VERSION "HNPBNNNYNNNNNNNNNNNNNNNNNNNNNNNNYNYYYYYYYY>4>%%%/4>'%**4YYY///"

NS_ :

BS_:

BU_: TPM TCM SCCM RF_HUB PTS ORC IC HaLF ETM ESM ESC EPS ECM Diagnost DTCM DASM CBC AFLS ADCM

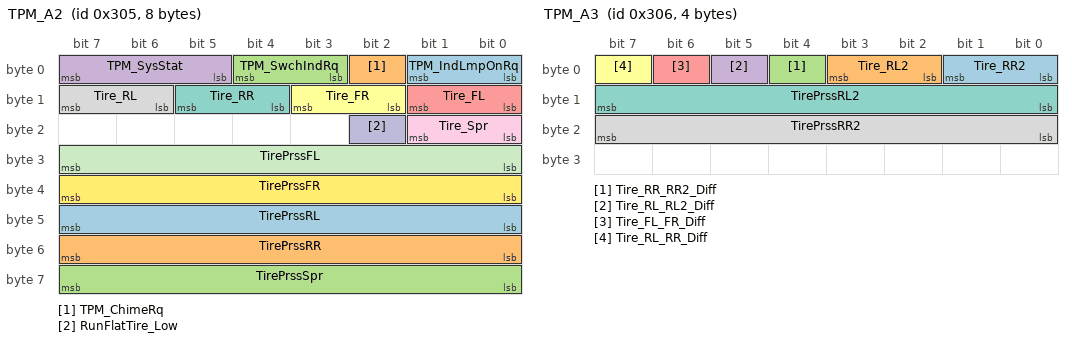
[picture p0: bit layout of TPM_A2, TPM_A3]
BO_ 773 TPM_A2: 8 RF_HUB
 SG_ TPM_IndLmpOnRq : 0|2@1+ (1,0) [0|0] ""  ORC,IC
 SG_ TPM_ChimeRq : 2|1@1+ (1,0) [0|0] ""  ORC,IC
 SG_ TPM_SwchIndRq : 3|2@1+ (1,0) [0|0] ""  ORC,IC
 SG_ TPM_SysStat : 5|3@1+ (1,0) [0|0] ""  ORC,IC
 SG_ Tire_FL : 8|2@1+ (1,0) [0|0] ""  ORC,IC
 SG_ Tire_FR : 10|2@1+ (1,0) [0|0] ""  ORC,IC
 SG_ Tire_RR : 12|2@1+ (1,0) [0|0] ""  ORC,IC
 SG_ Tire_RL : 14|2@1+ (1,0) [0|0] ""  ORC,IC
 SG_ Tire_Spr : 16|2@1+ (1,0) [0|0] ""  ORC,IC
 SG_ RunFlatTire_Low : 18|1@1+ (1,0) [0|0] ""  ORC,IC
 SG_ TirePrssFL : 24|8@1+ (1,0) [0|126] "psi"  ORC,IC
 SG_ TirePrssFR : 32|8@1+ (1,0) [0|126] "psi"  ORC,IC
 SG_ TirePrssRL : 40|8@1+ (1,0) [0|126] "psi"  ORC,IC
 SG_ TirePrssRR : 48|8@1+ (1,0) [0|126] "psi"  ORC,IC
 SG_ TirePrssSpr : 56|8@1+ (1,0) [0|126] "psi"  ORC,IC

BO_ 774 TPM_A3: 4 RF_HUB
 SG_ Tire_RR2 : 0|2@1+ (1,0) [0|0] ""  ORC,IC
 SG_ Tire_RL2 : 2|2@1+ (1,0) [0|0] ""  ORC,IC
 SG_ Tire_RR_RR2_Diff : 4|1@1+ (1,0) [0|0] ""  ORC,IC
 SG_ Tire_RL_RL2_Diff : 5|1@1+ (1,0) [0|0] ""  ORC,IC
 SG_ Tire_FL_FR_Diff : 6|1@1+ (1,0) [0|0] ""  ORC,IC
 SG_ Tire_RL_RR_Diff : 7|1@1+ (1,0) [0|0] ""  ORC,IC
 SG_ TirePrssRL2 : 8|8@1+ (1,0) [0|126] "psi"  ETM,ORC,IC
 SG_ TirePrssRR2 : 16|8@1+ (1,0) [0|126] "psi"  ETM,ORC,IC

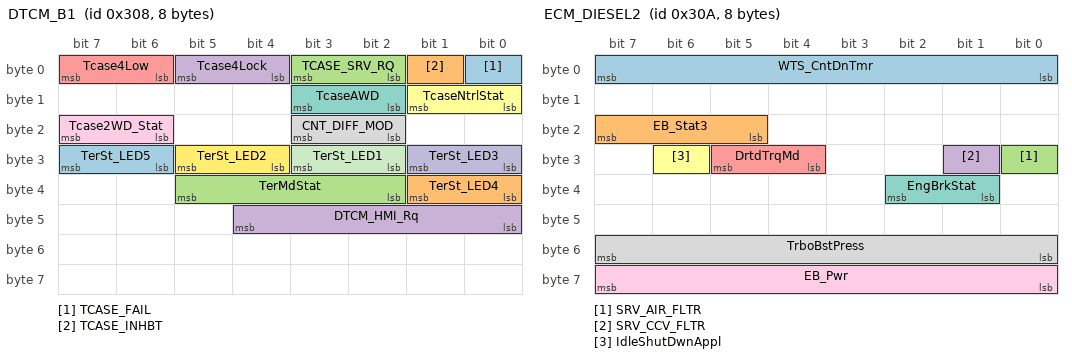
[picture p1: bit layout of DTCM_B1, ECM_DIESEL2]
BO_ 776 DTCM_B1: 8 CBC
 SG_ TCASE_FAIL : 0|1@1+ (1,0) [0|0] ""  ETM,ECM
 SG_ TCASE_INHBT : 1|1@1+ (1,0) [0|0] ""  ETM,IC
 SG_ TCASE_SRV_RQ : 2|2@1+ (1,0) [0|0] ""  ETM,IC
 SG_ Tcase4Lock : 4|2@1+ (1,0) [0|0] ""  ETM,ECM,IC,CBC
 SG_ Tcase4Low : 6|2@1+ (1,0) [0|0] ""  ETM,ECM,IC,CBC
 SG_ TcaseNtrlStat : 8|2@1+ (1,0) [0|0] ""  ETM,ECM,IC,CBC
 SG_ TcaseAWD : 10|2@1+ (1,0) [0|0] ""  ETM,ECM,IC,CBC
 SG_ CNT_DIFF_MOD : 18|2@1+ (1,0) [0|0] ""  ESC
 SG_ Tcase2WD_Stat : 22|2@1+ (1,0) [0|0] ""  ECM,IC,CBC
 SG_ TerSt_LED3 : 24|2@1+ (1,0) [0|0] ""  ETM,IC,CBC
 SG_ TerSt_LED1 : 26|2@1+ (1,0) [0|0] ""  ETM,IC,CBC
 SG_ TerSt_LED2 : 28|2@1+ (1,0) [0|0] ""  ETM,IC,CBC
 SG_ TerSt_LED5 : 30|2@1+ (1,0) [0|0] ""  ETM,IC,CBC
 SG_ TerSt_LED4 : 32|2@1+ (1,0) [0|0] ""  ETM,IC,CBC
 SG_ TerMdStat : 34|4@1+ (1,0) [0|0] ""  ETM,ADCM,TCM,ECM,DASM,ESC,IC,CBC
 SG_ DTCM_HMI_Rq : 40|5@1+ (1,0) [0|0] ""  ECM,IC

BO_ 778 ECM_DIESEL2: 8 Vector__XXX
 SG_ WTS_CntDnTmr : 0|8@1+ (1,0) [0|254] "sec"  IC
 SG_ EB_Stat3 : 21|3@1+ (1,0) [0|0] ""  IC,CBC
 SG_ SRV_AIR_FLTR : 24|1@1+ (1,0) [0|0] ""  IC
 SG_ SRV_CCV_FLTR : 25|1@1+ (1,0) [0|0] ""  IC
 SG_ DrtdTrqMd : 28|2@1+ (1,0) [0|0] ""  IC
 SG_ IdleShutDwnAppl : 30|1@1+ (1,0) [0|0] ""  IC
 SG_ EngBrkStat : 33|2@1+ (1,0) [0|0] ""  ECM
 SG_ TrboBstPress : 48|8@1+ (1,0) [0|250] "kPaG"  IC
 SG_ EB_Pwr : 56|8@1+ (1,0) [0|250] "kW"  IC

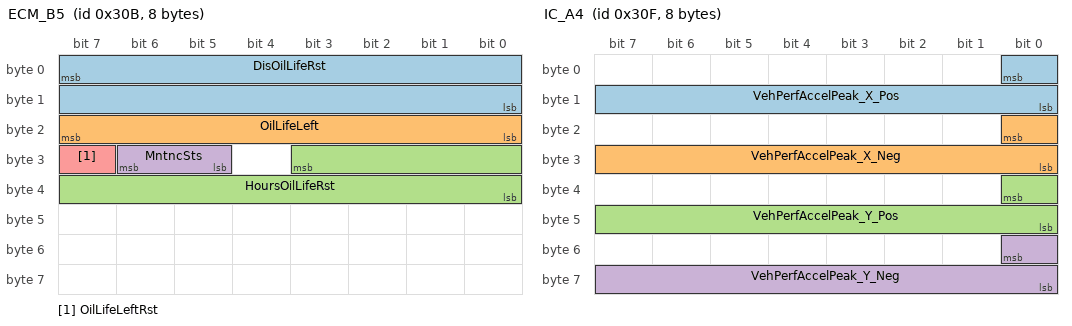
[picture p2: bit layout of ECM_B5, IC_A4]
BO_ 779 ECM_B5: 8 ECM
 SG_ DisOilLifeRst : 7|16@0+ (1,0) [0|65534] "km"  ETM,IC,CBC
 SG_ OilLifeLeft : 16|8@1+ (1,0) [0|100] "%"  ETM,IC
 SG_ HoursOilLifeRst : 27|12@0+ (1,0) [0|4000] "Hours"  ETM,IC,CBC
 SG_ MntncSts : 29|2@1+ (1,0) [0|0] ""  ETM,IC
 SG_ OilLifeLeftRst : 31|1@1+ (1,0) [0|0] ""  ETM,IC,CBC

BO_ 780 EPB_2M: 8 Vector__XXX
 SG_ ActualForce : 7|16@0+ (1,0) [0|65535] "daN"  ESC
 SG_ DiagSessActv : 16|1@1+ (1,0) [0|0] ""  ESC

BO_ 783 IC_A4: 8 IC
 SG_ VehPerfAccelPeak_X_Pos : 0|9@0+ (0.08,0) [0|40.8] "m/s²"  ETM
 SG_ VehPerfAccelPeak_X_Neg : 16|9@0+ (0.08,-40.8) [-40.8|0] "m/s²"  ETM
 SG_ VehPerfAccelPeak_Y_Pos : 32|9@0+ (0.08,0) [0|40.8] "m/s²"  ETM
 SG_ VehPerfAccelPeak_Y_Neg : 48|9@0+ (0.08,-40.8) [-40.8|0] "m/s²"  ETM

BO_ 784 IC_A1: 8 IC
 SG_ AvgFuelLvl : 0|9@0+ (0.5,0) [0|255] "liters"  ETM,ECM,CBC
 SG_ WarnPrio1_Mute_Rq : 1|1@1+ (1,0) [0|0] ""  CBC
 SG_ PCODE_CTRL : 2|2@1+ (1,0) [0|0] ""  ECM
 SG_ SRS_LMP_STAT : 4|2@1+ (1,0) [0|0] ""  ETM,ORC
 SG_ FuelLvlLow : 6|1@1+ (1,0) [0|0] ""  CBC
 SG_ WTS_LmpRqOn : 7|1@1+ (1,0) [0|0] "" Vector__XXX
 SG_ DPF_DEF_WrnStat : 16|4@1+ (1,0) [0|0] ""  ETM
 SG_ Radio_Strng_Rq : 20|1@1+ (1,0) [0|0] ""  CBC
 SG_ FuelSavDispEnbl : 21|1@1+ (1,0) [0|0] ""  CBC
 SG_ ThatchamIC : 22|1@1+ (1,0) [0|0] ""  RF_HUB
 SG_ ACC_ScrnActv : 23|1@1+ (1,0) [0|0] ""  DASM
 SG_ Trailer_Trp_Rst : 28|1@1+ (1,0) [0|0] "" Vector__XXX
 SG_ OilChgRst : 29|1@1+ (1,0) [0|0] ""  ECM
 SG_ FuelFltrRst : 30|1@1+ (1,0) [0|0] "" Vector__XXX
 SG_ ALM_Rq : 31|1@1+ (1,0) [0|0] "" Vector__XXX
 SG_ ODO : 39|24@0+ (0.1,0) [0|1677721.4] "km"  HaLF,ORC,ADCM,DTCM,ESM,TCM,ECM,DASM,ESC,SCCM,EPS,AFLS,TPM,PTS,CBC,RF_HUB
 SG_ PowerMode_RQ : 56|3@1+ (1,0) [0|0] ""  CBC
 SG_ IC_IntrnlFlt : 59|1@1+ (1,0) [0|0] ""  DASM
 SG_ PTS_MODE_SELECTION : 60|3@1+ (1,0) [0|0] ""  PTS

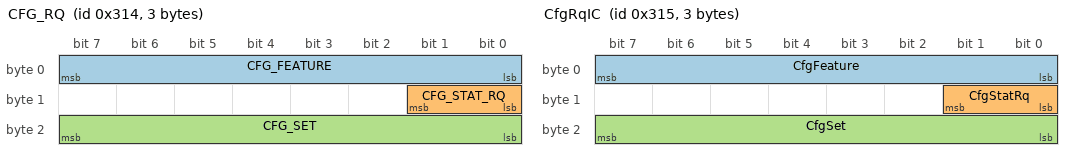
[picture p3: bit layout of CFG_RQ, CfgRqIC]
BO_ 788 CFG_RQ: 3 CBC
 SG_ CFG_FEATURE : 0|8@1+ (1,0) [0|0] ""  HaLF,ECM,DASM,ESC,EPS,AFLS,PTS,IC,RF_HUB
 SG_ CFG_STAT_RQ : 8|2@1+ (1,0) [0|0] ""  HaLF,ECM,DASM,ESC,EPS,AFLS,PTS,IC,RF_HUB
 SG_ CFG_SET : 16|8@1+ (1,0) [0|255] ""  EPS,HaLF,ECM,DASM,ESC,PTS,IC,RF_HUB

BO_ 789 CfgRqIC: 3 Vector__XXX
 SG_ CfgFeature : 0|8@1+ (1,0) [0|0] ""  ORC,AFLS,TPM,CBC
 SG_ CfgStatRq : 8|2@1+ (1,0) [0|0] ""  ORC,AFLS,TPM,CBC
 SG_ CfgSet : 16|8@1+ (1,0) [0|255] ""  AFLS,TPM

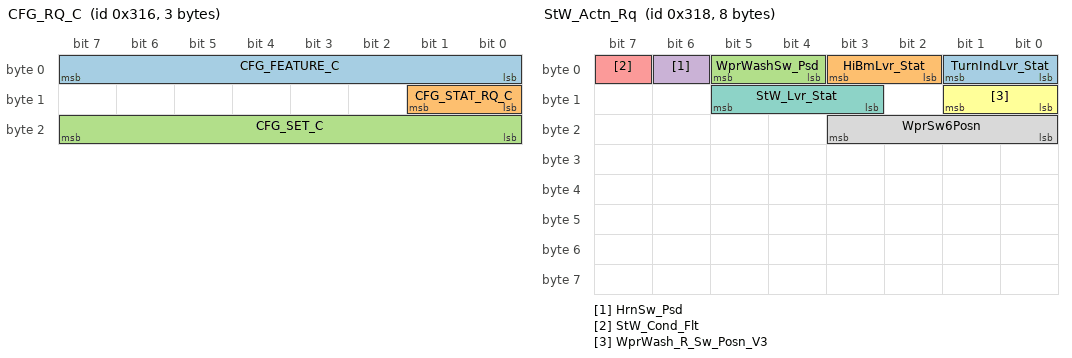
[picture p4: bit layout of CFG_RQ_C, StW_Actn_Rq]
BO_ 790 CFG_RQ_C: 3 IC
 SG_ CFG_FEATURE_C : 0|8@1+ (1,0) [0|0] ""  HaLF,ECM,DASM,ESC,EPS,AFLS,PTS,CBC,RF_HUB
 SG_ CFG_STAT_RQ_C : 8|2@1+ (1,0) [0|0] ""  HaLF,ECM,DASM,ESC,EPS,AFLS,PTS,CBC,RF_HUB
 SG_ CFG_SET_C : 16|8@1+ (1,0) [0|255] ""  EPS,HaLF,ECM,DASM,ESC,PTS,CBC,RF_HUB

BO_ 792 StW_Actn_Rq: 8 SCCM
 SG_ TurnIndLvr_Stat : 0|2@1+ (1,0) [0|0] ""  DASM,PTS,CBC
 SG_ HiBmLvr_Stat : 2|2@1+ (1,0) [0|0] ""  CBC
 SG_ WprWashSw_Psd : 4|2@1+ (1,0) [0|0] ""  AFLS,CBC
 SG_ HrnSw_Psd : 6|1@1+ (1,0) [0|0] ""  CBC
 SG_ StW_Cond_Flt : 7|1@1+ (1,0) [0|0] ""  CBC
 SG_ WprWash_R_Sw_Posn_V3 : 8|2@1+ (1,0) [0|0] ""  CBC
 SG_ StW_Lvr_Stat : 11|3@1+ (1,0) [0|0] ""  PTS,CBC
 SG_ WprSw6Posn : 16|4@1+ (1,0) [0|0] ""  DASM,CBC

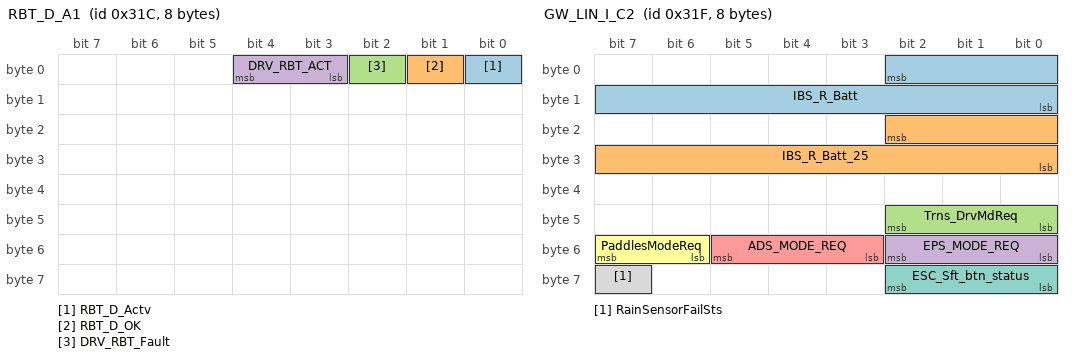
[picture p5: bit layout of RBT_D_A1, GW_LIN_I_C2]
BO_ 796 RBT_D_A1: 8 Vector__XXX
 SG_ RBT_D_Actv : 0|1@1+ (1,0) [0|0] ""  ESC
 SG_ RBT_D_OK : 1|1@1+ (1,0) [0|0] ""  DASM,ESC
 SG_ DRV_RBT_Fault : 2|1@1+ (1,0) [0|0] ""  IC
 SG_ DRV_RBT_ACT : 3|2@1+ (1,0) [0|0] ""  DASM,ESC

BO_ 799 GW_LIN_I_C2: 8 CBC
 SG_ IBS_R_Batt : 2|11@0+ (0.05,0) [0|20] "mOhm" Vector__XXX
 SG_ IBS_R_Batt_25 : 18|11@0+ (0.05,0) [0|20] "mOhm" Vector__XXX
 SG_ Trns_DrvMdReq : 40|3@1+ (1,0) [0|0] ""  TCM,IC
 SG_ EPS_MODE_REQ : 48|3@1+ (1,0) [0|0] ""  EPS,IC
 SG_ ADS_MODE_REQ : 51|3@1+ (1,0) [0|0] ""  ADCM,IC
 SG_ PaddlesModeReq : 54|2@1+ (1,0) [0|0] ""  TCM,IC
 SG_ ESC_Sft_btn_status : 56|3@1+ (1,0) [0|0] ""  ESC,IC
 SG_ RainSensorFailSts : 63|1@1+ (1,0) [0|0] ""  ETM,IC

BO_ 800 ECM_B9: 8 ECM
 SG_ PSI_Max_RPM : 3|5@1+ (250,500) [500|7500] "rpm"  ETM

BO_ 804 CBC_PT4: 8 CBC
 SG_ MOOD_LGT_INTS : 0|8@1+ (0.5,0) [0|100] "%"  IC
 SG_ WTS_Active : 8|1@1+ (1,0) [0|0] ""  RF_HUB
 SG_ CBC_WTS_AS : 9|1@1+ (1,0) [0|0] ""  IC
 SG_ HdAjar : 10|1@1+ (1,0) [0|0] "" Vector__XXX
 SG_ HdAjar_Rt : 11|1@1+ (1,0) [0|0] "" Vector__XXX
 SG_ LgtSensInt_Flt : 12|1@1+ (1,0) [0|0] ""  IC
 SG_ TurnLmp_FL_Flt : 13|1@1+ (1,0) [0|0] ""  IC
 SG_ TurnLmp_FR_Flt : 14|1@1+ (1,0) [0|0] ""  IC
 SG_ BrkPadWearStat : 15|1@1+ (1,0) [0|0] "" Vector__XXX
 SG_ AirSusp_UpSw : 16|2@1+ (1,0) [0|0] "" Vector__XXX
 SG_ AirSusp_DnSw : 18|2@1+ (1,0) [0|0] "" Vector__XXX
 SG_ DAY_LGT_Act : 20|1@1+ (1,0) [0|0] ""  HaLF,AFLS
 SG_ ExteriorRearReleaseSwitchSts : 21|1@1+ (1,0) [0|0] ""  RF_HUB
 SG_ SpStSwPsd : 22|2@1+ (1,0) [0|0] ""  ECM
 SG_ TurnLmp_RL_Flt : 24|1@1+ (1,0) [0|0] ""  IC
 SG_ TurnLmp_RR_Flt : 25|1@1+ (1,0) [0|0] ""  IC
 SG_ ACC_DLY_ACT : 26|1@1+ (1,0) [0|0] ""  SCCM,IC
 SG_ CargoLampOn : 27|1@1+ (1,0) [0|0] ""  IC
 SG_ HL_SW_Position : 28|2@1+ (1,0) [0|0] ""  HaLF
 SG_ ML_HDLP_LVL : 30|2@1+ (1,0) [0|0] "" Vector__XXX
 SG_ RemSt_Inhibit : 32|8@1+ (1,0) [0|0] ""  ETM,IC
 SG_ WPR_SYS_OFF : 40|1@1+ (1,0) [0|0] ""  HaLF,DTCM,DASM,ESC,AFLS
 SG_ WPR_SYS_LOW : 41|1@1+ (1,0) [0|0] ""  HaLF,DTCM,DASM,ESC,AFLS
 SG_ WPR_SYS_HIGH : 42|1@1+ (1,0) [0|0] ""  HaLF,DTCM,DASM,ESC,AFLS
 SG_ WPR_SYS_INT : 43|1@1+ (1,0) [0|0] ""  HaLF,DTCM,DASM,ESC,AFLS
 SG_ WPR_SYS_AUTO : 44|1@1+ (1,0) [0|0] ""  HaLF,DTCM,DASM,ESC,AFLS
 SG_ WPR_SYS_MIST : 45|1@1+ (1,0) [0|0] ""  HaLF,DTCM,DASM,ESC,AFLS
 SG_ WPR_SYS_WASH : 46|1@1+ (1,0) [0|0] ""  HaLF,DTCM,DASM,ESC,AFLS
 SG_ WPR_SYS_FLT : 47|1@1+ (1,0) [0|0] ""  HaLF,DTCM,DASM,ESC,AFLS
 SG_ Court_Lmp : 48|8@1+ (0.5,0) [0|100] "%"  RF_HUB
 SG_ DriveStyleSts : 56|3@1+ (1,0) [0|0] ""  IC
 SG_ DrvMdRq : 59|3@1+ (1,0) [0|0] ""  ORC,ADCM,DTCM,TCM
 SG_ ManMdRq : 62|2@1+ (1,0) [0|0] ""  TCM

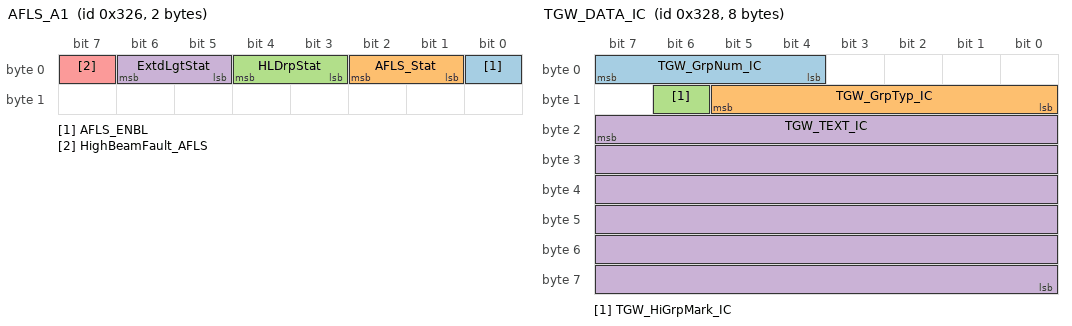
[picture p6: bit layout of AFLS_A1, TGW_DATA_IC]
BO_ 806 AFLS_A1: 2 AFLS
 SG_ AFLS_ENBL : 0|1@1+ (1,0) [0|0] ""  IC,CBC
 SG_ AFLS_Stat : 1|2@1+ (1,0) [0|0] ""  IC
 SG_ HLDrpStat : 3|2@1+ (1,0) [0|0] ""  IC,CBC
 SG_ ExtdLgtStat : 5|2@1+ (1,0) [0|0] "" Vector__XXX
 SG_ HighBeamFault_AFLS : 7|1@1+ (1,0) [0|0] ""  CBC

BO_ 808 TGW_DATA_IC: 8 CBC
 SG_ TGW_GrpNum_IC : 4|4@1+ (1,1) [1|16] "Group"  IC
 SG_ TGW_GrpTyp_IC : 8|6@1+ (1,0) [1|40] "Text"  IC
 SG_ TGW_HiGrpMark_IC : 14|1@1+ (1,0) [0|0] ""  IC
 SG_ TGW_TEXT_IC : 23|48@0+ (1,0) [0|0] ""  IC

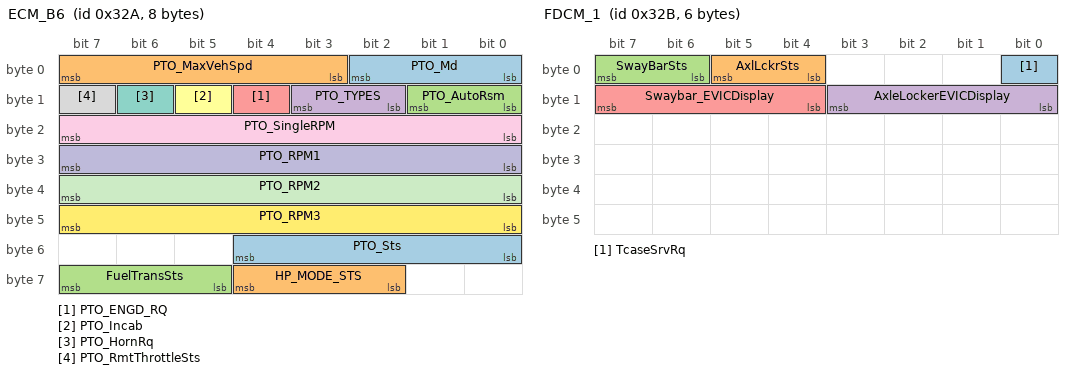
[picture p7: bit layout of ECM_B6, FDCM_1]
BO_ 810 ECM_B6: 8 ECM
 SG_ PTO_Md : 0|3@1+ (1,0) [0|0] ""  IC,CBC
 SG_ PTO_MaxVehSpd : 3|5@1+ (1,0) [0|0] ""  IC,CBC
 SG_ PTO_AutoRsm : 8|2@1+ (1,0) [0|0] ""  IC,CBC
 SG_ PTO_TYPES : 10|2@1+ (1,0) [0|0] ""  IC,CBC
 SG_ PTO_ENGD_RQ : 12|1@1+ (1,0) [0|0] ""  IC,CBC
 SG_ PTO_Incab : 13|1@1+ (1,0) [0|0] ""  IC,CBC
 SG_ PTO_HornRq : 14|1@1+ (1,0) [0|0] ""  CBC
 SG_ PTO_RmtThrottleSts : 15|1@1+ (1,0) [0|0] ""  IC,CBC
 SG_ PTO_SingleRPM : 16|8@1+ (25,600) [600|6950] "rpm"  IC,CBC
 SG_ PTO_RPM1 : 24|8@1+ (25,600) [600|6950] "rpm"  IC,CBC
 SG_ PTO_RPM2 : 32|8@1+ (25,600) [600|6950] "rpm"  IC,CBC
 SG_ PTO_RPM3 : 40|8@1+ (25,600) [600|6950] "rpm"  IC,CBC
 SG_ PTO_Sts : 48|5@1+ (1,0) [0|0] ""  IC,CBC
 SG_ HP_MODE_STS : 58|3@1+ (1,0) [0|0] ""  TCM,CBC
 SG_ FuelTransSts : 61|3@1+ (1,0) [0|0] ""  IC

BO_ 811 FDCM_1: 6 Vector__XXX
 SG_ TcaseSrvRq : 0|1@1+ (1,0) [0|0] ""  IC
 SG_ AxlLckrSts : 4|2@1+ (1,0) [0|0] ""  IC
 SG_ SwayBarSts : 6|2@1+ (1,0) [0|0] ""  IC
 SG_ AxleLockerEVICDisplay : 8|4@1+ (1,0) [0|0] ""  IC
 SG_ Swaybar_EVICDisplay : 12|4@1+ (1,0) [0|0] ""  IC

BO_ 816 GW_I_C1: 8 CBC
 SG_ PLG_Stat : 0|4@1+ (1,0) [0|0] ""  IC
 SG_ DL_Lim_Stat : 4|2@1+ (1,0) [0|0] ""  IC
 SG_ TILT_IN_REV_D : 6|1@1+ (1,0) [0|0] ""  IC
 SG_ TILT_IN_REV_P : 7|1@1+ (1,0) [0|0] ""  IC
 SG_ EModeSwPsd : 8|2@1+ (1,0) [0|0] ""  TCM,ECM
 SG_ EB_SW_PSD : 10|1@1+ (1,0) [0|0] "" Vector__XXX
 SG_ CHIME_STS_RF : 11|1@1+ (1,0) [0|0] ""  DASM,PTS
 SG_ CHIME_STS_LF : 12|1@1+ (1,0) [0|0] ""  DASM,PTS
 SG_ CHIME_STS_RR : 13|1@1+ (1,0) [0|0] ""  DASM,PTS
 SG_ CHIME_STS_LR : 14|1@1+ (1,0) [0|0] ""  DASM,PTS
 SG_ ADCM_Sw_Psd : 15|1@1+ (1,0) [0|0] ""  ADCM,PTS
 SG_ TCASE_SFT_RQ : 16|3@1+ (1,0) [0|0] ""  DTCM,PTS
 SG_ TRAC_PSD : 19|1@1+ (1,0) [0|0] ""  ESC,PTS
 SG_ HILL_DES_RQ : 20|2@1+ (1,0) [0|0] ""  ESC
 SG_ AddTurnLmp_Flt_D : 22|1@1+ (1,0) [0|0] ""  IC
 SG_ AddTurnLmp_Flt_P : 23|1@1+ (1,0) [0|0] ""  IC
 SG_ US_METRIC : 24|1@1+ (1,0) [0|0] ""  ECM,DASM,IC
 SG_ LANG : 25|4@1+ (1,0) [0|0] ""  IC
 SG_ PLG_Req_PE : 31|1@1+ (1,0) [0|0] ""  RF_HUB
 SG_ TGW_DISP_STAT : 32|4@1+ (1,0) [0|0] ""  IC
 SG_ AHB_ENBL : 36|1@1+ (1,0) [0|0] ""  IC
 SG_ PassWinLO_Enbl : 37|1@1+ (1,0) [0|0] ""  IC
 SG_ RemStEnbl_DCS : 38|1@1+ (1,0) [0|0] ""  IC
 SG_ RemStNrmlStEnbl_DCS : 39|1@1+ (1,0) [0|0] ""  IC
 SG_ HVAC_CLNT_FLW_MIN : 40|8@1+ (0.521555,0) [0|132.475] "LpM"  ECM
 SG_ ICS_btn41 : 48|2@1+ (1,0) [0|0] ""  TCM
 SG_ ICS_btn_34 : 50|1@1+ (1,0) [0|0] ""  ECM
 SG_ ICS_btn_16 : 51|1@1+ (1,0) [0|0] ""  PTS
 SG_ ICS_btn_17 : 52|1@1+ (1,0) [0|0] ""  PTS
 SG_ ICS_btn_18 : 53|1@1+ (1,0) [0|0] "" Vector__XXX
 SG_ ICS_btn_19 : 54|1@1+ (1,0) [0|0] ""  DASM
 SG_ DriveModeReq_Cluster : 56|4@1+ (1,0) [0|0] ""  IC

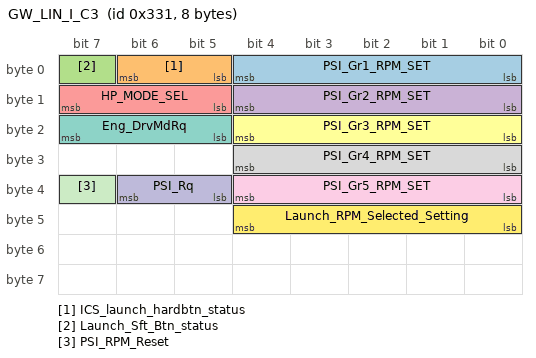
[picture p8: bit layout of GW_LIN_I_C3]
BO_ 817 GW_LIN_I_C3: 8 CBC
 SG_ PSI_Gr1_RPM_SET : 0|5@1+ (250,500) [500|7500] "rpm"  ECM
 SG_ ICS_launch_hardbtn_status : 5|2@1+ (1,0) [0|0] ""  ESC
 SG_ Launch_Sft_Btn_status : 7|1@1+ (1,0) [0|0] ""  ESC
 SG_ PSI_Gr2_RPM_SET : 8|5@1+ (250,500) [500|7500] "rpm"  ECM
 SG_ HP_MODE_SEL : 13|3@1+ (1,0) [0|0] ""  ECM,IC
 SG_ PSI_Gr3_RPM_SET : 16|5@1+ (250,500) [500|7500] "rpm"  ECM
 SG_ Eng_DrvMdRq : 21|3@1+ (1,0) [0|0] ""  ECM
 SG_ PSI_Gr4_RPM_SET : 24|5@1+ (250,500) [500|7500] "rpm"  ECM
 SG_ PSI_Gr5_RPM_SET : 32|5@1+ (250,500) [500|7500] "rpm"  ECM
 SG_ PSI_Rq : 37|2@1+ (1,0) [0|0] ""  ECM
 SG_ PSI_RPM_Reset : 39|1@1+ (1,0) [0|0] ""  ECM
 SG_ Launch_RPM_Selected_Setting : 40|5@1+ (250,1000) [1000|7000] "rpm"  ESC

CM_ SG_ 773 TPM_IndLmpOnRq "Tire pressure indication request";
CM_ SG_ 773 TPM_ChimeRq "TPM chime request";
CM_ SG_ 773 TPM_SwchIndRq "TPM load switch indicator request";
CM_ SG_ 773 TPM_SysStat "TPM system localization status";
CM_ SG_ 773 Tire_FL "Tire front left";
CM_ SG_ 773 Tire_FR "Tire front right";
CM_ SG_ 773 Tire_RR "Tire rear right";
CM_ SG_ 773 Tire_RL "Tire rear left";
CM_ SG_ 773 Tire_Spr "Spare tire";
CM_ SG_ 773 RunFlatTire_Low "Run flat tire low pressure; true = [1]";
CM_ SG_ 773 TirePrssFL "Tire pressure front left";
CM_ SG_ 773 TirePrssFR "Tire pressure front right";
CM_ SG_ 773 TirePrssRL "Tire pressure rear left";
CM_ SG_ 773 TirePrssRR "Tire pressure rear right";
CM_ SG_ 773 TirePrssSpr "Tire pressure spare tire";
CM_ SG_ 774 Tire_RR2 "Tire rear right inside on dually";
CM_ SG_ 774 Tire_RL2 "Tire rear left inside on dually";
CM_ SG_ 774 Tire_RR_RR2_Diff "Tire pressure differential rear right inner to outer";
CM_ SG_ 774 Tire_RL_RL2_Diff "Tire pressure differential rear left inner to outer";
CM_ SG_ 774 Tire_FL_FR_Diff "Tire pressure differential front left to front right";
CM_ SG_ 774 Tire_RL_RR_Diff "Tire pressure differential rear left to rear right";
CM_ SG_ 774 TirePrssRL2 "Tire pressure rear left inside on dually";
CM_ SG_ 774 TirePrssRR2 "Tire pressure rear right inside on dually";
CM_ SG_ 776 TCASE_FAIL "T Case System Fault (Limp in)";
CM_ SG_ 776 TCASE_INHBT "All wheel drive mode inhibited";
CM_ SG_ 776 TCASE_SRV_RQ "Transfer case service indicator request";
CM_ SG_ 776 Tcase4Lock "Transfer case 4WD locked status";
CM_ SG_ 776 Tcase4Low "Transfer case low range LED status";
CM_ SG_ 776 TcaseNtrlStat "Transfer case neutral LED status";
CM_ SG_ 776 TcaseAWD "Transfer case High range / AWD LED status";
CM_ SG_ 776 CNT_DIFF_MOD "Actual mode of center differential";
CM_ SG_ 776 Tcase2WD_Stat "Transfer case 2 wheel drive status";
CM_ SG_ 776 TerSt_LED3 "Terrain Switch LED 3 Status";
CM_ SG_ 776 TerSt_LED1 "Terrain Switch LED 1 (left / counterclockwise most) Status";
CM_ SG_ 776 TerSt_LED2 "Terrain Switch LED 2 Status";
CM_ SG_ 776 TerSt_LED5 "Terrain Switch LED 5 (right / clockwise most) Status";
CM_ SG_ 776 TerSt_LED4 "Terrain Switch LED 4 Status";
CM_ SG_ 776 TerMdStat "Terrain mode status";
CM_ SG_ 776 DTCM_HMI_Rq "DTCM AWD / 4WD HMI display request";
CM_ SG_ 778 WTS_CntDnTmr "Wait to start count down timer (sec)";
CM_ SG_ 778 EB_Stat3 "Exhaust brake status - 3 bit";
CM_ SG_ 778 SRV_AIR_FLTR "Service air Filter";
CM_ SG_ 778 SRV_CCV_FLTR "Service CCV Filter";
CM_ SG_ 778 DrtdTrqMd "Derated torque mode";
CM_ SG_ 778 IdleShutDwnAppl "Idle Shut down applied";
CM_ SG_ 778 EngBrkStat "Engine braking status";
CM_ SG_ 778 TrboBstPress "Turbo boost pressure";
CM_ SG_ 778 EB_Pwr "Exhaust brake Power";
CM_ SG_ 779 DisOilLifeRst "Distance since last oil life reset";
CM_ SG_ 779 OilLifeLeft "Oil life left";
CM_ SG_ 779 HoursOilLifeRst "Hours since last oil life reset";
CM_ SG_ 779 MntncSts "Maintenance reminder status";
CM_ SG_ 779 OilLifeLeftRst "Oil life remaining has been reset";
CM_ SG_ 780 ActualForce "Actual force";
CM_ SG_ 780 DiagSessActv "Diagnostic session active; Active = [1]";
CM_ SG_ 783 VehPerfAccelPeak_X_Pos "Vehicle longitudinal acceleration peak (forward)";
CM_ SG_ 783 VehPerfAccelPeak_X_Neg "Vehicle longitudinal acceleration peak (rearward)";
CM_ SG_ 783 VehPerfAccelPeak_Y_Pos "Vehicle longitudinal acceleration peak (left)";
CM_ SG_ 783 VehPerfAccelPeak_Y_Neg "Vehicle longitudinal acceleration peak (right)";
CM_ SG_ 784 AvgFuelLvl "Average filtered fuel level in liters";
CM_ SG_ 784 WarnPrio1_Mute_Rq "Priority 1 mute request for soundamplifier";
CM_ SG_ 784 PCODE_CTRL "P-Code control signal from CCN";
CM_ SG_ 784 SRS_LMP_STAT "Airbag indicator lamp status";
CM_ SG_ 784 FuelLvlLow "Fuel level low";
CM_ SG_ 784 WTS_LmpRqOn "Wait to start lamp requested on; true = [1]";
CM_ SG_ 784 DPF_DEF_WrnStat "DPF DEF warning status";
CM_ SG_ 784 Radio_Strng_Rq "IC request for Audio to resend radio string information";
CM_ SG_ 784 FuelSavDispEnbl "Fuel saver display indicator status (1=enabled)";
CM_ SG_ 784 ThatchamIC "IC has learned the presence of Thatcham; true = [1]";
CM_ SG_ 784 ACC_ScrnActv "IC adaptive cruise in active display; True = [1]";
CM_ SG_ 784 Trailer_Trp_Rst "Trailer Trip Reset Request";
CM_ SG_ 784 OilChgRst "Oil change reminder reset request";
CM_ SG_ 784 FuelFltrRst "Fuel filter maintenance reminder reset";
CM_ SG_ 784 ALM_Rq "Auto load measurement request; On = [1]";
CM_ SG_ 784 ODO "Odometer";
CM_ SG_ 784 PowerMode_RQ "Power Mode request";
CM_ SG_ 784 IC_IntrnlFlt "Cluster internal fault active";
CM_ SG_ 784 PTS_MODE_SELECTION "Park assist maneuver selection for PTS";
CM_ SG_ 788 CFG_FEATURE "Configurable feature";
CM_ SG_ 788 CFG_STAT_RQ "Configurable feature status request";
CM_ SG_ 788 CFG_SET "Specific setting or value (see reference)";
CM_ SG_ 789 CfgFeature "Configurable feature";
CM_ SG_ 789 CfgStatRq "Configurable feature status request";
CM_ SG_ 789 CfgSet "Specific setting or value (see reference)";
CM_ SG_ 790 CFG_FEATURE_C "Configurable feature";
CM_ SG_ 790 CFG_STAT_RQ_C "Configurable feature status request";
CM_ SG_ 790 CFG_SET_C "Specific setting or value (see reference)";
CM_ SG_ 792 TurnIndLvr_Stat "Turn indicator lever state";
CM_ SG_ 792 HiBmLvr_Stat "High beam lever state";
CM_ SG_ 792 WprWashSw_Psd "Front wiper switch pressed";
CM_ SG_ 792 HrnSw_Psd "Horn switch pressed (1=pressed)";
CM_ SG_ 792 StW_Cond_Flt "Steering wheel conditioning fault";
CM_ SG_ 792 WprWash_R_Sw_Posn_V3 "Backlite wiper/washer switch position";
CM_ SG_ 792 StW_Lvr_Stat "Steering wheel lever state";
CM_ SG_ 792 WprSw6Posn "Wiper switch (6 stages) position";
CM_ SG_ 796 RBT_D_Actv "Reversible belt tensioner driver active; True = [1]";
CM_ SG_ 796 RBT_D_OK "Reversible belt tensioner driver is OK; True = [1]";
CM_ SG_ 796 DRV_RBT_Fault "Driver's RBT has a fault or failure; True = [1]";
CM_ SG_ 796 DRV_RBT_ACT "Indicates the pre-pretensioner is activated either by the DASM or ESC";
CM_ SG_ 799 IBS_R_Batt "Calculated battery resistance";
CM_ SG_ 799 IBS_R_Batt_25 "Batt resistance at 100% SOC and 25 degC";
CM_ SG_ 799 Trns_DrvMdReq "The requested state of the drive mode feature";
CM_ SG_ 799 EPS_MODE_REQ "EPS mode personalization request";
CM_ SG_ 799 ADS_MODE_REQ "Active damping system mode personalization request";
CM_ SG_ 799 PaddlesModeReq "Requested state of paddle lock-out function";
CM_ SG_ 799 ESC_Sft_btn_status "ESC mode personalization request";
CM_ SG_ 799 RainSensorFailSts "Fail present = 1";
CM_ SG_ 800 PSI_Max_RPM "Maximum selectable RPM for PSI feature";
CM_ SG_ 804 MOOD_LGT_INTS "Mood lighting intensity (ambient & glow rings)";
CM_ SG_ 804 WTS_Active "Indicates WTS feature is active";
CM_ SG_ 804 CBC_WTS_AS "WTS automatic start is active";
CM_ SG_ 804 HdAjar "Hood latch ajar, left or single (1=ajar)";
CM_ SG_ 804 HdAjar_Rt "Hood latch ajar, right (1=ajar)";
CM_ SG_ 804 LgtSensInt_Flt "Light sensor internal fault";
CM_ SG_ 804 TurnLmp_FL_Flt "Turn indication lamp front left fault";
CM_ SG_ 804 TurnLmp_FR_Flt "Turn indication lamp front right fault";
CM_ SG_ 804 BrkPadWearStat "Disable fuel shutoff";
CM_ SG_ 804 AirSusp_UpSw "Air suspension up switch status";
CM_ SG_ 804 AirSusp_DnSw "Air suspension down (Trailer) switch status";
CM_ SG_ 804 DAY_LGT_Act "Day light actual (based on light sensor input)";
CM_ SG_ 804 ExteriorRearReleaseSwitchSts "Exterior rear release switch status";
CM_ SG_ 804 SpStSwPsd "Stop start switch pressed";
CM_ SG_ 804 TurnLmp_RL_Flt "Turn indication lamp rear left fault";
CM_ SG_ 804 TurnLmp_RR_Flt "Turn indication lamp rear right fault";
CM_ SG_ 804 ACC_DLY_ACT "Accessory Delay Active";
CM_ SG_ 804 CargoLampOn "Cargo lamp is on";
CM_ SG_ 804 HL_SW_Position "Actual headlamp switch position";
CM_ SG_ 804 ML_HDLP_LVL "Manual headlamp leveling";
CM_ SG_ 804 RemSt_Inhibit "Remote start inhibit";
CM_ SG_ 804 WPR_SYS_OFF "Wiper system off; [1] = switch is OFF";
CM_ SG_ 804 WPR_SYS_LOW "Wiper system low; [1] = switch is LOW";
CM_ SG_ 804 WPR_SYS_HIGH "Wiper system high; [1] = switch is HIGH";
CM_ SG_ 804 WPR_SYS_INT "Wiper system intermittent; [1] = switch is INT";
CM_ SG_ 804 WPR_SYS_AUTO "Wiper system auto; [1] = Auto wipers equipped";
CM_ SG_ 804 WPR_SYS_MIST "Wiper system mist; [1] = mist request";
CM_ SG_ 804 WPR_SYS_WASH "Wiper system wash; [1] = wash request";
CM_ SG_ 804 WPR_SYS_FLT "Wiper system fault present; [1] = fault present";
CM_ SG_ 804 Court_Lmp "Courtesy lamp percentage";
CM_ SG_ 804 DriveStyleSts "Drive style status";
CM_ SG_ 804 DrvMdRq "Drive mode request";
CM_ SG_ 804 ManMdRq "Manual shift mode request switch status";
CM_ SG_ 806 AFLS_ENBL "Advanced lighting enabled; [0] = no, [1] = yes";
CM_ SG_ 806 AFLS_Stat "AFLS fault status";
CM_ SG_ 806 HLDrpStat "Headlamp drop status";
CM_ SG_ 806 ExtdLgtStat "Extended lighting status";
CM_ SG_ 806 HighBeamFault_AFLS "High Beam or Shutter Fault; 1 = High beam fault present";
CM_ SG_ 808 TGW_GrpNum_IC "TGW group number to IC";
CM_ SG_ 808 TGW_GrpTyp_IC "Group type to send text data from TGW to IC";
CM_ SG_ 808 TGW_HiGrpMark_IC "TGW high group mark to IC; [0] = Not True, [1] = True";
CM_ SG_ 808 TGW_TEXT_IC "TGW text string information to IC";
CM_ SG_ 810 PTO_Md "PTO mode selected";
CM_ SG_ 810 PTO_MaxVehSpd "PTO maximum vehicle speed";
CM_ SG_ 810 PTO_AutoRsm "PTO - resume on ignition on";
CM_ SG_ 810 PTO_TYPES "PTO type selected";
CM_ SG_ 810 PTO_ENGD_RQ "Power takeoff engage request";
CM_ SG_ 810 PTO_Incab "Power takeoff - in cab switch status; On = [1]";
CM_ SG_ 810 PTO_HornRq "Power ake Off HORN ON Request; On = 1";
CM_ SG_ 810 PTO_RmtThrottleSts "PTO remote throttle status: enabled=[1]";
CM_ SG_ 810 PTO_SingleRPM "PTO single set RPM";
CM_ SG_ 810 PTO_RPM1 "PTO preset 1 RPM setting";
CM_ SG_ 810 PTO_RPM2 "PTO preset 2 RPM setting";
CM_ SG_ 810 PTO_RPM3 "PTO preset 3 RPM setting";
CM_ SG_ 810 PTO_Sts "PTO warning status";
CM_ SG_ 810 HP_MODE_STS "Engine power mode personalization status";
CM_ SG_ 810 FuelTransSts "Fuel transfer status";
CM_ SG_ 811 TcaseSrvRq "Final drive service request";
CM_ SG_ 811 AxlLckrSts "Axle locker status";
CM_ SG_ 811 SwayBarSts "Swaybar status";
CM_ SG_ 811 AxleLockerEVICDisplay "Axle locker HMI display request";
CM_ SG_ 811 Swaybar_EVICDisplay "Swaybar HMI display request";
CM_ SG_ 816 PLG_Stat "Power liftgate status";
CM_ SG_ 816 DL_Lim_Stat "Deck lid limit state";
CM_ SG_ 816 TILT_IN_REV_D "Tilt in reverese feature enabled; [0] = no, [1] = yes";
CM_ SG_ 816 TILT_IN_REV_P "Tilt in reverese feature enabled; [0] = no, [1] = yes";
CM_ SG_ 816 EModeSwPsd "E-Mode switch pressed";
CM_ SG_ 816 EB_SW_PSD "Exhaust brake switch pressed (1=pressed)";
CM_ SG_ 816 CHIME_STS_RF "Chime status - right front; speaker not functional = [1]";
CM_ SG_ 816 CHIME_STS_LF "Chime status - left front; speaker not functional = [1]";
CM_ SG_ 816 CHIME_STS_RR "Chime status - right rear; speaker not functional = [1]";
CM_ SG_ 816 CHIME_STS_LR "Chime status - left rear; speaker not functional = [1]";
CM_ SG_ 816 ADCM_Sw_Psd "Active damping control module switch pressed";
CM_ SG_ 816 TCASE_SFT_RQ "Transfer case shift request";
CM_ SG_ 816 TRAC_PSD "Traction on/off button pressed; [0] = Not Pressed, [1] = Pressed";
CM_ SG_ 816 HILL_DES_RQ "Hill descent or select speed status";
CM_ SG_ 816 AddTurnLmp_Flt_D "Additional turn indication lamp fault - driver side";
CM_ SG_ 816 AddTurnLmp_Flt_P "Additional turn indication lamp fault - passenger side";
CM_ SG_ 816 US_METRIC "US = [0], metric = [1]";
CM_ SG_ 816 LANG "Language preference";
CM_ SG_ 816 PLG_Req_PE "Power Liftgate Requesting PE unlatch";
CM_ SG_ 816 TGW_DISP_STAT "TGW Display status";
CM_ SG_ 816 AHB_ENBL "Auto highbeam enable";
CM_ SG_ 816 PassWinLO_Enbl "Passenger window locked out enabled";
CM_ SG_ 816 RemStEnbl_DCS "Driver comfort system remote start status; [0] = Off, [1] = On";
CM_ SG_ 816 RemStNrmlStEnbl_DCS "Driver comfort system remote & normal start status; [0] = Off, [1] = On";
CM_ SG_ 816 HVAC_CLNT_FLW_MIN "HVAC coolant flow minimum request";
CM_ SG_ 816 ICS_btn41 "Emode button status";
CM_ SG_ 816 ICS_btn_34 "Stop/Start pressed";
CM_ SG_ 816 ICS_btn_16 "PPA pressed";
CM_ SG_ 816 ICS_btn_17 "PTS Off pressed";
CM_ SG_ 816 ICS_btn_18 "LDW Off pressed";
CM_ SG_ 816 ICS_btn_19 "FCW Off pressed; True = [1]";
CM_ SG_ 816 DriveModeReq_Cluster "Drive mode request to cluster";
CM_ SG_ 817 PSI_Gr1_RPM_SET "Requested rpm set point for Performance Shift Indication; 500 indicates not set";
CM_ SG_ 817 ICS_launch_hardbtn_status "Launch hard button status";
CM_ SG_ 817 Launch_Sft_Btn_status "Launch - soft button status; Launch on = [1]";
CM_ SG_ 817 PSI_Gr2_RPM_SET "Requested rpm set point for Performance Shift Indication; 500 indicates not set";
CM_ SG_ 817 HP_MODE_SEL "Engine power mode personalization request";
CM_ SG_ 817 PSI_Gr3_RPM_SET "Requested rpm set point for Performance Shift Indication; 500 indicates not set";
CM_ SG_ 817 Eng_DrvMdRq "Engine drive mode personalization request";
CM_ SG_ 817 PSI_Gr4_RPM_SET "Requested rpm set point for Performance Shift Indication; 500 indicates not set";
CM_ SG_ 817 PSI_Gr5_RPM_SET "Requested rpm set point for Performance Shift Indication; 500 indicates not set";
CM_ SG_ 817 PSI_Rq "Performance shift indication request";
CM_ SG_ 817 PSI_RPM_Reset "Reset performance shift indication RPM set points to default;  Reset = [1]";
CM_ SG_ 817 Launch_RPM_Selected_Setting "Soft button driver selected RPM setting";
BA_DEF_ SG_  "GenSigTimeout_ADCM" INT 0 65535;
BA_DEF_ SG_  "GenSigTimeout_AFLS" INT 0 65535;
BA_DEF_ SG_  "GenSigTimeout_CBC" INT 0 65535;
BA_DEF_ SG_  "GenSigTimeout_DTCM" INT 0 65535;
BA_DEF_ SG_  "GenSigTimeout_ECM" INT 0 65535;
BA_DEF_ SG_  "GenSigTimeout_EPS" INT 0 65535;
BA_DEF_ SG_  "GenSigTimeout_ESC" INT 0 65535;
BA_DEF_ SG_  "GenSigTimeout_ESM" INT 0 65535;
BA_DEF_ SG_  "GenSigTimeout_ETM" INT 0 65535;
BA_DEF_ SG_  "GenSigTimeout_HaLF" INT 0 65535;
BA_DEF_ SG_  "GenSigTimeout_IC" INT 0 65535;
BA_DEF_ SG_  "GenSigTimeout_ORC" INT 0 65535;
BA_DEF_ SG_  "GenSigTimeout_PTS" INT 0 65535;
BA_DEF_ SG_  "GenSigTimeout_RF_HUB" INT 0 65535;
BA_DEF_ SG_  "GenSigTimeout_SCCM" INT 0 65535;
BA_DEF_ SG_  "GenSigTimeout_TPM" INT 0 65535;
BA_DEF_ BO_  "GenMsgStartValue" STRING ;
BA_DEF_ SG_  "GenSigSNA" STRING ;
BA_DEF_ SG_  "FlexKomIsMotorola" ENUM  "nein","ja";
BA_DEF_ SG_  "FlexKomSigLaenge" INT 0 64;
BA_DEF_ SG_  "FlexKomSigStartPos" INT 0 63;
BA_DEF_ SG_  "FlexKomComment" STRING ;
BA_DEF_ SG_  "FlexKomSigName" STRING ;
BA_DEF_ SG_  "FlexKomSID" INT 0 2147483647;
BA_DEF_ SG_  "GenSigStartValue" HEX 0 4294967295;
BA_DEF_ SG_  "FlexKomSigStartValue" STRING ;
BA_DEF_ SG_  "GenSigCycleTimeActive" INT 0 65535;
BA_DEF_ SG_  "GenSigCycleTime" INT 0 65535;
BA_DEF_ SG_  "GenSigSendType" ENUM  "cyclicX","spontanX","cyclicIfActiveX","spontanWithDelay","cyclicAndSpontanX","cyclicAndSpontanWithDelay","spontanWithRepitition","cyclicIfActiveAndSpontanWD","cyclicIfActiveFast","cyclicWithRepeatOnDemand","none";
BA_DEF_ BO_  "GenMsgNrOfRepetitions" INT 0 65535;
BA_DEF_ BO_  "GenMsgDelayTime" INT 0 65535;
BA_DEF_ BO_  "GenMsgStartDelayTime" INT 0 65535;
BA_DEF_ BO_  "GenMsgCycleTimeActive" INT 0 65535;
BA_DEF_ BO_  "GenMsgCycleTime" INT 0 65535;
BA_DEF_ BO_  "GenMsgSendType" ENUM  "cyclicX","spontanX","cyclicIfActiveX","spontanWithDelay","cyclicAndSpontanX","cyclicAndSpontanWithDelay","spontanWithRepitition","cyclicIfActiveAndSpontanWD","cyclicIfActiveFast","cyclicWithRepeatOnDemand","none";
BA_DEF_ BO_  "DiagResponse" ENUM  "nein","ja";
BA_DEF_ BO_  "DiagRequest" ENUM  "nein","ja";
BA_DEF_ BO_  "DiagState" ENUM  "nein","ja";
BA_DEF_ BO_  "App-Botschaft" ENUM  "nein","ja";
BA_DEF_ BO_  "NWM-Botschaft" ENUM  "nein","ja";
BA_DEF_DEF_  "GenSigTimeout_ADCM" 0;
BA_DEF_DEF_  "GenSigTimeout_AFLS" 0;
BA_DEF_DEF_  "GenSigTimeout_CBC" 0;
BA_DEF_DEF_  "GenSigTimeout_DTCM" 0;
BA_DEF_DEF_  "GenSigTimeout_ECM" 0;
BA_DEF_DEF_  "GenSigTimeout_EPS" 0;
BA_DEF_DEF_  "GenSigTimeout_ESC" 0;
BA_DEF_DEF_  "GenSigTimeout_ESM" 0;
BA_DEF_DEF_  "GenSigTimeout_ETM" 0;
BA_DEF_DEF_  "GenSigTimeout_HaLF" 0;
BA_DEF_DEF_  "GenSigTimeout_IC" 0;
BA_DEF_DEF_  "GenSigTimeout_ORC" 0;
BA_DEF_DEF_  "GenSigTimeout_PTS" 0;
BA_DEF_DEF_  "GenSigTimeout_RF_HUB" 0;
BA_DEF_DEF_  "GenSigTimeout_SCCM" 0;
BA_DEF_DEF_  "GenSigTimeout_TPM" 0;
BA_DEF_DEF_  "GenMsgStartValue" "";
BA_DEF_DEF_  "GenSigSNA" "";
BA_DEF_DEF_  "FlexKomIsMotorola" "nein";
BA_DEF_DEF_  "FlexKomSigLaenge" 0;
BA_DEF_DEF_  "FlexKomSigStartPos" 0;
BA_DEF_DEF_  "FlexKomComment" "";
BA_DEF_DEF_  "FlexKomSigName" "";
BA_DEF_DEF_  "FlexKomSID" 0;
BA_DEF_DEF_  "GenSigStartValue" 0;
BA_DEF_DEF_  "FlexKomSigStartValue" "";
BA_DEF_DEF_  "GenSigCycleTimeActive" 0;
BA_DEF_DEF_  "GenSigCycleTime" 0;
BA_DEF_DEF_  "GenSigSendType" "cyclicX";
BA_DEF_DEF_  "GenMsgNrOfRepetitions" 0;
BA_DEF_DEF_  "GenMsgDelayTime" 0;
BA_DEF_DEF_  "GenMsgStartDelayTime" 0;
BA_DEF_DEF_  "GenMsgCycleTimeActive" 0;
BA_DEF_DEF_  "GenMsgCycleTime" 0;
BA_DEF_DEF_  "GenMsgSendType" "cyclicX";
BA_DEF_DEF_  "DiagResponse" "nein";
BA_DEF_DEF_  "DiagRequest" "nein";
BA_DEF_DEF_  "DiagState" "nein";
BA_DEF_DEF_  "App-Botschaft" "nein";
BA_DEF_DEF_  "NWM-Botschaft" "nein";
BA_ "GenMsgCycleTime" BO_ 773 1000;
BA_ "GenMsgDelayTime" BO_ 773 20;
BA_ "GenMsgNrOfRepetitions" BO_ 773 2;
BA_ "GenMsgStartValue" BO_ 773 "000000FFFFFFFFFFh";
BA_ "GenMsgCycleTime" BO_ 774 1000;
BA_ "GenMsgDelayTime" BO_ 774 20;
BA_ "GenMsgNrOfRepetitions" BO_ 774 2;
BA_ "GenMsgStartValue" BO_ 774 "00FFFF00h";
BA_ "GenMsgSendType" BO_ 776 5;
BA_ "GenMsgCycleTime" BO_ 776 1000;
BA_ "GenMsgDelayTime" BO_ 776 20;
BA_ "GenMsgNrOfRepetitions" BO_ 776 2;
BA_ "GenMsgStartValue" BO_ 776 "0000000000000000h";
BA_ "GenMsgCycleTime" BO_ 778 100;
BA_ "GenMsgDelayTime" BO_ 778 20;
BA_ "GenMsgNrOfRepetitions" BO_ 778 2;
BA_ "GenMsgStartValue" BO_ 778 "FF00000000000000h";
BA_ "GenMsgCycleTime" BO_ 779 1000;
BA_ "GenMsgDelayTime" BO_ 779 20;
BA_ "GenMsgNrOfRepetitions" BO_ 779 2;
BA_ "GenMsgStartValue" BO_ 779 "FFFFFF0FFF00FF00h";
BA_ "GenMsgCycleTime" BO_ 780 100;
BA_ "GenMsgDelayTime" BO_ 780 20;
BA_ "GenMsgNrOfRepetitions" BO_ 780 2;
BA_ "GenMsgStartValue" BO_ 780 "0000000000000000h";
BA_ "GenMsgCycleTime" BO_ 783 1000;
BA_ "GenMsgDelayTime" BO_ 783 20;
BA_ "GenMsgNrOfRepetitions" BO_ 783 2;
BA_ "GenMsgStartValue" BO_ 783 "000001FE000001FEh";
BA_ "GenMsgSendType" BO_ 784 5;
BA_ "GenMsgCycleTime" BO_ 784 1000;
BA_ "GenMsgDelayTime" BO_ 784 20;
BA_ "GenMsgNrOfRepetitions" BO_ 784 2;
BA_ "GenMsgStartValue" BO_ 784 "01FF0000FFFFFF07h";
BA_ "GenMsgSendType" BO_ 788 2;
BA_ "GenMsgCycleTimeActive" BO_ 788 50;
BA_ "GenMsgDelayTime" BO_ 788 20;
BA_ "GenMsgNrOfRepetitions" BO_ 788 2;
BA_ "GenMsgStartValue" BO_ 788 "000000h";
BA_ "GenMsgSendType" BO_ 789 2;
BA_ "GenMsgCycleTimeActive" BO_ 789 50;
BA_ "GenMsgDelayTime" BO_ 789 20;
BA_ "GenMsgNrOfRepetitions" BO_ 789 2;
BA_ "GenMsgStartValue" BO_ 789 "000000h";
BA_ "GenMsgSendType" BO_ 790 2;
BA_ "GenMsgCycleTimeActive" BO_ 790 50;
BA_ "GenMsgDelayTime" BO_ 790 20;
BA_ "GenMsgNrOfRepetitions" BO_ 790 2;
BA_ "GenMsgStartValue" BO_ 790 "000000h";
BA_ "GenMsgSendType" BO_ 792 5;
BA_ "GenMsgCycleTime" BO_ 792 100;
BA_ "GenMsgDelayTime" BO_ 792 20;
BA_ "GenMsgNrOfRepetitions" BO_ 792 2;
BA_ "GenMsgStartValue" BO_ 792 "000000000000FF00h";
BA_ "GenMsgSendType" BO_ 796 5;
BA_ "GenMsgCycleTime" BO_ 796 1000;
BA_ "GenMsgDelayTime" BO_ 796 20;
BA_ "GenMsgNrOfRepetitions" BO_ 796 2;
BA_ "GenMsgStartValue" BO_ 796 "0000000000000000h";
BA_ "GenMsgCycleTime" BO_ 799 1000;
BA_ "GenMsgDelayTime" BO_ 799 20;
BA_ "GenMsgNrOfRepetitions" BO_ 799 2;
BA_ "GenMsgStartValue" BO_ 799 "07FF07FF00000004h";
BA_ "GenMsgStartDelayTime" BO_ 799 130;
BA_ "GenMsgCycleTime" BO_ 800 100;
BA_ "GenMsgDelayTime" BO_ 800 20;
BA_ "GenMsgNrOfRepetitions" BO_ 800 2;
BA_ "GenMsgStartValue" BO_ 800 "0000000000000000h";
BA_ "GenMsgSendType" BO_ 804 5;
BA_ "GenMsgCycleTime" BO_ 804 1000;
BA_ "GenMsgDelayTime" BO_ 804 20;
BA_ "GenMsgNrOfRepetitions" BO_ 804 2;
BA_ "GenMsgStartValue" BO_ 804 "000C000000010000h";
BA_ "GenMsgStartDelayTime" BO_ 804 30;
BA_ "GenMsgSendType" BO_ 806 5;
BA_ "GenMsgCycleTime" BO_ 806 1000;
BA_ "GenMsgDelayTime" BO_ 806 20;
BA_ "GenMsgNrOfRepetitions" BO_ 806 2;
BA_ "GenMsgStartValue" BO_ 806 "0000h";
BA_ "GenMsgSendType" BO_ 808 5;
BA_ "GenMsgCycleTime" BO_ 808 1000;
BA_ "GenMsgDelayTime" BO_ 808 20;
BA_ "GenMsgNrOfRepetitions" BO_ 808 2;
BA_ "GenMsgStartValue" BO_ 808 "0000000000000000h";
BA_ "GenMsgCycleTime" BO_ 810 100;
BA_ "GenMsgDelayTime" BO_ 810 20;
BA_ "GenMsgNrOfRepetitions" BO_ 810 2;
BA_ "GenMsgStartValue" BO_ 810 "0000000000000000h";
BA_ "GenMsgCycleTime" BO_ 811 500;
BA_ "GenMsgDelayTime" BO_ 811 20;
BA_ "GenMsgNrOfRepetitions" BO_ 811 2;
BA_ "GenMsgStartValue" BO_ 811 "000000000000h";
BA_ "GenMsgSendType" BO_ 816 5;
BA_ "GenMsgCycleTime" BO_ 816 1000;
BA_ "GenMsgDelayTime" BO_ 816 20;
BA_ "GenMsgNrOfRepetitions" BO_ 816 2;
BA_ "GenMsgStartValue" BO_ 816 "3000071EC0FF0000h";
BA_ "GenMsgStartDelayTime" BO_ 816 80;
BA_ "GenMsgSendType" BO_ 817 5;
BA_ "GenMsgCycleTime" BO_ 817 1000;
BA_ "GenMsgDelayTime" BO_ 817 20;
BA_ "GenMsgNrOfRepetitions" BO_ 817 2;
BA_ "GenMsgStartValue" BO_ 817 "00000000001E0000h";
BA_ "GenSigCycleTime" SG_ 773 TPM_IndLmpOnRq 1000;
BA_ "FlexKomSigStartValue" SG_ 773 TPM_IndLmpOnRq "000000FFFFFFFFFFh";
BA_ "GenSigTimeout_IC" SG_ 773 TPM_IndLmpOnRq 10500;
BA_ "GenSigTimeout_ORC" SG_ 773 TPM_IndLmpOnRq 3500;
BA_ "FlexKomSID" SG_ 773 TPM_IndLmpOnRq 1611;
BA_ "FlexKomSigStartPos" SG_ 773 TPM_IndLmpOnRq 7;
BA_ "FlexKomSigLaenge" SG_ 773 TPM_IndLmpOnRq 64;
BA_ "FlexKomSigName" SG_ 773 TPM_IndLmpOnRq "TPM_A2_PKT";
BA_ "FlexKomComment" SG_ 773 TPM_IndLmpOnRq "Tire Pressure Packet";
BA_ "FlexKomIsMotorola" SG_ 773 TPM_IndLmpOnRq 1;
BA_ "GenSigSNA" SG_ 773 TPM_IndLmpOnRq "3h";
BA_ "GenSigCycleTime" SG_ 773 TPM_ChimeRq 1000;
BA_ "FlexKomSigStartValue" SG_ 773 TPM_ChimeRq "000000FFFFFFFFFFh";
BA_ "GenSigTimeout_IC" SG_ 773 TPM_ChimeRq 10500;
BA_ "GenSigTimeout_ORC" SG_ 773 TPM_ChimeRq 3500;
BA_ "FlexKomSID" SG_ 773 TPM_ChimeRq 1611;
BA_ "FlexKomSigStartPos" SG_ 773 TPM_ChimeRq 7;
BA_ "FlexKomSigLaenge" SG_ 773 TPM_ChimeRq 64;
BA_ "FlexKomSigName" SG_ 773 TPM_ChimeRq "TPM_A2_PKT";
BA_ "FlexKomComment" SG_ 773 TPM_ChimeRq "Tire Pressure Packet";
BA_ "FlexKomIsMotorola" SG_ 773 TPM_ChimeRq 1;
BA_ "GenSigSNA" SG_ 773 TPM_ChimeRq "0h";
BA_ "GenSigCycleTime" SG_ 773 TPM_SwchIndRq 1000;
BA_ "FlexKomSigStartValue" SG_ 773 TPM_SwchIndRq "000000FFFFFFFFFFh";
BA_ "GenSigTimeout_IC" SG_ 773 TPM_SwchIndRq 10500;
BA_ "GenSigTimeout_ORC" SG_ 773 TPM_SwchIndRq 3500;
BA_ "FlexKomSID" SG_ 773 TPM_SwchIndRq 1611;
BA_ "FlexKomSigStartPos" SG_ 773 TPM_SwchIndRq 7;
BA_ "FlexKomSigLaenge" SG_ 773 TPM_SwchIndRq 64;
BA_ "FlexKomSigName" SG_ 773 TPM_SwchIndRq "TPM_A2_PKT";
BA_ "FlexKomComment" SG_ 773 TPM_SwchIndRq "Tire Pressure Packet";
BA_ "FlexKomIsMotorola" SG_ 773 TPM_SwchIndRq 1;
BA_ "GenSigSNA" SG_ 773 TPM_SwchIndRq "3h";
BA_ "GenSigCycleTime" SG_ 773 TPM_SysStat 1000;
BA_ "FlexKomSigStartValue" SG_ 773 TPM_SysStat "000000FFFFFFFFFFh";
BA_ "GenSigTimeout_IC" SG_ 773 TPM_SysStat 10500;
BA_ "GenSigTimeout_ORC" SG_ 773 TPM_SysStat 3500;
BA_ "FlexKomSID" SG_ 773 TPM_SysStat 1611;
BA_ "FlexKomSigStartPos" SG_ 773 TPM_SysStat 7;
BA_ "FlexKomSigLaenge" SG_ 773 TPM_SysStat 64;
BA_ "FlexKomSigName" SG_ 773 TPM_SysStat "TPM_A2_PKT";
BA_ "FlexKomComment" SG_ 773 TPM_SysStat "Tire Pressure Packet";
BA_ "FlexKomIsMotorola" SG_ 773 TPM_SysStat 1;
BA_ "GenSigSNA" SG_ 773 TPM_SysStat "7h";
BA_ "GenSigCycleTime" SG_ 773 Tire_FL 1000;
BA_ "FlexKomSigStartValue" SG_ 773 Tire_FL "000000FFFFFFFFFFh";
BA_ "GenSigTimeout_IC" SG_ 773 Tire_FL 10500;
BA_ "GenSigTimeout_ORC" SG_ 773 Tire_FL 3500;
BA_ "FlexKomSID" SG_ 773 Tire_FL 1611;
BA_ "FlexKomSigStartPos" SG_ 773 Tire_FL 7;
BA_ "FlexKomSigLaenge" SG_ 773 Tire_FL 64;
BA_ "FlexKomSigName" SG_ 773 Tire_FL "TPM_A2_PKT";
BA_ "FlexKomComment" SG_ 773 Tire_FL "Tire Pressure Packet";
BA_ "FlexKomIsMotorola" SG_ 773 Tire_FL 1;
BA_ "GenSigSNA" SG_ 773 Tire_FL "3h";
BA_ "GenSigCycleTime" SG_ 773 Tire_FR 1000;
BA_ "FlexKomSigStartValue" SG_ 773 Tire_FR "000000FFFFFFFFFFh";
BA_ "GenSigTimeout_IC" SG_ 773 Tire_FR 10500;
BA_ "GenSigTimeout_ORC" SG_ 773 Tire_FR 3500;
BA_ "FlexKomSID" SG_ 773 Tire_FR 1611;
BA_ "FlexKomSigStartPos" SG_ 773 Tire_FR 7;
BA_ "FlexKomSigLaenge" SG_ 773 Tire_FR 64;
BA_ "FlexKomSigName" SG_ 773 Tire_FR "TPM_A2_PKT";
BA_ "FlexKomComment" SG_ 773 Tire_FR "Tire Pressure Packet";
BA_ "FlexKomIsMotorola" SG_ 773 Tire_FR 1;
BA_ "GenSigSNA" SG_ 773 Tire_FR "3h";
BA_ "GenSigCycleTime" SG_ 773 Tire_RR 1000;
BA_ "FlexKomSigStartValue" SG_ 773 Tire_RR "000000FFFFFFFFFFh";
BA_ "GenSigTimeout_IC" SG_ 773 Tire_RR 10500;
BA_ "GenSigTimeout_ORC" SG_ 773 Tire_RR 3500;
BA_ "FlexKomSID" SG_ 773 Tire_RR 1611;
BA_ "FlexKomSigStartPos" SG_ 773 Tire_RR 7;
BA_ "FlexKomSigLaenge" SG_ 773 Tire_RR 64;
BA_ "FlexKomSigName" SG_ 773 Tire_RR "TPM_A2_PKT";
BA_ "FlexKomComment" SG_ 773 Tire_RR "Tire Pressure Packet";
BA_ "FlexKomIsMotorola" SG_ 773 Tire_RR 1;
BA_ "GenSigSNA" SG_ 773 Tire_RR "3h";
BA_ "GenSigCycleTime" SG_ 773 Tire_RL 1000;
BA_ "FlexKomSigStartValue" SG_ 773 Tire_RL "000000FFFFFFFFFFh";
BA_ "GenSigTimeout_IC" SG_ 773 Tire_RL 10500;
BA_ "GenSigTimeout_ORC" SG_ 773 Tire_RL 3500;
BA_ "FlexKomSID" SG_ 773 Tire_RL 1611;
BA_ "FlexKomSigStartPos" SG_ 773 Tire_RL 7;
BA_ "FlexKomSigLaenge" SG_ 773 Tire_RL 64;
BA_ "FlexKomSigName" SG_ 773 Tire_RL "TPM_A2_PKT";
BA_ "FlexKomComment" SG_ 773 Tire_RL "Tire Pressure Packet";
BA_ "FlexKomIsMotorola" SG_ 773 Tire_RL 1;
BA_ "GenSigSNA" SG_ 773 Tire_RL "3h";
BA_ "GenSigCycleTime" SG_ 773 Tire_Spr 1000;
BA_ "FlexKomSigStartValue" SG_ 773 Tire_Spr "000000FFFFFFFFFFh";
BA_ "GenSigTimeout_IC" SG_ 773 Tire_Spr 10500;
BA_ "GenSigTimeout_ORC" SG_ 773 Tire_Spr 3500;
BA_ "FlexKomSID" SG_ 773 Tire_Spr 1611;
BA_ "FlexKomSigStartPos" SG_ 773 Tire_Spr 7;
BA_ "FlexKomSigLaenge" SG_ 773 Tire_Spr 64;
BA_ "FlexKomSigName" SG_ 773 Tire_Spr "TPM_A2_PKT";
BA_ "FlexKomComment" SG_ 773 Tire_Spr "Tire Pressure Packet";
BA_ "FlexKomIsMotorola" SG_ 773 Tire_Spr 1;
BA_ "GenSigSNA" SG_ 773 Tire_Spr "3h";
BA_ "GenSigCycleTime" SG_ 773 RunFlatTire_Low 1000;
BA_ "FlexKomSigStartValue" SG_ 773 RunFlatTire_Low "000000FFFFFFFFFFh";
BA_ "GenSigTimeout_IC" SG_ 773 RunFlatTire_Low 10500;
BA_ "GenSigTimeout_ORC" SG_ 773 RunFlatTire_Low 3500;
BA_ "FlexKomSID" SG_ 773 RunFlatTire_Low 1611;
BA_ "FlexKomSigStartPos" SG_ 773 RunFlatTire_Low 7;
BA_ "FlexKomSigLaenge" SG_ 773 RunFlatTire_Low 64;
BA_ "FlexKomSigName" SG_ 773 RunFlatTire_Low "TPM_A2_PKT";
BA_ "FlexKomComment" SG_ 773 RunFlatTire_Low "Tire Pressure Packet";
BA_ "FlexKomIsMotorola" SG_ 773 RunFlatTire_Low 1;
BA_ "GenSigSNA" SG_ 773 RunFlatTire_Low "0h";
BA_ "GenSigCycleTime" SG_ 773 TirePrssFL 1000;
BA_ "FlexKomSigStartValue" SG_ 773 TirePrssFL "000000FFFFFFFFFFh";
BA_ "GenSigStartValue" SG_ 773 TirePrssFL 255;
BA_ "GenSigTimeout_IC" SG_ 773 TirePrssFL 10500;
BA_ "GenSigTimeout_ORC" SG_ 773 TirePrssFL 3500;
BA_ "FlexKomSID" SG_ 773 TirePrssFL 1611;
BA_ "FlexKomSigStartPos" SG_ 773 TirePrssFL 7;
BA_ "FlexKomSigLaenge" SG_ 773 TirePrssFL 64;
BA_ "FlexKomSigName" SG_ 773 TirePrssFL "TPM_A2_PKT";
BA_ "FlexKomComment" SG_ 773 TirePrssFL "Tire Pressure Packet";
BA_ "FlexKomIsMotorola" SG_ 773 TirePrssFL 1;
BA_ "GenSigSNA" SG_ 773 TirePrssFL "FFh";
BA_ "GenSigCycleTime" SG_ 773 TirePrssFR 1000;
BA_ "FlexKomSigStartValue" SG_ 773 TirePrssFR "000000FFFFFFFFFFh";
BA_ "GenSigStartValue" SG_ 773 TirePrssFR 255;
BA_ "GenSigTimeout_IC" SG_ 773 TirePrssFR 10500;
BA_ "GenSigTimeout_ORC" SG_ 773 TirePrssFR 3500;
BA_ "FlexKomSID" SG_ 773 TirePrssFR 1611;
BA_ "FlexKomSigStartPos" SG_ 773 TirePrssFR 7;
BA_ "FlexKomSigLaenge" SG_ 773 TirePrssFR 64;
BA_ "FlexKomSigName" SG_ 773 TirePrssFR "TPM_A2_PKT";
BA_ "FlexKomComment" SG_ 773 TirePrssFR "Tire Pressure Packet";
BA_ "FlexKomIsMotorola" SG_ 773 TirePrssFR 1;
BA_ "GenSigSNA" SG_ 773 TirePrssFR "FFh";
BA_ "GenSigCycleTime" SG_ 773 TirePrssRL 1000;
BA_ "FlexKomSigStartValue" SG_ 773 TirePrssRL "000000FFFFFFFFFFh";
BA_ "GenSigStartValue" SG_ 773 TirePrssRL 255;
BA_ "GenSigTimeout_IC" SG_ 773 TirePrssRL 10500;
BA_ "GenSigTimeout_ORC" SG_ 773 TirePrssRL 3500;
BA_ "FlexKomSID" SG_ 773 TirePrssRL 1611;
BA_ "FlexKomSigStartPos" SG_ 773 TirePrssRL 7;
BA_ "FlexKomSigLaenge" SG_ 773 TirePrssRL 64;
BA_ "FlexKomSigName" SG_ 773 TirePrssRL "TPM_A2_PKT";
BA_ "FlexKomComment" SG_ 773 TirePrssRL "Tire Pressure Packet";
BA_ "FlexKomIsMotorola" SG_ 773 TirePrssRL 1;
BA_ "GenSigSNA" SG_ 773 TirePrssRL "FFh";
BA_ "GenSigCycleTime" SG_ 773 TirePrssRR 1000;
BA_ "FlexKomSigStartValue" SG_ 773 TirePrssRR "000000FFFFFFFFFFh";
BA_ "GenSigStartValue" SG_ 773 TirePrssRR 255;
BA_ "GenSigTimeout_IC" SG_ 773 TirePrssRR 10500;
BA_ "GenSigTimeout_ORC" SG_ 773 TirePrssRR 3500;
BA_ "FlexKomSID" SG_ 773 TirePrssRR 1611;
BA_ "FlexKomSigStartPos" SG_ 773 TirePrssRR 7;
BA_ "FlexKomSigLaenge" SG_ 773 TirePrssRR 64;
BA_ "FlexKomSigName" SG_ 773 TirePrssRR "TPM_A2_PKT";
BA_ "FlexKomComment" SG_ 773 TirePrssRR "Tire Pressure Packet";
BA_ "FlexKomIsMotorola" SG_ 773 TirePrssRR 1;
BA_ "GenSigSNA" SG_ 773 TirePrssRR "FFh";
BA_ "GenSigCycleTime" SG_ 773 TirePrssSpr 1000;
BA_ "FlexKomSigStartValue" SG_ 773 TirePrssSpr "000000FFFFFFFFFFh";
BA_ "GenSigStartValue" SG_ 773 TirePrssSpr 255;
BA_ "GenSigTimeout_IC" SG_ 773 TirePrssSpr 10500;
BA_ "GenSigTimeout_ORC" SG_ 773 TirePrssSpr 3500;
BA_ "FlexKomSID" SG_ 773 TirePrssSpr 1611;
BA_ "FlexKomSigStartPos" SG_ 773 TirePrssSpr 7;
BA_ "FlexKomSigLaenge" SG_ 773 TirePrssSpr 64;
BA_ "FlexKomSigName" SG_ 773 TirePrssSpr "TPM_A2_PKT";
BA_ "FlexKomComment" SG_ 773 TirePrssSpr "Tire Pressure Packet";
BA_ "FlexKomIsMotorola" SG_ 773 TirePrssSpr 1;
BA_ "GenSigSNA" SG_ 773 TirePrssSpr "FFh";
BA_ "GenSigCycleTime" SG_ 774 Tire_RR2 1000;
BA_ "FlexKomSigStartValue" SG_ 774 Tire_RR2 "00FFFF00h";
BA_ "GenSigTimeout_IC" SG_ 774 Tire_RR2 10500;
BA_ "GenSigTimeout_ORC" SG_ 774 Tire_RR2 3500;
BA_ "FlexKomSID" SG_ 774 Tire_RR2 1612;
BA_ "FlexKomSigStartPos" SG_ 774 Tire_RR2 7;
BA_ "FlexKomSigLaenge" SG_ 774 Tire_RR2 32;
BA_ "FlexKomSigName" SG_ 774 Tire_RR2 "TPM_A3_PKT";
BA_ "FlexKomComment" SG_ 774 Tire_RR2 "Tire Pressure Packet";
BA_ "FlexKomIsMotorola" SG_ 774 Tire_RR2 1;
BA_ "GenSigSNA" SG_ 774 Tire_RR2 "3h";
BA_ "GenSigCycleTime" SG_ 774 Tire_RL2 1000;
BA_ "FlexKomSigStartValue" SG_ 774 Tire_RL2 "00FFFF00h";
BA_ "GenSigTimeout_IC" SG_ 774 Tire_RL2 10500;
BA_ "GenSigTimeout_ORC" SG_ 774 Tire_RL2 3500;
BA_ "FlexKomSID" SG_ 774 Tire_RL2 1612;
BA_ "FlexKomSigStartPos" SG_ 774 Tire_RL2 7;
BA_ "FlexKomSigLaenge" SG_ 774 Tire_RL2 32;
BA_ "FlexKomSigName" SG_ 774 Tire_RL2 "TPM_A3_PKT";
BA_ "FlexKomComment" SG_ 774 Tire_RL2 "Tire Pressure Packet";
BA_ "FlexKomIsMotorola" SG_ 774 Tire_RL2 1;
BA_ "GenSigSNA" SG_ 774 Tire_RL2 "3h";
BA_ "GenSigCycleTime" SG_ 774 Tire_RR_RR2_Diff 1000;
BA_ "FlexKomSigStartValue" SG_ 774 Tire_RR_RR2_Diff "00FFFF00h";
BA_ "GenSigTimeout_IC" SG_ 774 Tire_RR_RR2_Diff 10500;
BA_ "GenSigTimeout_ORC" SG_ 774 Tire_RR_RR2_Diff 3500;
BA_ "FlexKomSID" SG_ 774 Tire_RR_RR2_Diff 1612;
BA_ "FlexKomSigStartPos" SG_ 774 Tire_RR_RR2_Diff 7;
BA_ "FlexKomSigLaenge" SG_ 774 Tire_RR_RR2_Diff 32;
BA_ "FlexKomSigName" SG_ 774 Tire_RR_RR2_Diff "TPM_A3_PKT";
BA_ "FlexKomComment" SG_ 774 Tire_RR_RR2_Diff "Tire Pressure Packet";
BA_ "FlexKomIsMotorola" SG_ 774 Tire_RR_RR2_Diff 1;
BA_ "GenSigSNA" SG_ 774 Tire_RR_RR2_Diff "0h";
BA_ "GenSigCycleTime" SG_ 774 Tire_RL_RL2_Diff 1000;
BA_ "FlexKomSigStartValue" SG_ 774 Tire_RL_RL2_Diff "00FFFF00h";
BA_ "GenSigTimeout_IC" SG_ 774 Tire_RL_RL2_Diff 10500;
BA_ "GenSigTimeout_ORC" SG_ 774 Tire_RL_RL2_Diff 3500;
BA_ "FlexKomSID" SG_ 774 Tire_RL_RL2_Diff 1612;
BA_ "FlexKomSigStartPos" SG_ 774 Tire_RL_RL2_Diff 7;
BA_ "FlexKomSigLaenge" SG_ 774 Tire_RL_RL2_Diff 32;
BA_ "FlexKomSigName" SG_ 774 Tire_RL_RL2_Diff "TPM_A3_PKT";
BA_ "FlexKomComment" SG_ 774 Tire_RL_RL2_Diff "Tire Pressure Packet";
BA_ "FlexKomIsMotorola" SG_ 774 Tire_RL_RL2_Diff 1;
BA_ "GenSigSNA" SG_ 774 Tire_RL_RL2_Diff "0h";
BA_ "GenSigCycleTime" SG_ 774 Tire_FL_FR_Diff 1000;
BA_ "FlexKomSigStartValue" SG_ 774 Tire_FL_FR_Diff "00FFFF00h";
BA_ "GenSigTimeout_IC" SG_ 774 Tire_FL_FR_Diff 10500;
BA_ "GenSigTimeout_ORC" SG_ 774 Tire_FL_FR_Diff 3500;
BA_ "FlexKomSID" SG_ 774 Tire_FL_FR_Diff 1612;
BA_ "FlexKomSigStartPos" SG_ 774 Tire_FL_FR_Diff 7;
BA_ "FlexKomSigLaenge" SG_ 774 Tire_FL_FR_Diff 32;
BA_ "FlexKomSigName" SG_ 774 Tire_FL_FR_Diff "TPM_A3_PKT";
BA_ "FlexKomComment" SG_ 774 Tire_FL_FR_Diff "Tire Pressure Packet";
BA_ "FlexKomIsMotorola" SG_ 774 Tire_FL_FR_Diff 1;
BA_ "GenSigSNA" SG_ 774 Tire_FL_FR_Diff "0h";
BA_ "GenSigCycleTime" SG_ 774 Tire_RL_RR_Diff 1000;
BA_ "FlexKomSigStartValue" SG_ 774 Tire_RL_RR_Diff "00FFFF00h";
BA_ "GenSigTimeout_IC" SG_ 774 Tire_RL_RR_Diff 10500;
BA_ "GenSigTimeout_ORC" SG_ 774 Tire_RL_RR_Diff 3500;
BA_ "FlexKomSID" SG_ 774 Tire_RL_RR_Diff 1612;
BA_ "FlexKomSigStartPos" SG_ 774 Tire_RL_RR_Diff 7;
BA_ "FlexKomSigLaenge" SG_ 774 Tire_RL_RR_Diff 32;
BA_ "FlexKomSigName" SG_ 774 Tire_RL_RR_Diff "TPM_A3_PKT";
BA_ "FlexKomComment" SG_ 774 Tire_RL_RR_Diff "Tire Pressure Packet";
BA_ "FlexKomIsMotorola" SG_ 774 Tire_RL_RR_Diff 1;
BA_ "GenSigSNA" SG_ 774 Tire_RL_RR_Diff "0h";
BA_ "GenSigCycleTime" SG_ 774 TirePrssRL2 1000;
BA_ "FlexKomSigStartValue" SG_ 774 TirePrssRL2 "00FFFF00h";
BA_ "GenSigStartValue" SG_ 774 TirePrssRL2 255;
BA_ "GenSigTimeout_IC" SG_ 774 TirePrssRL2 10500;
BA_ "GenSigTimeout_ORC" SG_ 774 TirePrssRL2 3500;
BA_ "GenSigTimeout_ETM" SG_ 774 TirePrssRL2 10500;
BA_ "FlexKomSID" SG_ 774 TirePrssRL2 1612;
BA_ "FlexKomSigStartPos" SG_ 774 TirePrssRL2 7;
BA_ "FlexKomSigLaenge" SG_ 774 TirePrssRL2 32;
BA_ "FlexKomSigName" SG_ 774 TirePrssRL2 "TPM_A3_PKT";
BA_ "FlexKomComment" SG_ 774 TirePrssRL2 "Tire Pressure Packet";
BA_ "FlexKomIsMotorola" SG_ 774 TirePrssRL2 1;
BA_ "GenSigSNA" SG_ 774 TirePrssRL2 "FFh";
BA_ "GenSigCycleTime" SG_ 774 TirePrssRR2 1000;
BA_ "FlexKomSigStartValue" SG_ 774 TirePrssRR2 "00FFFF00h";
BA_ "GenSigStartValue" SG_ 774 TirePrssRR2 255;
BA_ "GenSigTimeout_IC" SG_ 774 TirePrssRR2 10500;
BA_ "GenSigTimeout_ORC" SG_ 774 TirePrssRR2 3500;
BA_ "GenSigTimeout_ETM" SG_ 774 TirePrssRR2 10500;
BA_ "FlexKomSID" SG_ 774 TirePrssRR2 1612;
BA_ "FlexKomSigStartPos" SG_ 774 TirePrssRR2 7;
BA_ "FlexKomSigLaenge" SG_ 774 TirePrssRR2 32;
BA_ "FlexKomSigName" SG_ 774 TirePrssRR2 "TPM_A3_PKT";
BA_ "FlexKomComment" SG_ 774 TirePrssRR2 "Tire Pressure Packet";
BA_ "FlexKomIsMotorola" SG_ 774 TirePrssRR2 1;
BA_ "GenSigSNA" SG_ 774 TirePrssRR2 "FFh";
BA_ "GenSigSendType" SG_ 776 TCASE_FAIL 5;
BA_ "GenSigCycleTime" SG_ 776 TCASE_FAIL 1000;
BA_ "FlexKomSigStartValue" SG_ 776 TCASE_FAIL "0000000000000000h";
BA_ "GenSigTimeout_ETM" SG_ 776 TCASE_FAIL 10500;
BA_ "FlexKomSID" SG_ 776 TCASE_FAIL 808;
BA_ "FlexKomSigStartPos" SG_ 776 TCASE_FAIL 7;
BA_ "FlexKomSigLaenge" SG_ 776 TCASE_FAIL 64;
BA_ "FlexKomSigName" SG_ 776 TCASE_FAIL "DTCM_B1_PKT";
BA_ "FlexKomComment" SG_ 776 TCASE_FAIL "DTCM_B1_PKT";
BA_ "FlexKomIsMotorola" SG_ 776 TCASE_FAIL 1;
BA_ "GenSigSNA" SG_ 776 TCASE_FAIL "0h";
BA_ "GenSigSendType" SG_ 776 TCASE_INHBT 5;
BA_ "GenSigCycleTime" SG_ 776 TCASE_INHBT 1000;
BA_ "FlexKomSigStartValue" SG_ 776 TCASE_INHBT "0000000000000000h";
BA_ "GenSigTimeout_IC" SG_ 776 TCASE_INHBT 10500;
BA_ "GenSigTimeout_ETM" SG_ 776 TCASE_INHBT 10500;
BA_ "FlexKomSID" SG_ 776 TCASE_INHBT 808;
BA_ "FlexKomSigStartPos" SG_ 776 TCASE_INHBT 7;
BA_ "FlexKomSigLaenge" SG_ 776 TCASE_INHBT 64;
BA_ "FlexKomSigName" SG_ 776 TCASE_INHBT "DTCM_B1_PKT";
BA_ "FlexKomComment" SG_ 776 TCASE_INHBT "DTCM_B1_PKT";
BA_ "FlexKomIsMotorola" SG_ 776 TCASE_INHBT 1;
BA_ "GenSigSNA" SG_ 776 TCASE_INHBT "0h";
BA_ "GenSigSendType" SG_ 776 TCASE_SRV_RQ 5;
BA_ "GenSigCycleTime" SG_ 776 TCASE_SRV_RQ 1000;
BA_ "FlexKomSigStartValue" SG_ 776 TCASE_SRV_RQ "0000000000000000h";
BA_ "GenSigTimeout_IC" SG_ 776 TCASE_SRV_RQ 10500;
BA_ "GenSigTimeout_ETM" SG_ 776 TCASE_SRV_RQ 10500;
BA_ "FlexKomSID" SG_ 776 TCASE_SRV_RQ 808;
BA_ "FlexKomSigStartPos" SG_ 776 TCASE_SRV_RQ 7;
BA_ "FlexKomSigLaenge" SG_ 776 TCASE_SRV_RQ 64;
BA_ "FlexKomSigName" SG_ 776 TCASE_SRV_RQ "DTCM_B1_PKT";
BA_ "FlexKomComment" SG_ 776 TCASE_SRV_RQ "DTCM_B1_PKT";
BA_ "FlexKomIsMotorola" SG_ 776 TCASE_SRV_RQ 1;
BA_ "GenSigSNA" SG_ 776 TCASE_SRV_RQ "3h";
BA_ "GenSigSendType" SG_ 776 Tcase4Lock 5;
BA_ "GenSigCycleTime" SG_ 776 Tcase4Lock 1000;
BA_ "FlexKomSigStartValue" SG_ 776 Tcase4Lock "0000000000000000h";
BA_ "GenSigTimeout_CBC" SG_ 776 Tcase4Lock 10500;
BA_ "GenSigTimeout_IC" SG_ 776 Tcase4Lock 10500;
BA_ "GenSigTimeout_ETM" SG_ 776 Tcase4Lock 10500;
BA_ "FlexKomSID" SG_ 776 Tcase4Lock 808;
BA_ "FlexKomSigStartPos" SG_ 776 Tcase4Lock 7;
BA_ "FlexKomSigLaenge" SG_ 776 Tcase4Lock 64;
BA_ "FlexKomSigName" SG_ 776 Tcase4Lock "DTCM_B1_PKT";
BA_ "FlexKomComment" SG_ 776 Tcase4Lock "DTCM_B1_PKT";
BA_ "FlexKomIsMotorola" SG_ 776 Tcase4Lock 1;
BA_ "GenSigSNA" SG_ 776 Tcase4Lock "3h";
BA_ "GenSigSendType" SG_ 776 Tcase4Low 5;
BA_ "GenSigCycleTime" SG_ 776 Tcase4Low 1000;
BA_ "FlexKomSigStartValue" SG_ 776 Tcase4Low "0000000000000000h";
BA_ "GenSigTimeout_CBC" SG_ 776 Tcase4Low 10500;
BA_ "GenSigTimeout_IC" SG_ 776 Tcase4Low 10500;
BA_ "GenSigTimeout_ETM" SG_ 776 Tcase4Low 10500;
BA_ "FlexKomSID" SG_ 776 Tcase4Low 808;
BA_ "FlexKomSigStartPos" SG_ 776 Tcase4Low 7;
BA_ "FlexKomSigLaenge" SG_ 776 Tcase4Low 64;
BA_ "FlexKomSigName" SG_ 776 Tcase4Low "DTCM_B1_PKT";
BA_ "FlexKomComment" SG_ 776 Tcase4Low "DTCM_B1_PKT";
BA_ "FlexKomIsMotorola" SG_ 776 Tcase4Low 1;
BA_ "GenSigSNA" SG_ 776 Tcase4Low "3h";
BA_ "GenSigSendType" SG_ 776 TcaseNtrlStat 5;
BA_ "GenSigCycleTime" SG_ 776 TcaseNtrlStat 1000;
BA_ "FlexKomSigStartValue" SG_ 776 TcaseNtrlStat "0000000000000000h";
BA_ "GenSigTimeout_CBC" SG_ 776 TcaseNtrlStat 10500;
BA_ "GenSigTimeout_IC" SG_ 776 TcaseNtrlStat 10500;
BA_ "GenSigTimeout_ETM" SG_ 776 TcaseNtrlStat 10500;
BA_ "FlexKomSID" SG_ 776 TcaseNtrlStat 808;
BA_ "FlexKomSigStartPos" SG_ 776 TcaseNtrlStat 7;
BA_ "FlexKomSigLaenge" SG_ 776 TcaseNtrlStat 64;
BA_ "FlexKomSigName" SG_ 776 TcaseNtrlStat "DTCM_B1_PKT";
BA_ "FlexKomComment" SG_ 776 TcaseNtrlStat "DTCM_B1_PKT";
BA_ "FlexKomIsMotorola" SG_ 776 TcaseNtrlStat 1;
BA_ "GenSigSNA" SG_ 776 TcaseNtrlStat "3h";
BA_ "GenSigSendType" SG_ 776 TcaseAWD 5;
BA_ "GenSigCycleTime" SG_ 776 TcaseAWD 1000;
BA_ "FlexKomSigStartValue" SG_ 776 TcaseAWD "0000000000000000h";
BA_ "GenSigTimeout_CBC" SG_ 776 TcaseAWD 10500;
BA_ "GenSigTimeout_IC" SG_ 776 TcaseAWD 10500;
BA_ "GenSigTimeout_ETM" SG_ 776 TcaseAWD 10500;
BA_ "FlexKomSID" SG_ 776 TcaseAWD 808;
BA_ "FlexKomSigStartPos" SG_ 776 TcaseAWD 7;
BA_ "FlexKomSigLaenge" SG_ 776 TcaseAWD 64;
BA_ "FlexKomSigName" SG_ 776 TcaseAWD "DTCM_B1_PKT";
BA_ "FlexKomComment" SG_ 776 TcaseAWD "DTCM_B1_PKT";
BA_ "FlexKomIsMotorola" SG_ 776 TcaseAWD 1;
BA_ "GenSigSNA" SG_ 776 TcaseAWD "3h";
BA_ "GenSigSendType" SG_ 776 CNT_DIFF_MOD 5;
BA_ "GenSigCycleTime" SG_ 776 CNT_DIFF_MOD 1000;
BA_ "FlexKomSigStartValue" SG_ 776 CNT_DIFF_MOD "0000000000000000h";
BA_ "FlexKomSID" SG_ 776 CNT_DIFF_MOD 808;
BA_ "FlexKomSigStartPos" SG_ 776 CNT_DIFF_MOD 7;
BA_ "FlexKomSigLaenge" SG_ 776 CNT_DIFF_MOD 64;
BA_ "FlexKomSigName" SG_ 776 CNT_DIFF_MOD "DTCM_B1_PKT";
BA_ "FlexKomComment" SG_ 776 CNT_DIFF_MOD "DTCM_B1_PKT";
BA_ "FlexKomIsMotorola" SG_ 776 CNT_DIFF_MOD 1;
BA_ "GenSigSNA" SG_ 776 CNT_DIFF_MOD "3h";
BA_ "GenSigSendType" SG_ 776 Tcase2WD_Stat 5;
BA_ "GenSigCycleTime" SG_ 776 Tcase2WD_Stat 1000;
BA_ "FlexKomSigStartValue" SG_ 776 Tcase2WD_Stat "0000000000000000h";
BA_ "GenSigTimeout_CBC" SG_ 776 Tcase2WD_Stat 10500;
BA_ "GenSigTimeout_IC" SG_ 776 Tcase2WD_Stat 10500;
BA_ "FlexKomSID" SG_ 776 Tcase2WD_Stat 808;
BA_ "FlexKomSigStartPos" SG_ 776 Tcase2WD_Stat 7;
BA_ "FlexKomSigLaenge" SG_ 776 Tcase2WD_Stat 64;
BA_ "FlexKomSigName" SG_ 776 Tcase2WD_Stat "DTCM_B1_PKT";
BA_ "FlexKomComment" SG_ 776 Tcase2WD_Stat "DTCM_B1_PKT";
BA_ "FlexKomIsMotorola" SG_ 776 Tcase2WD_Stat 1;
BA_ "GenSigSNA" SG_ 776 Tcase2WD_Stat "3h";
BA_ "GenSigSendType" SG_ 776 TerSt_LED3 5;
BA_ "GenSigCycleTime" SG_ 776 TerSt_LED3 1000;
BA_ "FlexKomSigStartValue" SG_ 776 TerSt_LED3 "0000000000000000h";
BA_ "GenSigTimeout_CBC" SG_ 776 TerSt_LED3 10500;
BA_ "GenSigTimeout_IC" SG_ 776 TerSt_LED3 10500;
BA_ "GenSigTimeout_ETM" SG_ 776 TerSt_LED3 10500;
BA_ "FlexKomSID" SG_ 776 TerSt_LED3 808;
BA_ "FlexKomSigStartPos" SG_ 776 TerSt_LED3 7;
BA_ "FlexKomSigLaenge" SG_ 776 TerSt_LED3 64;
BA_ "FlexKomSigName" SG_ 776 TerSt_LED3 "DTCM_B1_PKT";
BA_ "FlexKomComment" SG_ 776 TerSt_LED3 "DTCM_B1_PKT";
BA_ "FlexKomIsMotorola" SG_ 776 TerSt_LED3 1;
BA_ "GenSigSNA" SG_ 776 TerSt_LED3 "3h";
BA_ "GenSigSendType" SG_ 776 TerSt_LED1 5;
BA_ "GenSigCycleTime" SG_ 776 TerSt_LED1 1000;
BA_ "FlexKomSigStartValue" SG_ 776 TerSt_LED1 "0000000000000000h";
BA_ "GenSigTimeout_CBC" SG_ 776 TerSt_LED1 10500;
BA_ "GenSigTimeout_IC" SG_ 776 TerSt_LED1 10500;
BA_ "GenSigTimeout_ETM" SG_ 776 TerSt_LED1 10500;
BA_ "FlexKomSID" SG_ 776 TerSt_LED1 808;
BA_ "FlexKomSigStartPos" SG_ 776 TerSt_LED1 7;
BA_ "FlexKomSigLaenge" SG_ 776 TerSt_LED1 64;
BA_ "FlexKomSigName" SG_ 776 TerSt_LED1 "DTCM_B1_PKT";
BA_ "FlexKomComment" SG_ 776 TerSt_LED1 "DTCM_B1_PKT";
BA_ "FlexKomIsMotorola" SG_ 776 TerSt_LED1 1;
BA_ "GenSigSNA" SG_ 776 TerSt_LED1 "3h";
BA_ "GenSigSendType" SG_ 776 TerSt_LED2 5;
BA_ "GenSigCycleTime" SG_ 776 TerSt_LED2 1000;
BA_ "FlexKomSigStartValue" SG_ 776 TerSt_LED2 "0000000000000000h";
BA_ "GenSigTimeout_CBC" SG_ 776 TerSt_LED2 10500;
BA_ "GenSigTimeout_IC" SG_ 776 TerSt_LED2 10500;
BA_ "GenSigTimeout_ETM" SG_ 776 TerSt_LED2 10500;
BA_ "FlexKomSID" SG_ 776 TerSt_LED2 808;
BA_ "FlexKomSigStartPos" SG_ 776 TerSt_LED2 7;
BA_ "FlexKomSigLaenge" SG_ 776 TerSt_LED2 64;
BA_ "FlexKomSigName" SG_ 776 TerSt_LED2 "DTCM_B1_PKT";
BA_ "FlexKomComment" SG_ 776 TerSt_LED2 "DTCM_B1_PKT";
BA_ "FlexKomIsMotorola" SG_ 776 TerSt_LED2 1;
BA_ "GenSigSNA" SG_ 776 TerSt_LED2 "3h";
BA_ "GenSigSendType" SG_ 776 TerSt_LED5 5;
BA_ "GenSigCycleTime" SG_ 776 TerSt_LED5 1000;
BA_ "FlexKomSigStartValue" SG_ 776 TerSt_LED5 "0000000000000000h";
BA_ "GenSigTimeout_CBC" SG_ 776 TerSt_LED5 10500;
BA_ "GenSigTimeout_IC" SG_ 776 TerSt_LED5 10500;
BA_ "GenSigTimeout_ETM" SG_ 776 TerSt_LED5 10500;
BA_ "FlexKomSID" SG_ 776 TerSt_LED5 808;
BA_ "FlexKomSigStartPos" SG_ 776 TerSt_LED5 7;
BA_ "FlexKomSigLaenge" SG_ 776 TerSt_LED5 64;
BA_ "FlexKomSigName" SG_ 776 TerSt_LED5 "DTCM_B1_PKT";
BA_ "FlexKomComment" SG_ 776 TerSt_LED5 "DTCM_B1_PKT";
BA_ "FlexKomIsMotorola" SG_ 776 TerSt_LED5 1;
BA_ "GenSigSNA" SG_ 776 TerSt_LED5 "3h";
BA_ "GenSigSendType" SG_ 776 TerSt_LED4 5;
BA_ "GenSigCycleTime" SG_ 776 TerSt_LED4 1000;
BA_ "FlexKomSigStartValue" SG_ 776 TerSt_LED4 "0000000000000000h";
BA_ "GenSigTimeout_CBC" SG_ 776 TerSt_LED4 10500;
BA_ "GenSigTimeout_IC" SG_ 776 TerSt_LED4 10500;
BA_ "GenSigTimeout_ETM" SG_ 776 TerSt_LED4 10500;
BA_ "FlexKomSID" SG_ 776 TerSt_LED4 808;
BA_ "FlexKomSigStartPos" SG_ 776 TerSt_LED4 7;
BA_ "FlexKomSigLaenge" SG_ 776 TerSt_LED4 64;
BA_ "FlexKomSigName" SG_ 776 TerSt_LED4 "DTCM_B1_PKT";
BA_ "FlexKomComment" SG_ 776 TerSt_LED4 "DTCM_B1_PKT";
BA_ "FlexKomIsMotorola" SG_ 776 TerSt_LED4 1;
BA_ "GenSigSNA" SG_ 776 TerSt_LED4 "3h";
BA_ "GenSigSendType" SG_ 776 TerMdStat 5;
BA_ "GenSigCycleTime" SG_ 776 TerMdStat 1000;
BA_ "FlexKomSigStartValue" SG_ 776 TerMdStat "0000000000000000h";
BA_ "GenSigTimeout_CBC" SG_ 776 TerMdStat 10500;
BA_ "GenSigTimeout_IC" SG_ 776 TerMdStat 10500;
BA_ "GenSigTimeout_ADCM" SG_ 776 TerMdStat 25500;
BA_ "GenSigTimeout_ETM" SG_ 776 TerMdStat 10500;
BA_ "FlexKomSID" SG_ 776 TerMdStat 808;
BA_ "FlexKomSigStartPos" SG_ 776 TerMdStat 7;
BA_ "FlexKomSigLaenge" SG_ 776 TerMdStat 64;
BA_ "FlexKomSigName" SG_ 776 TerMdStat "DTCM_B1_PKT";
BA_ "FlexKomComment" SG_ 776 TerMdStat "DTCM_B1_PKT";
BA_ "FlexKomIsMotorola" SG_ 776 TerMdStat 1;
BA_ "GenSigSNA" SG_ 776 TerMdStat "Fh";
BA_ "GenSigSendType" SG_ 776 DTCM_HMI_Rq 5;
BA_ "GenSigCycleTime" SG_ 776 DTCM_HMI_Rq 1000;
BA_ "FlexKomSigStartValue" SG_ 776 DTCM_HMI_Rq "0000000000000000h";
BA_ "GenSigTimeout_IC" SG_ 776 DTCM_HMI_Rq 10500;
BA_ "FlexKomSID" SG_ 776 DTCM_HMI_Rq 808;
BA_ "FlexKomSigStartPos" SG_ 776 DTCM_HMI_Rq 7;
BA_ "FlexKomSigLaenge" SG_ 776 DTCM_HMI_Rq 64;
BA_ "FlexKomSigName" SG_ 776 DTCM_HMI_Rq "DTCM_B1_PKT";
BA_ "FlexKomComment" SG_ 776 DTCM_HMI_Rq "DTCM_B1_PKT";
BA_ "FlexKomIsMotorola" SG_ 776 DTCM_HMI_Rq 1;
BA_ "GenSigSNA" SG_ 776 DTCM_HMI_Rq "1Fh";
BA_ "GenSigCycleTime" SG_ 778 WTS_CntDnTmr 100;
BA_ "FlexKomSigStartValue" SG_ 778 WTS_CntDnTmr "FFh";
BA_ "GenSigStartValue" SG_ 778 WTS_CntDnTmr 255;
BA_ "GenSigTimeout_IC" SG_ 778 WTS_CntDnTmr 1050;
BA_ "FlexKomSID" SG_ 778 WTS_CntDnTmr 1734;
BA_ "FlexKomSigStartPos" SG_ 778 WTS_CntDnTmr 7;
BA_ "FlexKomSigLaenge" SG_ 778 WTS_CntDnTmr 8;
BA_ "FlexKomSigName" SG_ 778 WTS_CntDnTmr "WTS_CntDnTmr";
BA_ "FlexKomComment" SG_ 778 WTS_CntDnTmr "Wait to start count down timer (sec)";
BA_ "FlexKomIsMotorola" SG_ 778 WTS_CntDnTmr 1;
BA_ "GenSigSNA" SG_ 778 WTS_CntDnTmr "FFh";
BA_ "GenSigCycleTime" SG_ 778 EB_Stat3 100;
BA_ "FlexKomSigStartValue" SG_ 778 EB_Stat3 "00h";
BA_ "GenSigTimeout_CBC" SG_ 778 EB_Stat3 1050;
BA_ "GenSigTimeout_IC" SG_ 778 EB_Stat3 1050;
BA_ "FlexKomSID" SG_ 778 EB_Stat3 1825;
BA_ "FlexKomSigStartPos" SG_ 778 EB_Stat3 23;
BA_ "FlexKomSigLaenge" SG_ 778 EB_Stat3 3;
BA_ "FlexKomSigName" SG_ 778 EB_Stat3 "EB_Stat3";
BA_ "FlexKomComment" SG_ 778 EB_Stat3 "Exhaust brake status - 3 bit";
BA_ "FlexKomIsMotorola" SG_ 778 EB_Stat3 1;
BA_ "GenSigSNA" SG_ 778 EB_Stat3 "7h";
BA_ "GenSigCycleTime" SG_ 778 SRV_AIR_FLTR 100;
BA_ "FlexKomSigStartValue" SG_ 778 SRV_AIR_FLTR "00h";
BA_ "GenSigTimeout_IC" SG_ 778 SRV_AIR_FLTR 1050;
BA_ "FlexKomSID" SG_ 778 SRV_AIR_FLTR 1435;
BA_ "FlexKomSigStartPos" SG_ 778 SRV_AIR_FLTR 31;
BA_ "FlexKomSigLaenge" SG_ 778 SRV_AIR_FLTR 8;
BA_ "FlexKomSigName" SG_ 778 SRV_AIR_FLTR "DslInfoPkt";
BA_ "FlexKomComment" SG_ 778 SRV_AIR_FLTR "Diesel information packet";
BA_ "FlexKomIsMotorola" SG_ 778 SRV_AIR_FLTR 1;
BA_ "GenSigSNA" SG_ 778 SRV_AIR_FLTR "0h";
BA_ "GenSigCycleTime" SG_ 778 SRV_CCV_FLTR 100;
BA_ "FlexKomSigStartValue" SG_ 778 SRV_CCV_FLTR "00h";
BA_ "GenSigTimeout_IC" SG_ 778 SRV_CCV_FLTR 1050;
BA_ "FlexKomSID" SG_ 778 SRV_CCV_FLTR 1435;
BA_ "FlexKomSigStartPos" SG_ 778 SRV_CCV_FLTR 31;
BA_ "FlexKomSigLaenge" SG_ 778 SRV_CCV_FLTR 8;
BA_ "FlexKomSigName" SG_ 778 SRV_CCV_FLTR "DslInfoPkt";
BA_ "FlexKomComment" SG_ 778 SRV_CCV_FLTR "Diesel information packet";
BA_ "FlexKomIsMotorola" SG_ 778 SRV_CCV_FLTR 1;
BA_ "GenSigSNA" SG_ 778 SRV_CCV_FLTR "0h";
BA_ "GenSigCycleTime" SG_ 778 DrtdTrqMd 100;
BA_ "FlexKomSigStartValue" SG_ 778 DrtdTrqMd "00h";
BA_ "GenSigTimeout_IC" SG_ 778 DrtdTrqMd 1050;
BA_ "FlexKomSID" SG_ 778 DrtdTrqMd 1435;
BA_ "FlexKomSigStartPos" SG_ 778 DrtdTrqMd 31;
BA_ "FlexKomSigLaenge" SG_ 778 DrtdTrqMd 8;
BA_ "FlexKomSigName" SG_ 778 DrtdTrqMd "DslInfoPkt";
BA_ "FlexKomComment" SG_ 778 DrtdTrqMd "Diesel information packet";
BA_ "FlexKomIsMotorola" SG_ 778 DrtdTrqMd 1;
BA_ "GenSigSNA" SG_ 778 DrtdTrqMd "0h";
BA_ "GenSigCycleTime" SG_ 778 IdleShutDwnAppl 100;
BA_ "FlexKomSigStartValue" SG_ 778 IdleShutDwnAppl "00h";
BA_ "GenSigTimeout_IC" SG_ 778 IdleShutDwnAppl 1050;
BA_ "FlexKomSID" SG_ 778 IdleShutDwnAppl 1435;
BA_ "FlexKomSigStartPos" SG_ 778 IdleShutDwnAppl 31;
BA_ "FlexKomSigLaenge" SG_ 778 IdleShutDwnAppl 8;
BA_ "FlexKomSigName" SG_ 778 IdleShutDwnAppl "DslInfoPkt";
BA_ "FlexKomComment" SG_ 778 IdleShutDwnAppl "Diesel information packet";
BA_ "FlexKomIsMotorola" SG_ 778 IdleShutDwnAppl 1;
BA_ "GenSigSNA" SG_ 778 IdleShutDwnAppl "0h";
BA_ "GenSigCycleTime" SG_ 778 EngBrkStat 100;
BA_ "FlexKomSigStartValue" SG_ 778 EngBrkStat "00h";
BA_ "FlexKomSID" SG_ 778 EngBrkStat 1434;
BA_ "FlexKomSigStartPos" SG_ 778 EngBrkStat 34;
BA_ "FlexKomSigLaenge" SG_ 778 EngBrkStat 2;
BA_ "FlexKomSigName" SG_ 778 EngBrkStat "EngBrkStat";
BA_ "FlexKomComment" SG_ 778 EngBrkStat "Engine braking status";
BA_ "FlexKomIsMotorola" SG_ 778 EngBrkStat 1;
BA_ "GenSigSNA" SG_ 778 EngBrkStat "3h";
BA_ "GenSigCycleTime" SG_ 778 TrboBstPress 100;
BA_ "FlexKomSigStartValue" SG_ 778 TrboBstPress "00h";
BA_ "GenSigTimeout_IC" SG_ 778 TrboBstPress 1050;
BA_ "FlexKomSID" SG_ 778 TrboBstPress 1666;
BA_ "FlexKomSigStartPos" SG_ 778 TrboBstPress 55;
BA_ "FlexKomSigLaenge" SG_ 778 TrboBstPress 8;
BA_ "FlexKomSigName" SG_ 778 TrboBstPress "TrboBstPress";
BA_ "FlexKomComment" SG_ 778 TrboBstPress "Turbo boost pressure";
BA_ "FlexKomIsMotorola" SG_ 778 TrboBstPress 1;
BA_ "GenSigSNA" SG_ 778 TrboBstPress "FFh";
BA_ "GenSigCycleTime" SG_ 778 EB_Pwr 100;
BA_ "FlexKomSigStartValue" SG_ 778 EB_Pwr "00h";
BA_ "GenSigTimeout_IC" SG_ 778 EB_Pwr 1050;
BA_ "FlexKomSID" SG_ 778 EB_Pwr 1667;
BA_ "FlexKomSigStartPos" SG_ 778 EB_Pwr 63;
BA_ "FlexKomSigLaenge" SG_ 778 EB_Pwr 8;
BA_ "FlexKomSigName" SG_ 778 EB_Pwr "EB_Pwr";
BA_ "FlexKomComment" SG_ 778 EB_Pwr "Exhaust brake Power";
BA_ "FlexKomIsMotorola" SG_ 778 EB_Pwr 1;
BA_ "GenSigSNA" SG_ 778 EB_Pwr "FFh";
BA_ "GenSigCycleTime" SG_ 779 DisOilLifeRst 1000;
BA_ "FlexKomSigStartValue" SG_ 779 DisOilLifeRst "FFFFFF0FFFh";
BA_ "GenSigStartValue" SG_ 779 DisOilLifeRst 65535;
BA_ "GenSigTimeout_CBC" SG_ 779 DisOilLifeRst 10500;
BA_ "GenSigTimeout_IC" SG_ 779 DisOilLifeRst 10500;
BA_ "GenSigTimeout_ETM" SG_ 779 DisOilLifeRst 10500;
BA_ "FlexKomSID" SG_ 779 DisOilLifeRst 1668;
BA_ "FlexKomSigStartPos" SG_ 779 DisOilLifeRst 7;
BA_ "FlexKomSigLaenge" SG_ 779 DisOilLifeRst 40;
BA_ "FlexKomSigName" SG_ 779 DisOilLifeRst "OilLifePkt";
BA_ "FlexKomComment" SG_ 779 DisOilLifeRst "Oil life packet";
BA_ "FlexKomIsMotorola" SG_ 779 DisOilLifeRst 1;
BA_ "GenSigSNA" SG_ 779 DisOilLifeRst "FFFFh";
BA_ "GenSigCycleTime" SG_ 779 OilLifeLeft 1000;
BA_ "FlexKomSigStartValue" SG_ 779 OilLifeLeft "FFFFFF0FFFh";
BA_ "GenSigStartValue" SG_ 779 OilLifeLeft 255;
BA_ "GenSigTimeout_IC" SG_ 779 OilLifeLeft 10500;
BA_ "GenSigTimeout_ETM" SG_ 779 OilLifeLeft 10500;
BA_ "FlexKomSID" SG_ 779 OilLifeLeft 1668;
BA_ "FlexKomSigStartPos" SG_ 779 OilLifeLeft 7;
BA_ "FlexKomSigLaenge" SG_ 779 OilLifeLeft 40;
BA_ "FlexKomSigName" SG_ 779 OilLifeLeft "OilLifePkt";
BA_ "FlexKomComment" SG_ 779 OilLifeLeft "Oil life packet";
BA_ "FlexKomIsMotorola" SG_ 779 OilLifeLeft 1;
BA_ "GenSigSNA" SG_ 779 OilLifeLeft "FFh";
BA_ "GenSigCycleTime" SG_ 779 HoursOilLifeRst 1000;
BA_ "FlexKomSigStartValue" SG_ 779 HoursOilLifeRst "FFFFFF0FFFh";
BA_ "GenSigStartValue" SG_ 779 HoursOilLifeRst 4095;
BA_ "GenSigTimeout_CBC" SG_ 779 HoursOilLifeRst 10500;
BA_ "GenSigTimeout_IC" SG_ 779 HoursOilLifeRst 10500;
BA_ "GenSigTimeout_ETM" SG_ 779 HoursOilLifeRst 10500;
BA_ "FlexKomSID" SG_ 779 HoursOilLifeRst 1668;
BA_ "FlexKomSigStartPos" SG_ 779 HoursOilLifeRst 7;
BA_ "FlexKomSigLaenge" SG_ 779 HoursOilLifeRst 40;
BA_ "FlexKomSigName" SG_ 779 HoursOilLifeRst "OilLifePkt";
BA_ "FlexKomComment" SG_ 779 HoursOilLifeRst "Oil life packet";
BA_ "FlexKomIsMotorola" SG_ 779 HoursOilLifeRst 1;
BA_ "GenSigSNA" SG_ 779 HoursOilLifeRst "FFFh";
BA_ "GenSigCycleTime" SG_ 779 MntncSts 1000;
BA_ "FlexKomSigStartValue" SG_ 779 MntncSts "FFFFFF0FFFh";
BA_ "GenSigTimeout_IC" SG_ 779 MntncSts 10500;
BA_ "GenSigTimeout_ETM" SG_ 779 MntncSts 10500;
BA_ "FlexKomSID" SG_ 779 MntncSts 1668;
BA_ "FlexKomSigStartPos" SG_ 779 MntncSts 7;
BA_ "FlexKomSigLaenge" SG_ 779 MntncSts 40;
BA_ "FlexKomSigName" SG_ 779 MntncSts "OilLifePkt";
BA_ "FlexKomComment" SG_ 779 MntncSts "Oil life packet";
BA_ "FlexKomIsMotorola" SG_ 779 MntncSts 1;
BA_ "GenSigSNA" SG_ 779 MntncSts "3h";
BA_ "GenSigCycleTime" SG_ 779 OilLifeLeftRst 1000;
BA_ "FlexKomSigStartValue" SG_ 779 OilLifeLeftRst "FFFFFF0FFFh";
BA_ "GenSigTimeout_ETM" SG_ 779 OilLifeLeftRst 10500;
BA_ "FlexKomSID" SG_ 779 OilLifeLeftRst 1668;
BA_ "FlexKomSigStartPos" SG_ 779 OilLifeLeftRst 7;
BA_ "FlexKomSigLaenge" SG_ 779 OilLifeLeftRst 40;
BA_ "FlexKomSigName" SG_ 779 OilLifeLeftRst "OilLifePkt";
BA_ "FlexKomComment" SG_ 779 OilLifeLeftRst "Oil life packet";
BA_ "FlexKomIsMotorola" SG_ 779 OilLifeLeftRst 1;
BA_ "GenSigSNA" SG_ 779 OilLifeLeftRst "0h";
BA_ "GenSigCycleTime" SG_ 780 ActualForce 100;
BA_ "FlexKomSigStartValue" SG_ 780 ActualForce "0000000000000000h";
BA_ "FlexKomSID" SG_ 780 ActualForce 1651;
BA_ "FlexKomSigStartPos" SG_ 780 ActualForce 7;
BA_ "FlexKomSigLaenge" SG_ 780 ActualForce 64;
BA_ "FlexKomSigName" SG_ 780 ActualForce "EPB2_Pkt";
BA_ "FlexKomComment" SG_ 780 ActualForce "Electric parking brake 2 packet";
BA_ "FlexKomIsMotorola" SG_ 780 ActualForce 1;
BA_ "GenSigSNA" SG_ 780 ActualForce "0h";
BA_ "GenSigCycleTime" SG_ 780 DiagSessActv 100;
BA_ "FlexKomSigStartValue" SG_ 780 DiagSessActv "0000000000000000h";
BA_ "FlexKomSID" SG_ 780 DiagSessActv 1651;
BA_ "FlexKomSigStartPos" SG_ 780 DiagSessActv 7;
BA_ "FlexKomSigLaenge" SG_ 780 DiagSessActv 64;
BA_ "FlexKomSigName" SG_ 780 DiagSessActv "EPB2_Pkt";
BA_ "FlexKomComment" SG_ 780 DiagSessActv "Electric parking brake 2 packet";
BA_ "FlexKomIsMotorola" SG_ 780 DiagSessActv 1;
BA_ "GenSigSNA" SG_ 780 DiagSessActv "0h";
BA_ "GenSigCycleTime" SG_ 783 VehPerfAccelPeak_X_Pos 1000;
BA_ "FlexKomSigStartValue" SG_ 783 VehPerfAccelPeak_X_Pos "0000h";
BA_ "GenSigTimeout_ETM" SG_ 783 VehPerfAccelPeak_X_Pos 10500;
BA_ "FlexKomSID" SG_ 783 VehPerfAccelPeak_X_Pos 2107;
BA_ "FlexKomSigStartPos" SG_ 783 VehPerfAccelPeak_X_Pos 7;
BA_ "FlexKomSigLaenge" SG_ 783 VehPerfAccelPeak_X_Pos 16;
BA_ "FlexKomSigName" SG_ 783 VehPerfAccelPeak_X_Pos "VehPerfAccelPeak_X_Pos";
BA_ "FlexKomComment" SG_ 783 VehPerfAccelPeak_X_Pos "Vehicle longitudinal acceleration peak (forward)";
BA_ "FlexKomIsMotorola" SG_ 783 VehPerfAccelPeak_X_Pos 1;
BA_ "GenSigSNA" SG_ 783 VehPerfAccelPeak_X_Pos "1FFh";
BA_ "GenSigCycleTime" SG_ 783 VehPerfAccelPeak_X_Neg 1000;
BA_ "FlexKomSigStartValue" SG_ 783 VehPerfAccelPeak_X_Neg "01FEh";
BA_ "GenSigStartValue" SG_ 783 VehPerfAccelPeak_X_Neg 510;
BA_ "GenSigTimeout_ETM" SG_ 783 VehPerfAccelPeak_X_Neg 10500;
BA_ "FlexKomSID" SG_ 783 VehPerfAccelPeak_X_Neg 2105;
BA_ "FlexKomSigStartPos" SG_ 783 VehPerfAccelPeak_X_Neg 23;
BA_ "FlexKomSigLaenge" SG_ 783 VehPerfAccelPeak_X_Neg 16;
BA_ "FlexKomSigName" SG_ 783 VehPerfAccelPeak_X_Neg "VehPerfAccelPeak_X_Neg";
BA_ "FlexKomComment" SG_ 783 VehPerfAccelPeak_X_Neg "Vehicle longitudinal acceleration peak (rearward)";
BA_ "FlexKomIsMotorola" SG_ 783 VehPerfAccelPeak_X_Neg 1;
BA_ "GenSigSNA" SG_ 783 VehPerfAccelPeak_X_Neg "1FFh";
BA_ "GenSigCycleTime" SG_ 783 VehPerfAccelPeak_Y_Pos 1000;
BA_ "FlexKomSigStartValue" SG_ 783 VehPerfAccelPeak_Y_Pos "0000h";
BA_ "GenSigTimeout_ETM" SG_ 783 VehPerfAccelPeak_Y_Pos 10500;
BA_ "FlexKomSID" SG_ 783 VehPerfAccelPeak_Y_Pos 2106;
BA_ "FlexKomSigStartPos" SG_ 783 VehPerfAccelPeak_Y_Pos 39;
BA_ "FlexKomSigLaenge" SG_ 783 VehPerfAccelPeak_Y_Pos 16;
BA_ "FlexKomSigName" SG_ 783 VehPerfAccelPeak_Y_Pos "VehPerfAccelPeak_Y_Pos";
BA_ "FlexKomComment" SG_ 783 VehPerfAccelPeak_Y_Pos "Vehicle longitudinal acceleration peak (left)";
BA_ "FlexKomIsMotorola" SG_ 783 VehPerfAccelPeak_Y_Pos 1;
BA_ "GenSigSNA" SG_ 783 VehPerfAccelPeak_Y_Pos "1FFh";
BA_ "GenSigCycleTime" SG_ 783 VehPerfAccelPeak_Y_Neg 1000;
BA_ "FlexKomSigStartValue" SG_ 783 VehPerfAccelPeak_Y_Neg "01FEh";
BA_ "GenSigStartValue" SG_ 783 VehPerfAccelPeak_Y_Neg 510;
BA_ "GenSigTimeout_ETM" SG_ 783 VehPerfAccelPeak_Y_Neg 10500;
BA_ "FlexKomSID" SG_ 783 VehPerfAccelPeak_Y_Neg 2104;
BA_ "FlexKomSigStartPos" SG_ 783 VehPerfAccelPeak_Y_Neg 55;
BA_ "FlexKomSigLaenge" SG_ 783 VehPerfAccelPeak_Y_Neg 16;
BA_ "FlexKomSigName" SG_ 783 VehPerfAccelPeak_Y_Neg "VehPerfAccelPeak_Y_Neg";
BA_ "FlexKomComment" SG_ 783 VehPerfAccelPeak_Y_Neg "Vehicle longitudinal acceleration peak (right)";
BA_ "FlexKomIsMotorola" SG_ 783 VehPerfAccelPeak_Y_Neg 1;
BA_ "GenSigSNA" SG_ 783 VehPerfAccelPeak_Y_Neg "1FFh";
BA_ "GenSigSendType" SG_ 784 AvgFuelLvl 5;
BA_ "GenSigCycleTime" SG_ 784 AvgFuelLvl 1000;
BA_ "FlexKomSigStartValue" SG_ 784 AvgFuelLvl "01FFh";
BA_ "GenSigStartValue" SG_ 784 AvgFuelLvl 511;
BA_ "GenSigTimeout_CBC" SG_ 784 AvgFuelLvl 10500;
BA_ "GenSigTimeout_ETM" SG_ 784 AvgFuelLvl 10500;
BA_ "FlexKomSID" SG_ 784 AvgFuelLvl 848;
BA_ "FlexKomSigStartPos" SG_ 784 AvgFuelLvl 7;
BA_ "FlexKomSigLaenge" SG_ 784 AvgFuelLvl 16;
BA_ "FlexKomSigName" SG_ 784 AvgFuelLvl "AvgFuelLvl";
BA_ "FlexKomComment" SG_ 784 AvgFuelLvl "Average filtered fuel level in liters";
BA_ "FlexKomIsMotorola" SG_ 784 AvgFuelLvl 1;
BA_ "GenSigSNA" SG_ 784 AvgFuelLvl "1FFh";
BA_ "GenSigSendType" SG_ 784 WarnPrio1_Mute_Rq 5;
BA_ "GenSigCycleTime" SG_ 784 WarnPrio1_Mute_Rq 1000;
BA_ "FlexKomSigStartValue" SG_ 784 WarnPrio1_Mute_Rq "00h";
BA_ "FlexKomSID" SG_ 784 WarnPrio1_Mute_Rq 821;
BA_ "FlexKomSigStartPos" SG_ 784 WarnPrio1_Mute_Rq 1;
BA_ "FlexKomSigLaenge" SG_ 784 WarnPrio1_Mute_Rq 1;
BA_ "FlexKomSigName" SG_ 784 WarnPrio1_Mute_Rq "WarnPrio1_Mute_Rq";
BA_ "FlexKomComment" SG_ 784 WarnPrio1_Mute_Rq "Priority 1 mute request for soundamplifier";
BA_ "FlexKomIsMotorola" SG_ 784 WarnPrio1_Mute_Rq 1;
BA_ "GenSigSNA" SG_ 784 WarnPrio1_Mute_Rq "0h";
BA_ "GenSigSendType" SG_ 784 PCODE_CTRL 5;
BA_ "GenSigCycleTime" SG_ 784 PCODE_CTRL 1000;
BA_ "FlexKomSigStartValue" SG_ 784 PCODE_CTRL "00h";
BA_ "FlexKomSID" SG_ 784 PCODE_CTRL 850;
BA_ "FlexKomSigStartPos" SG_ 784 PCODE_CTRL 3;
BA_ "FlexKomSigLaenge" SG_ 784 PCODE_CTRL 2;
BA_ "FlexKomSigName" SG_ 784 PCODE_CTRL "PCODE_CTRL";
BA_ "FlexKomComment" SG_ 784 PCODE_CTRL "P-Code control signal from CCN";
BA_ "FlexKomIsMotorola" SG_ 784 PCODE_CTRL 1;
BA_ "GenSigSNA" SG_ 784 PCODE_CTRL "3h";
BA_ "GenSigSendType" SG_ 784 SRS_LMP_STAT 5;
BA_ "GenSigCycleTime" SG_ 784 SRS_LMP_STAT 1000;
BA_ "FlexKomSigStartValue" SG_ 784 SRS_LMP_STAT "00h";
BA_ "GenSigTimeout_ORC" SG_ 784 SRS_LMP_STAT 3500;
BA_ "GenSigTimeout_ETM" SG_ 784 SRS_LMP_STAT 10500;
BA_ "FlexKomSID" SG_ 784 SRS_LMP_STAT 851;
BA_ "FlexKomSigStartPos" SG_ 784 SRS_LMP_STAT 5;
BA_ "FlexKomSigLaenge" SG_ 784 SRS_LMP_STAT 2;
BA_ "FlexKomSigName" SG_ 784 SRS_LMP_STAT "SRS_LMP_STAT";
BA_ "FlexKomComment" SG_ 784 SRS_LMP_STAT "Airbag indicator lamp status";
BA_ "FlexKomIsMotorola" SG_ 784 SRS_LMP_STAT 1;
BA_ "GenSigSNA" SG_ 784 SRS_LMP_STAT "3h";
BA_ "GenSigSendType" SG_ 784 FuelLvlLow 5;
BA_ "GenSigCycleTime" SG_ 784 FuelLvlLow 1000;
BA_ "FlexKomSigStartValue" SG_ 784 FuelLvlLow "00h";
BA_ "GenSigTimeout_CBC" SG_ 784 FuelLvlLow 10500;
BA_ "FlexKomSID" SG_ 784 FuelLvlLow 1049;
BA_ "FlexKomSigStartPos" SG_ 784 FuelLvlLow 6;
BA_ "FlexKomSigLaenge" SG_ 784 FuelLvlLow 1;
BA_ "FlexKomSigName" SG_ 784 FuelLvlLow "FuelLvlLow";
BA_ "FlexKomComment" SG_ 784 FuelLvlLow "Fuel level low";
BA_ "FlexKomIsMotorola" SG_ 784 FuelLvlLow 1;
BA_ "GenSigSNA" SG_ 784 FuelLvlLow "0h";
BA_ "GenSigSendType" SG_ 784 WTS_LmpRqOn 5;
BA_ "GenSigCycleTime" SG_ 784 WTS_LmpRqOn 1000;
BA_ "FlexKomSigStartValue" SG_ 784 WTS_LmpRqOn "00h";
BA_ "FlexKomSID" SG_ 784 WTS_LmpRqOn 1559;
BA_ "FlexKomSigStartPos" SG_ 784 WTS_LmpRqOn 7;
BA_ "FlexKomSigLaenge" SG_ 784 WTS_LmpRqOn 1;
BA_ "FlexKomSigName" SG_ 784 WTS_LmpRqOn "WTS_LmpRqOn";
BA_ "FlexKomComment" SG_ 784 WTS_LmpRqOn "Wait to start lamp requested on; true = [1]";
BA_ "FlexKomIsMotorola" SG_ 784 WTS_LmpRqOn 1;
BA_ "GenSigSNA" SG_ 784 WTS_LmpRqOn "0h";
BA_ "GenSigSendType" SG_ 784 DPF_DEF_WrnStat 5;
BA_ "GenSigCycleTime" SG_ 784 DPF_DEF_WrnStat 1000;
BA_ "FlexKomSigStartValue" SG_ 784 DPF_DEF_WrnStat "00h";
BA_ "GenSigTimeout_ETM" SG_ 784 DPF_DEF_WrnStat 10500;
BA_ "FlexKomSID" SG_ 784 DPF_DEF_WrnStat 1444;
BA_ "FlexKomSigStartPos" SG_ 784 DPF_DEF_WrnStat 19;
BA_ "FlexKomSigLaenge" SG_ 784 DPF_DEF_WrnStat 4;
BA_ "FlexKomSigName" SG_ 784 DPF_DEF_WrnStat "DPF_DEF_WrnStat";
BA_ "FlexKomComment" SG_ 784 DPF_DEF_WrnStat "DPF DEF warning status";
BA_ "FlexKomIsMotorola" SG_ 784 DPF_DEF_WrnStat 1;
BA_ "GenSigSNA" SG_ 784 DPF_DEF_WrnStat "Fh";
BA_ "GenSigSendType" SG_ 784 Radio_Strng_Rq 5;
BA_ "GenSigCycleTime" SG_ 784 Radio_Strng_Rq 1000;
BA_ "FlexKomSigStartValue" SG_ 784 Radio_Strng_Rq "00h";
BA_ "FlexKomSID" SG_ 784 Radio_Strng_Rq 1351;
BA_ "FlexKomSigStartPos" SG_ 784 Radio_Strng_Rq 20;
BA_ "FlexKomSigLaenge" SG_ 784 Radio_Strng_Rq 1;
BA_ "FlexKomSigName" SG_ 784 Radio_Strng_Rq "Radio_Strng_Rq";
BA_ "FlexKomComment" SG_ 784 Radio_Strng_Rq "IC request for Audio to resend radio string inform";
BA_ "FlexKomIsMotorola" SG_ 784 Radio_Strng_Rq 1;
BA_ "GenSigSNA" SG_ 784 Radio_Strng_Rq "0h";
BA_ "GenSigSendType" SG_ 784 FuelSavDispEnbl 5;
BA_ "GenSigCycleTime" SG_ 784 FuelSavDispEnbl 1000;
BA_ "FlexKomSigStartValue" SG_ 784 FuelSavDispEnbl "00h";
BA_ "FlexKomSID" SG_ 784 FuelSavDispEnbl 1330;
BA_ "FlexKomSigStartPos" SG_ 784 FuelSavDispEnbl 21;
BA_ "FlexKomSigLaenge" SG_ 784 FuelSavDispEnbl 1;
BA_ "FlexKomSigName" SG_ 784 FuelSavDispEnbl "FuelSavDispEnbl";
BA_ "FlexKomComment" SG_ 784 FuelSavDispEnbl "Fuel saver display indicator status (1=enabled)";
BA_ "FlexKomIsMotorola" SG_ 784 FuelSavDispEnbl 1;
BA_ "GenSigSNA" SG_ 784 FuelSavDispEnbl "0h";
BA_ "GenSigSendType" SG_ 784 ThatchamIC 5;
BA_ "GenSigCycleTime" SG_ 784 ThatchamIC 1000;
BA_ "FlexKomSigStartValue" SG_ 784 ThatchamIC "00h";
BA_ "FlexKomSID" SG_ 784 ThatchamIC 1572;
BA_ "FlexKomSigStartPos" SG_ 784 ThatchamIC 22;
BA_ "FlexKomSigLaenge" SG_ 784 ThatchamIC 1;
BA_ "FlexKomSigName" SG_ 784 ThatchamIC "ThatchamIC";
BA_ "FlexKomComment" SG_ 784 ThatchamIC "IC has learned the presence of Thatcham; true = [1";
BA_ "FlexKomIsMotorola" SG_ 784 ThatchamIC 1;
BA_ "GenSigSNA" SG_ 784 ThatchamIC "0h";
BA_ "GenSigSendType" SG_ 784 ACC_ScrnActv 5;
BA_ "GenSigCycleTime" SG_ 784 ACC_ScrnActv 1000;
BA_ "FlexKomSigStartValue" SG_ 784 ACC_ScrnActv "00h";
BA_ "FlexKomSID" SG_ 784 ACC_ScrnActv 1574;
BA_ "FlexKomSigStartPos" SG_ 784 ACC_ScrnActv 23;
BA_ "FlexKomSigLaenge" SG_ 784 ACC_ScrnActv 1;
BA_ "FlexKomSigName" SG_ 784 ACC_ScrnActv "ACC_ScrnActv";
BA_ "FlexKomComment" SG_ 784 ACC_ScrnActv "IC adaptive cruise in active display; True = [1]";
BA_ "FlexKomIsMotorola" SG_ 784 ACC_ScrnActv 1;
BA_ "GenSigSNA" SG_ 784 ACC_ScrnActv "0h";
BA_ "GenSigSendType" SG_ 784 Trailer_Trp_Rst 5;
BA_ "GenSigCycleTime" SG_ 784 Trailer_Trp_Rst 1000;
BA_ "FlexKomSigStartValue" SG_ 784 Trailer_Trp_Rst "00h";
BA_ "FlexKomSID" SG_ 784 Trailer_Trp_Rst 1829;
BA_ "FlexKomSigStartPos" SG_ 784 Trailer_Trp_Rst 28;
BA_ "FlexKomSigLaenge" SG_ 784 Trailer_Trp_Rst 1;
BA_ "FlexKomSigName" SG_ 784 Trailer_Trp_Rst "Trailer_Trp_Rst";
BA_ "FlexKomComment" SG_ 784 Trailer_Trp_Rst "Trailer Trip Reset Request";
BA_ "FlexKomIsMotorola" SG_ 784 Trailer_Trp_Rst 1;
BA_ "GenSigSNA" SG_ 784 Trailer_Trp_Rst "0h";
BA_ "GenSigSendType" SG_ 784 OilChgRst 5;
BA_ "GenSigCycleTime" SG_ 784 OilChgRst 1000;
BA_ "FlexKomSigStartValue" SG_ 784 OilChgRst "00h";
BA_ "FlexKomSID" SG_ 784 OilChgRst 1819;
BA_ "FlexKomSigStartPos" SG_ 784 OilChgRst 29;
BA_ "FlexKomSigLaenge" SG_ 784 OilChgRst 1;
BA_ "FlexKomSigName" SG_ 784 OilChgRst "OilChgRst";
BA_ "FlexKomComment" SG_ 784 OilChgRst "Oil change reminder reset request";
BA_ "FlexKomIsMotorola" SG_ 784 OilChgRst 1;
BA_ "GenSigSNA" SG_ 784 OilChgRst "0h";
BA_ "GenSigSendType" SG_ 784 FuelFltrRst 5;
BA_ "GenSigCycleTime" SG_ 784 FuelFltrRst 1000;
BA_ "FlexKomSigStartValue" SG_ 784 FuelFltrRst "00h";
BA_ "FlexKomSID" SG_ 784 FuelFltrRst 1810;
BA_ "FlexKomSigStartPos" SG_ 784 FuelFltrRst 30;
BA_ "FlexKomSigLaenge" SG_ 784 FuelFltrRst 1;
BA_ "FlexKomSigName" SG_ 784 FuelFltrRst "FuelFltrRst";
BA_ "FlexKomComment" SG_ 784 FuelFltrRst "Fuel filter maintenance reminder reset";
BA_ "FlexKomIsMotorola" SG_ 784 FuelFltrRst 1;
BA_ "GenSigSNA" SG_ 784 FuelFltrRst "0h";
BA_ "GenSigSendType" SG_ 784 ALM_Rq 5;
BA_ "GenSigCycleTime" SG_ 784 ALM_Rq 1000;
BA_ "FlexKomSigStartValue" SG_ 784 ALM_Rq "00h";
BA_ "FlexKomSID" SG_ 784 ALM_Rq 1791;
BA_ "FlexKomSigStartPos" SG_ 784 ALM_Rq 31;
BA_ "FlexKomSigLaenge" SG_ 784 ALM_Rq 1;
BA_ "FlexKomSigName" SG_ 784 ALM_Rq "ALM_Rq";
BA_ "FlexKomComment" SG_ 784 ALM_Rq "Auto load measurement request; On = [1]";
BA_ "FlexKomIsMotorola" SG_ 784 ALM_Rq 1;
BA_ "GenSigSNA" SG_ 784 ALM_Rq "0h";
BA_ "GenSigSendType" SG_ 784 ODO 5;
BA_ "GenSigCycleTime" SG_ 784 ODO 1000;
BA_ "FlexKomSigStartValue" SG_ 784 ODO "FFFFFFh";
BA_ "GenSigStartValue" SG_ 784 ODO 16777215;
BA_ "GenSigTimeout_RF_HUB" SG_ 784 ODO 10500;
BA_ "GenSigTimeout_CBC" SG_ 784 ODO 10500;
BA_ "GenSigTimeout_TPM" SG_ 784 ODO 10500;
BA_ "GenSigTimeout_AFLS" SG_ 784 ODO 10500;
BA_ "GenSigTimeout_EPS" SG_ 784 ODO 10500;
BA_ "GenSigTimeout_SCCM" SG_ 784 ODO 10500;
BA_ "GenSigTimeout_ESM" SG_ 784 ODO 10500;
BA_ "GenSigTimeout_DTCM" SG_ 784 ODO 10500;
BA_ "GenSigTimeout_ADCM" SG_ 784 ODO 25500;
BA_ "GenSigTimeout_ORC" SG_ 784 ODO 3500;
BA_ "FlexKomSID" SG_ 784 ODO 804;
BA_ "FlexKomSigStartPos" SG_ 784 ODO 39;
BA_ "FlexKomSigLaenge" SG_ 784 ODO 24;
BA_ "FlexKomSigName" SG_ 784 ODO "ODO";
BA_ "FlexKomComment" SG_ 784 ODO "Odometer";
BA_ "FlexKomIsMotorola" SG_ 784 ODO 1;
BA_ "GenSigSNA" SG_ 784 ODO "FFFFFFh";
BA_ "GenSigSendType" SG_ 784 PowerMode_RQ 5;
BA_ "GenSigCycleTime" SG_ 784 PowerMode_RQ 1000;
BA_ "FlexKomSigStartValue" SG_ 784 PowerMode_RQ "07h";
BA_ "GenSigStartValue" SG_ 784 PowerMode_RQ 7;
BA_ "GenSigTimeout_CBC" SG_ 784 PowerMode_RQ 10500;
BA_ "FlexKomSID" SG_ 784 PowerMode_RQ 1806;
BA_ "FlexKomSigStartPos" SG_ 784 PowerMode_RQ 58;
BA_ "FlexKomSigLaenge" SG_ 784 PowerMode_RQ 3;
BA_ "FlexKomSigName" SG_ 784 PowerMode_RQ "PowerMode_RQ";
BA_ "FlexKomComment" SG_ 784 PowerMode_RQ "Power Mode request";
BA_ "FlexKomIsMotorola" SG_ 784 PowerMode_RQ 1;
BA_ "GenSigSNA" SG_ 784 PowerMode_RQ "7h";
BA_ "GenSigSendType" SG_ 784 IC_IntrnlFlt 5;
BA_ "GenSigCycleTime" SG_ 784 IC_IntrnlFlt 1000;
BA_ "FlexKomSigStartValue" SG_ 784 IC_IntrnlFlt "00h";
BA_ "FlexKomSID" SG_ 784 IC_IntrnlFlt 1833;
BA_ "FlexKomSigStartPos" SG_ 784 IC_IntrnlFlt 59;
BA_ "FlexKomSigLaenge" SG_ 784 IC_IntrnlFlt 1;
BA_ "FlexKomSigName" SG_ 784 IC_IntrnlFlt "IC_IntrnlFlt";
BA_ "FlexKomComment" SG_ 784 IC_IntrnlFlt "Cluster internal fault active";
BA_ "FlexKomIsMotorola" SG_ 784 IC_IntrnlFlt 1;
BA_ "GenSigSNA" SG_ 784 IC_IntrnlFlt "0h";
BA_ "GenSigSendType" SG_ 784 PTS_MODE_SELECTION 5;
BA_ "GenSigCycleTime" SG_ 784 PTS_MODE_SELECTION 1000;
BA_ "FlexKomSigStartValue" SG_ 784 PTS_MODE_SELECTION "00h";
BA_ "GenSigTimeout_PTS" SG_ 784 PTS_MODE_SELECTION 10500;
BA_ "FlexKomSID" SG_ 784 PTS_MODE_SELECTION 1910;
BA_ "FlexKomSigStartPos" SG_ 784 PTS_MODE_SELECTION 62;
BA_ "FlexKomSigLaenge" SG_ 784 PTS_MODE_SELECTION 3;
BA_ "FlexKomSigName" SG_ 784 PTS_MODE_SELECTION "PTS_MODE_SELECTION";
BA_ "FlexKomComment" SG_ 784 PTS_MODE_SELECTION "Park assist maneuver selection for PTS";
BA_ "FlexKomIsMotorola" SG_ 784 PTS_MODE_SELECTION 1;
BA_ "GenSigSNA" SG_ 784 PTS_MODE_SELECTION "7h";
BA_ "GenSigSendType" SG_ 788 CFG_FEATURE 2;
BA_ "GenSigCycleTimeActive" SG_ 788 CFG_FEATURE 50;
BA_ "FlexKomSigStartValue" SG_ 788 CFG_FEATURE "000000h";
BA_ "FlexKomSID" SG_ 788 CFG_FEATURE 442;
BA_ "FlexKomSigStartPos" SG_ 788 CFG_FEATURE 7;
BA_ "FlexKomSigLaenge" SG_ 788 CFG_FEATURE 24;
BA_ "FlexKomSigName" SG_ 788 CFG_FEATURE "CFG_RQ";
BA_ "FlexKomComment" SG_ 788 CFG_FEATURE "Configurable display request";
BA_ "FlexKomIsMotorola" SG_ 788 CFG_FEATURE 1;
BA_ "GenSigSNA" SG_ 788 CFG_FEATURE "0h";
BA_ "GenSigSendType" SG_ 788 CFG_STAT_RQ 2;
BA_ "GenSigCycleTimeActive" SG_ 788 CFG_STAT_RQ 50;
BA_ "FlexKomSigStartValue" SG_ 788 CFG_STAT_RQ "000000h";
BA_ "FlexKomSID" SG_ 788 CFG_STAT_RQ 442;
BA_ "FlexKomSigStartPos" SG_ 788 CFG_STAT_RQ 7;
BA_ "FlexKomSigLaenge" SG_ 788 CFG_STAT_RQ 24;
BA_ "FlexKomSigName" SG_ 788 CFG_STAT_RQ "CFG_RQ";
BA_ "FlexKomComment" SG_ 788 CFG_STAT_RQ "Configurable display request";
BA_ "FlexKomIsMotorola" SG_ 788 CFG_STAT_RQ 1;
BA_ "GenSigSNA" SG_ 788 CFG_STAT_RQ "0h";
BA_ "GenSigSendType" SG_ 788 CFG_SET 2;
BA_ "GenSigCycleTimeActive" SG_ 788 CFG_SET 50;
BA_ "FlexKomSigStartValue" SG_ 788 CFG_SET "000000h";
BA_ "FlexKomSID" SG_ 788 CFG_SET 442;
BA_ "FlexKomSigStartPos" SG_ 788 CFG_SET 7;
BA_ "FlexKomSigLaenge" SG_ 788 CFG_SET 24;
BA_ "FlexKomSigName" SG_ 788 CFG_SET "CFG_RQ";
BA_ "FlexKomComment" SG_ 788 CFG_SET "Configurable display request";
BA_ "FlexKomIsMotorola" SG_ 788 CFG_SET 1;
BA_ "GenSigSNA" SG_ 788 CFG_SET "0h";
BA_ "GenSigSendType" SG_ 789 CfgFeature 2;
BA_ "GenSigCycleTimeActive" SG_ 789 CfgFeature 50;
BA_ "FlexKomSigStartValue" SG_ 789 CfgFeature "000000h";
BA_ "FlexKomSID" SG_ 789 CfgFeature 1563;
BA_ "FlexKomSigStartPos" SG_ 789 CfgFeature 7;
BA_ "FlexKomSigLaenge" SG_ 789 CfgFeature 24;
BA_ "FlexKomSigName" SG_ 789 CfgFeature "CfgRqIC";
BA_ "FlexKomComment" SG_ 789 CfgFeature "Configurable display request from IC";
BA_ "FlexKomIsMotorola" SG_ 789 CfgFeature 1;
BA_ "GenSigSNA" SG_ 789 CfgFeature "0h";
BA_ "GenSigSendType" SG_ 789 CfgStatRq 2;
BA_ "GenSigCycleTimeActive" SG_ 789 CfgStatRq 50;
BA_ "FlexKomSigStartValue" SG_ 789 CfgStatRq "000000h";
BA_ "FlexKomSID" SG_ 789 CfgStatRq 1563;
BA_ "FlexKomSigStartPos" SG_ 789 CfgStatRq 7;
BA_ "FlexKomSigLaenge" SG_ 789 CfgStatRq 24;
BA_ "FlexKomSigName" SG_ 789 CfgStatRq "CfgRqIC";
BA_ "FlexKomComment" SG_ 789 CfgStatRq "Configurable display request from IC";
BA_ "FlexKomIsMotorola" SG_ 789 CfgStatRq 1;
BA_ "GenSigSNA" SG_ 789 CfgStatRq "0h";
BA_ "GenSigSendType" SG_ 789 CfgSet 2;
BA_ "GenSigCycleTimeActive" SG_ 789 CfgSet 50;
BA_ "FlexKomSigStartValue" SG_ 789 CfgSet "000000h";
BA_ "FlexKomSID" SG_ 789 CfgSet 1563;
BA_ "FlexKomSigStartPos" SG_ 789 CfgSet 7;
BA_ "FlexKomSigLaenge" SG_ 789 CfgSet 24;
BA_ "FlexKomSigName" SG_ 789 CfgSet "CfgRqIC";
BA_ "FlexKomComment" SG_ 789 CfgSet "Configurable display request from IC";
BA_ "FlexKomIsMotorola" SG_ 789 CfgSet 1;
BA_ "GenSigSNA" SG_ 789 CfgSet "0h";
BA_ "GenSigSendType" SG_ 790 CFG_FEATURE_C 2;
BA_ "GenSigCycleTimeActive" SG_ 790 CFG_FEATURE_C 50;
BA_ "FlexKomSigStartValue" SG_ 790 CFG_FEATURE_C "000000h";
BA_ "FlexKomSID" SG_ 790 CFG_FEATURE_C 1679;
BA_ "FlexKomSigStartPos" SG_ 790 CFG_FEATURE_C 7;
BA_ "FlexKomSigLaenge" SG_ 790 CFG_FEATURE_C 24;
BA_ "FlexKomSigName" SG_ 790 CFG_FEATURE_C "CFG_RQ_C";
BA_ "FlexKomComment" SG_ 790 CFG_FEATURE_C "Configurable display request - from CAN C";
BA_ "FlexKomIsMotorola" SG_ 790 CFG_FEATURE_C 1;
BA_ "GenSigSNA" SG_ 790 CFG_FEATURE_C "0h";
BA_ "GenSigSendType" SG_ 790 CFG_STAT_RQ_C 2;
BA_ "GenSigCycleTimeActive" SG_ 790 CFG_STAT_RQ_C 50;
BA_ "FlexKomSigStartValue" SG_ 790 CFG_STAT_RQ_C "000000h";
BA_ "FlexKomSID" SG_ 790 CFG_STAT_RQ_C 1679;
BA_ "FlexKomSigStartPos" SG_ 790 CFG_STAT_RQ_C 7;
BA_ "FlexKomSigLaenge" SG_ 790 CFG_STAT_RQ_C 24;
BA_ "FlexKomSigName" SG_ 790 CFG_STAT_RQ_C "CFG_RQ_C";
BA_ "FlexKomComment" SG_ 790 CFG_STAT_RQ_C "Configurable display request - from CAN C";
BA_ "FlexKomIsMotorola" SG_ 790 CFG_STAT_RQ_C 1;
BA_ "GenSigSNA" SG_ 790 CFG_STAT_RQ_C "0h";
BA_ "GenSigSendType" SG_ 790 CFG_SET_C 2;
BA_ "GenSigCycleTimeActive" SG_ 790 CFG_SET_C 50;
BA_ "FlexKomSigStartValue" SG_ 790 CFG_SET_C "000000h";
BA_ "FlexKomSID" SG_ 790 CFG_SET_C 1679;
BA_ "FlexKomSigStartPos" SG_ 790 CFG_SET_C 7;
BA_ "FlexKomSigLaenge" SG_ 790 CFG_SET_C 24;
BA_ "FlexKomSigName" SG_ 790 CFG_SET_C "CFG_RQ_C";
BA_ "FlexKomComment" SG_ 790 CFG_SET_C "Configurable display request - from CAN C";
BA_ "FlexKomIsMotorola" SG_ 790 CFG_SET_C 1;
BA_ "GenSigSNA" SG_ 790 CFG_SET_C "0h";
BA_ "GenSigSendType" SG_ 792 TurnIndLvr_Stat 5;
BA_ "GenSigCycleTime" SG_ 792 TurnIndLvr_Stat 100;
BA_ "FlexKomSigStartValue" SG_ 792 TurnIndLvr_Stat "000000000000FF00h";
BA_ "GenSigTimeout_PTS" SG_ 792 TurnIndLvr_Stat 1050;
BA_ "FlexKomSID" SG_ 792 TurnIndLvr_Stat 420;
BA_ "FlexKomSigStartPos" SG_ 792 TurnIndLvr_Stat 7;
BA_ "FlexKomSigLaenge" SG_ 792 TurnIndLvr_Stat 64;
BA_ "FlexKomSigName" SG_ 792 TurnIndLvr_Stat "StW_Actn_Rq";
BA_ "FlexKomComment" SG_ 792 TurnIndLvr_Stat "Steering wheel actuation request";
BA_ "FlexKomIsMotorola" SG_ 792 TurnIndLvr_Stat 1;
BA_ "GenSigSNA" SG_ 792 TurnIndLvr_Stat "0h";
BA_ "GenSigSendType" SG_ 792 HiBmLvr_Stat 5;
BA_ "GenSigCycleTime" SG_ 792 HiBmLvr_Stat 100;
BA_ "FlexKomSigStartValue" SG_ 792 HiBmLvr_Stat "000000000000FF00h";
BA_ "FlexKomSID" SG_ 792 HiBmLvr_Stat 420;
BA_ "FlexKomSigStartPos" SG_ 792 HiBmLvr_Stat 7;
BA_ "FlexKomSigLaenge" SG_ 792 HiBmLvr_Stat 64;
BA_ "FlexKomSigName" SG_ 792 HiBmLvr_Stat "StW_Actn_Rq";
BA_ "FlexKomComment" SG_ 792 HiBmLvr_Stat "Steering wheel actuation request";
BA_ "FlexKomIsMotorola" SG_ 792 HiBmLvr_Stat 1;
BA_ "GenSigSNA" SG_ 792 HiBmLvr_Stat "0h";
BA_ "GenSigSendType" SG_ 792 WprWashSw_Psd 5;
BA_ "GenSigCycleTime" SG_ 792 WprWashSw_Psd 100;
BA_ "FlexKomSigStartValue" SG_ 792 WprWashSw_Psd "000000000000FF00h";
BA_ "FlexKomSID" SG_ 792 WprWashSw_Psd 420;
BA_ "FlexKomSigStartPos" SG_ 792 WprWashSw_Psd 7;
BA_ "FlexKomSigLaenge" SG_ 792 WprWashSw_Psd 64;
BA_ "FlexKomSigName" SG_ 792 WprWashSw_Psd "StW_Actn_Rq";
BA_ "FlexKomComment" SG_ 792 WprWashSw_Psd "Steering wheel actuation request";
BA_ "FlexKomIsMotorola" SG_ 792 WprWashSw_Psd 1;
BA_ "GenSigSNA" SG_ 792 WprWashSw_Psd "0h";
BA_ "GenSigSendType" SG_ 792 HrnSw_Psd 5;
BA_ "GenSigCycleTime" SG_ 792 HrnSw_Psd 100;
BA_ "FlexKomSigStartValue" SG_ 792 HrnSw_Psd "000000000000FF00h";
BA_ "FlexKomSID" SG_ 792 HrnSw_Psd 420;
BA_ "FlexKomSigStartPos" SG_ 792 HrnSw_Psd 7;
BA_ "FlexKomSigLaenge" SG_ 792 HrnSw_Psd 64;
BA_ "FlexKomSigName" SG_ 792 HrnSw_Psd "StW_Actn_Rq";
BA_ "FlexKomComment" SG_ 792 HrnSw_Psd "Steering wheel actuation request";
BA_ "FlexKomIsMotorola" SG_ 792 HrnSw_Psd 1;
BA_ "GenSigSNA" SG_ 792 HrnSw_Psd "0h";
BA_ "GenSigSendType" SG_ 792 StW_Cond_Flt 5;
BA_ "GenSigCycleTime" SG_ 792 StW_Cond_Flt 100;
BA_ "FlexKomSigStartValue" SG_ 792 StW_Cond_Flt "000000000000FF00h";
BA_ "FlexKomSID" SG_ 792 StW_Cond_Flt 420;
BA_ "FlexKomSigStartPos" SG_ 792 StW_Cond_Flt 7;
BA_ "FlexKomSigLaenge" SG_ 792 StW_Cond_Flt 64;
BA_ "FlexKomSigName" SG_ 792 StW_Cond_Flt "StW_Actn_Rq";
BA_ "FlexKomComment" SG_ 792 StW_Cond_Flt "Steering wheel actuation request";
BA_ "FlexKomIsMotorola" SG_ 792 StW_Cond_Flt 1;
BA_ "GenSigSNA" SG_ 792 StW_Cond_Flt "0h";
BA_ "GenSigSendType" SG_ 792 WprWash_R_Sw_Posn_V3 5;
BA_ "GenSigCycleTime" SG_ 792 WprWash_R_Sw_Posn_V3 100;
BA_ "FlexKomSigStartValue" SG_ 792 WprWash_R_Sw_Posn_V3 "000000000000FF00h";
BA_ "FlexKomSID" SG_ 792 WprWash_R_Sw_Posn_V3 420;
BA_ "FlexKomSigStartPos" SG_ 792 WprWash_R_Sw_Posn_V3 7;
BA_ "FlexKomSigLaenge" SG_ 792 WprWash_R_Sw_Posn_V3 64;
BA_ "FlexKomSigName" SG_ 792 WprWash_R_Sw_Posn_V3 "StW_Actn_Rq";
BA_ "FlexKomComment" SG_ 792 WprWash_R_Sw_Posn_V3 "Steering wheel actuation request";
BA_ "FlexKomIsMotorola" SG_ 792 WprWash_R_Sw_Posn_V3 1;
BA_ "GenSigSNA" SG_ 792 WprWash_R_Sw_Posn_V3 "0h";
BA_ "GenSigSendType" SG_ 792 StW_Lvr_Stat 5;
BA_ "GenSigCycleTime" SG_ 792 StW_Lvr_Stat 100;
BA_ "FlexKomSigStartValue" SG_ 792 StW_Lvr_Stat "000000000000FF00h";
BA_ "FlexKomSID" SG_ 792 StW_Lvr_Stat 420;
BA_ "FlexKomSigStartPos" SG_ 792 StW_Lvr_Stat 7;
BA_ "FlexKomSigLaenge" SG_ 792 StW_Lvr_Stat 64;
BA_ "FlexKomSigName" SG_ 792 StW_Lvr_Stat "StW_Actn_Rq";
BA_ "FlexKomComment" SG_ 792 StW_Lvr_Stat "Steering wheel actuation request";
BA_ "FlexKomIsMotorola" SG_ 792 StW_Lvr_Stat 1;
BA_ "GenSigSNA" SG_ 792 StW_Lvr_Stat "0h";
BA_ "GenSigSendType" SG_ 792 WprSw6Posn 5;
BA_ "GenSigCycleTime" SG_ 792 WprSw6Posn 100;
BA_ "FlexKomSigStartValue" SG_ 792 WprSw6Posn "000000000000FF00h";
BA_ "GenSigTimeout_CBC" SG_ 792 WprSw6Posn 1050;
BA_ "FlexKomSID" SG_ 792 WprSw6Posn 420;
BA_ "FlexKomSigStartPos" SG_ 792 WprSw6Posn 7;
BA_ "FlexKomSigLaenge" SG_ 792 WprSw6Posn 64;
BA_ "FlexKomSigName" SG_ 792 WprSw6Posn "StW_Actn_Rq";
BA_ "FlexKomComment" SG_ 792 WprSw6Posn "Steering wheel actuation request";
BA_ "FlexKomIsMotorola" SG_ 792 WprSw6Posn 1;
BA_ "GenSigSNA" SG_ 792 WprSw6Posn "Fh";
BA_ "GenSigSendType" SG_ 796 RBT_D_Actv 5;
BA_ "GenSigCycleTime" SG_ 796 RBT_D_Actv 1000;
BA_ "FlexKomSigStartValue" SG_ 796 RBT_D_Actv "0000000000000000h";
BA_ "FlexKomSID" SG_ 796 RBT_D_Actv 845;
BA_ "FlexKomSigStartPos" SG_ 796 RBT_D_Actv 7;
BA_ "FlexKomSigLaenge" SG_ 796 RBT_D_Actv 64;
BA_ "FlexKomSigName" SG_ 796 RBT_D_Actv "RBT_D_PKT";
BA_ "FlexKomComment" SG_ 796 RBT_D_Actv "RBT_D_PKT";
BA_ "FlexKomIsMotorola" SG_ 796 RBT_D_Actv 1;
BA_ "GenSigSNA" SG_ 796 RBT_D_Actv "0h";
BA_ "GenSigSendType" SG_ 796 RBT_D_OK 5;
BA_ "GenSigCycleTime" SG_ 796 RBT_D_OK 1000;
BA_ "FlexKomSigStartValue" SG_ 796 RBT_D_OK "0000000000000000h";
BA_ "FlexKomSID" SG_ 796 RBT_D_OK 845;
BA_ "FlexKomSigStartPos" SG_ 796 RBT_D_OK 7;
BA_ "FlexKomSigLaenge" SG_ 796 RBT_D_OK 64;
BA_ "FlexKomSigName" SG_ 796 RBT_D_OK "RBT_D_PKT";
BA_ "FlexKomComment" SG_ 796 RBT_D_OK "RBT_D_PKT";
BA_ "FlexKomIsMotorola" SG_ 796 RBT_D_OK 1;
BA_ "GenSigSNA" SG_ 796 RBT_D_OK "0h";
BA_ "GenSigSendType" SG_ 796 DRV_RBT_Fault 5;
BA_ "GenSigCycleTime" SG_ 796 DRV_RBT_Fault 1000;
BA_ "FlexKomSigStartValue" SG_ 796 DRV_RBT_Fault "0000000000000000h";
BA_ "GenSigTimeout_IC" SG_ 796 DRV_RBT_Fault 10500;
BA_ "FlexKomSID" SG_ 796 DRV_RBT_Fault 845;
BA_ "FlexKomSigStartPos" SG_ 796 DRV_RBT_Fault 7;
BA_ "FlexKomSigLaenge" SG_ 796 DRV_RBT_Fault 64;
BA_ "FlexKomSigName" SG_ 796 DRV_RBT_Fault "RBT_D_PKT";
BA_ "FlexKomComment" SG_ 796 DRV_RBT_Fault "RBT_D_PKT";
BA_ "FlexKomIsMotorola" SG_ 796 DRV_RBT_Fault 1;
BA_ "GenSigSNA" SG_ 796 DRV_RBT_Fault "1h";
BA_ "GenSigSendType" SG_ 796 DRV_RBT_ACT 5;
BA_ "GenSigCycleTime" SG_ 796 DRV_RBT_ACT 1000;
BA_ "FlexKomSigStartValue" SG_ 796 DRV_RBT_ACT "0000000000000000h";
BA_ "FlexKomSID" SG_ 796 DRV_RBT_ACT 845;
BA_ "FlexKomSigStartPos" SG_ 796 DRV_RBT_ACT 7;
BA_ "FlexKomSigLaenge" SG_ 796 DRV_RBT_ACT 64;
BA_ "FlexKomSigName" SG_ 796 DRV_RBT_ACT "RBT_D_PKT";
BA_ "FlexKomComment" SG_ 796 DRV_RBT_ACT "RBT_D_PKT";
BA_ "FlexKomIsMotorola" SG_ 796 DRV_RBT_ACT 1;
BA_ "GenSigSNA" SG_ 796 DRV_RBT_ACT "3h";
BA_ "GenSigCycleTime" SG_ 799 IBS_R_Batt 1000;
BA_ "FlexKomSigStartValue" SG_ 799 IBS_R_Batt "07FFh";
BA_ "GenSigStartValue" SG_ 799 IBS_R_Batt 2047;
BA_ "FlexKomSID" SG_ 799 IBS_R_Batt 1948;
BA_ "FlexKomSigStartPos" SG_ 799 IBS_R_Batt 7;
BA_ "FlexKomSigLaenge" SG_ 799 IBS_R_Batt 16;
BA_ "FlexKomSigName" SG_ 799 IBS_R_Batt "IBS_R_Batt";
BA_ "FlexKomComment" SG_ 799 IBS_R_Batt "Calculated battery resistance";
BA_ "FlexKomIsMotorola" SG_ 799 IBS_R_Batt 1;
BA_ "GenSigSNA" SG_ 799 IBS_R_Batt "7FFh";
BA_ "GenSigCycleTime" SG_ 799 IBS_R_Batt_25 1000;
BA_ "FlexKomSigStartValue" SG_ 799 IBS_R_Batt_25 "07FFh";
BA_ "GenSigStartValue" SG_ 799 IBS_R_Batt_25 2047;
BA_ "FlexKomSID" SG_ 799 IBS_R_Batt_25 1947;
BA_ "FlexKomSigStartPos" SG_ 799 IBS_R_Batt_25 23;
BA_ "FlexKomSigLaenge" SG_ 799 IBS_R_Batt_25 16;
BA_ "FlexKomSigName" SG_ 799 IBS_R_Batt_25 "IBS_R_Batt_25";
BA_ "FlexKomComment" SG_ 799 IBS_R_Batt_25 "Batt resistance at 100% SOC and 25 degC";
BA_ "FlexKomIsMotorola" SG_ 799 IBS_R_Batt_25 1;
BA_ "GenSigSNA" SG_ 799 IBS_R_Batt_25 "7FFh";
BA_ "GenSigSendType" SG_ 799 Trns_DrvMdReq 5;
BA_ "GenSigCycleTime" SG_ 799 Trns_DrvMdReq 1000;
BA_ "FlexKomSigStartValue" SG_ 799 Trns_DrvMdReq "00h";
BA_ "GenSigTimeout_IC" SG_ 799 Trns_DrvMdReq 10500;
BA_ "FlexKomSID" SG_ 799 Trns_DrvMdReq 2081;
BA_ "FlexKomSigStartPos" SG_ 799 Trns_DrvMdReq 42;
BA_ "FlexKomSigLaenge" SG_ 799 Trns_DrvMdReq 3;
BA_ "FlexKomSigName" SG_ 799 Trns_DrvMdReq "Trns_DrvMdReq";
BA_ "FlexKomComment" SG_ 799 Trns_DrvMdReq "The requested state of the drive mode feature";
BA_ "FlexKomIsMotorola" SG_ 799 Trns_DrvMdReq 1;
BA_ "GenSigSNA" SG_ 799 Trns_DrvMdReq "7h";
BA_ "GenSigSendType" SG_ 799 EPS_MODE_REQ 5;
BA_ "GenSigCycleTime" SG_ 799 EPS_MODE_REQ 1000;
BA_ "FlexKomSigStartValue" SG_ 799 EPS_MODE_REQ "00h";
BA_ "GenSigTimeout_IC" SG_ 799 EPS_MODE_REQ 10500;
BA_ "GenSigTimeout_EPS" SG_ 799 EPS_MODE_REQ 10500;
BA_ "FlexKomSID" SG_ 799 EPS_MODE_REQ 2010;
BA_ "FlexKomSigStartPos" SG_ 799 EPS_MODE_REQ 50;
BA_ "FlexKomSigLaenge" SG_ 799 EPS_MODE_REQ 3;
BA_ "FlexKomSigName" SG_ 799 EPS_MODE_REQ "EPS_MODE_REQ";
BA_ "FlexKomComment" SG_ 799 EPS_MODE_REQ "EPS mode personalization request";
BA_ "FlexKomIsMotorola" SG_ 799 EPS_MODE_REQ 1;
BA_ "GenSigSNA" SG_ 799 EPS_MODE_REQ "7h";
BA_ "GenSigSendType" SG_ 799 ADS_MODE_REQ 5;
BA_ "GenSigCycleTime" SG_ 799 ADS_MODE_REQ 1000;
BA_ "FlexKomSigStartValue" SG_ 799 ADS_MODE_REQ "00h";
BA_ "GenSigTimeout_IC" SG_ 799 ADS_MODE_REQ 10500;
BA_ "GenSigTimeout_ADCM" SG_ 799 ADS_MODE_REQ 3500;
BA_ "FlexKomSID" SG_ 799 ADS_MODE_REQ 2011;
BA_ "FlexKomSigStartPos" SG_ 799 ADS_MODE_REQ 53;
BA_ "FlexKomSigLaenge" SG_ 799 ADS_MODE_REQ 3;
BA_ "FlexKomSigName" SG_ 799 ADS_MODE_REQ "ADS_MODE_REQ";
BA_ "FlexKomComment" SG_ 799 ADS_MODE_REQ "Active damping system mode personalization request";
BA_ "FlexKomIsMotorola" SG_ 799 ADS_MODE_REQ 1;
BA_ "GenSigSNA" SG_ 799 ADS_MODE_REQ "7h";
BA_ "GenSigSendType" SG_ 799 PaddlesModeReq 5;
BA_ "GenSigCycleTime" SG_ 799 PaddlesModeReq 1000;
BA_ "FlexKomSigStartValue" SG_ 799 PaddlesModeReq "00h";
BA_ "GenSigTimeout_IC" SG_ 799 PaddlesModeReq 10500;
BA_ "FlexKomSID" SG_ 799 PaddlesModeReq 2080;
BA_ "FlexKomSigStartPos" SG_ 799 PaddlesModeReq 55;
BA_ "FlexKomSigLaenge" SG_ 799 PaddlesModeReq 2;
BA_ "FlexKomSigName" SG_ 799 PaddlesModeReq "PaddlesModeReq";
BA_ "FlexKomComment" SG_ 799 PaddlesModeReq "Requested state of paddle lock-out function";
BA_ "FlexKomIsMotorola" SG_ 799 PaddlesModeReq 1;
BA_ "GenSigSNA" SG_ 799 PaddlesModeReq "3h";
BA_ "GenSigSendType" SG_ 799 ESC_Sft_btn_status 5;
BA_ "GenSigCycleTime" SG_ 799 ESC_Sft_btn_status 1000;
BA_ "FlexKomSigStartValue" SG_ 799 ESC_Sft_btn_status "04h";
BA_ "GenSigStartValue" SG_ 799 ESC_Sft_btn_status 4;
BA_ "GenSigTimeout_IC" SG_ 799 ESC_Sft_btn_status 10500;
BA_ "FlexKomSID" SG_ 799 ESC_Sft_btn_status 2012;
BA_ "FlexKomSigStartPos" SG_ 799 ESC_Sft_btn_status 58;
BA_ "FlexKomSigLaenge" SG_ 799 ESC_Sft_btn_status 3;
BA_ "FlexKomSigName" SG_ 799 ESC_Sft_btn_status "ESC_Sft_btn_status";
BA_ "FlexKomComment" SG_ 799 ESC_Sft_btn_status "ESC mode personalization request";
BA_ "FlexKomIsMotorola" SG_ 799 ESC_Sft_btn_status 1;
BA_ "GenSigSNA" SG_ 799 ESC_Sft_btn_status "7h";
BA_ "GenSigSendType" SG_ 799 RainSensorFailSts 5;
BA_ "GenSigCycleTime" SG_ 799 RainSensorFailSts 1000;
BA_ "FlexKomSigStartValue" SG_ 799 RainSensorFailSts "00h";
BA_ "GenSigTimeout_IC" SG_ 799 RainSensorFailSts 10500;
BA_ "FlexKomSID" SG_ 799 RainSensorFailSts 2046;
BA_ "FlexKomSigStartPos" SG_ 799 RainSensorFailSts 63;
BA_ "FlexKomSigLaenge" SG_ 799 RainSensorFailSts 1;
BA_ "FlexKomSigName" SG_ 799 RainSensorFailSts "RainSensorFailSts";
BA_ "FlexKomComment" SG_ 799 RainSensorFailSts "Fail present = 1";
BA_ "FlexKomIsMotorola" SG_ 799 RainSensorFailSts 1;
BA_ "GenSigSNA" SG_ 799 RainSensorFailSts "0h";
BA_ "GenSigCycleTime" SG_ 800 PSI_Max_RPM 100;
BA_ "FlexKomSigStartValue" SG_ 800 PSI_Max_RPM "00h";
BA_ "GenSigTimeout_ETM" SG_ 800 PSI_Max_RPM 1050;
BA_ "FlexKomSID" SG_ 800 PSI_Max_RPM 2113;
BA_ "FlexKomSigStartPos" SG_ 800 PSI_Max_RPM 7;
BA_ "FlexKomSigLaenge" SG_ 800 PSI_Max_RPM 5;
BA_ "FlexKomSigName" SG_ 800 PSI_Max_RPM "PSI_Max_RPM";
BA_ "FlexKomComment" SG_ 800 PSI_Max_RPM "Maximum selectable RPM for PSI feature";
BA_ "FlexKomIsMotorola" SG_ 800 PSI_Max_RPM 1;
BA_ "GenSigSNA" SG_ 800 PSI_Max_RPM "1Fh";
BA_ "GenSigSendType" SG_ 804 MOOD_LGT_INTS 5;
BA_ "GenSigCycleTime" SG_ 804 MOOD_LGT_INTS 1000;
BA_ "FlexKomSigStartValue" SG_ 804 MOOD_LGT_INTS "00h";
BA_ "GenSigTimeout_IC" SG_ 804 MOOD_LGT_INTS 10500;
BA_ "FlexKomSID" SG_ 804 MOOD_LGT_INTS 959;
BA_ "FlexKomSigStartPos" SG_ 804 MOOD_LGT_INTS 7;
BA_ "FlexKomSigLaenge" SG_ 804 MOOD_LGT_INTS 8;
BA_ "FlexKomSigName" SG_ 804 MOOD_LGT_INTS "MOOD_LGT_INTS";
BA_ "FlexKomComment" SG_ 804 MOOD_LGT_INTS "Mood lighting intensity (ambient & glow rings)";
BA_ "FlexKomIsMotorola" SG_ 804 MOOD_LGT_INTS 1;
BA_ "GenSigSNA" SG_ 804 MOOD_LGT_INTS "FFh";
BA_ "GenSigSendType" SG_ 804 WTS_Active 5;
BA_ "GenSigCycleTime" SG_ 804 WTS_Active 1000;
BA_ "FlexKomSigStartValue" SG_ 804 WTS_Active "00h";
BA_ "GenSigTimeout_RF_HUB" SG_ 804 WTS_Active 10500;
BA_ "FlexKomSID" SG_ 804 WTS_Active 1830;
BA_ "FlexKomSigStartPos" SG_ 804 WTS_Active 9;
BA_ "FlexKomSigLaenge" SG_ 804 WTS_Active 2;
BA_ "FlexKomSigName" SG_ 804 WTS_Active "CBC_WTS_Pkt";
BA_ "FlexKomComment" SG_ 804 WTS_Active "CBC wait to start packet";
BA_ "FlexKomIsMotorola" SG_ 804 WTS_Active 1;
BA_ "GenSigSNA" SG_ 804 WTS_Active "0h";
BA_ "GenSigSendType" SG_ 804 CBC_WTS_AS 5;
BA_ "GenSigCycleTime" SG_ 804 CBC_WTS_AS 1000;
BA_ "FlexKomSigStartValue" SG_ 804 CBC_WTS_AS "00h";
BA_ "GenSigTimeout_IC" SG_ 804 CBC_WTS_AS 10500;
BA_ "FlexKomSID" SG_ 804 CBC_WTS_AS 1830;
BA_ "FlexKomSigStartPos" SG_ 804 CBC_WTS_AS 9;
BA_ "FlexKomSigLaenge" SG_ 804 CBC_WTS_AS 2;
BA_ "FlexKomSigName" SG_ 804 CBC_WTS_AS "CBC_WTS_Pkt";
BA_ "FlexKomComment" SG_ 804 CBC_WTS_AS "CBC wait to start packet";
BA_ "FlexKomIsMotorola" SG_ 804 CBC_WTS_AS 1;
BA_ "GenSigSNA" SG_ 804 CBC_WTS_AS "0h";
BA_ "GenSigSendType" SG_ 804 HdAjar 5;
BA_ "GenSigCycleTime" SG_ 804 HdAjar 1000;
BA_ "FlexKomSigStartValue" SG_ 804 HdAjar "01h";
BA_ "GenSigStartValue" SG_ 804 HdAjar 1;
BA_ "FlexKomSID" SG_ 804 HdAjar 1818;
BA_ "FlexKomSigStartPos" SG_ 804 HdAjar 10;
BA_ "FlexKomSigLaenge" SG_ 804 HdAjar 1;
BA_ "FlexKomSigName" SG_ 804 HdAjar "HdAjar";
BA_ "FlexKomComment" SG_ 804 HdAjar "Hood latch ajar, left or single (1=ajar)";
BA_ "FlexKomIsMotorola" SG_ 804 HdAjar 1;
BA_ "GenSigSNA" SG_ 804 HdAjar "1h";
BA_ "GenSigSendType" SG_ 804 HdAjar_Rt 5;
BA_ "GenSigCycleTime" SG_ 804 HdAjar_Rt 1000;
BA_ "FlexKomSigStartValue" SG_ 804 HdAjar_Rt "01h";
BA_ "GenSigStartValue" SG_ 804 HdAjar_Rt 1;
BA_ "FlexKomSID" SG_ 804 HdAjar_Rt 1817;
BA_ "FlexKomSigStartPos" SG_ 804 HdAjar_Rt 11;
BA_ "FlexKomSigLaenge" SG_ 804 HdAjar_Rt 1;
BA_ "FlexKomSigName" SG_ 804 HdAjar_Rt "HdAjar_Rt";
BA_ "FlexKomComment" SG_ 804 HdAjar_Rt "Hood latch ajar, right (1=ajar)";
BA_ "FlexKomIsMotorola" SG_ 804 HdAjar_Rt 1;
BA_ "GenSigSNA" SG_ 804 HdAjar_Rt "1h";
BA_ "GenSigSendType" SG_ 804 LgtSensInt_Flt 5;
BA_ "GenSigCycleTime" SG_ 804 LgtSensInt_Flt 1000;
BA_ "FlexKomSigStartValue" SG_ 804 LgtSensInt_Flt "00h";
BA_ "GenSigTimeout_IC" SG_ 804 LgtSensInt_Flt 10500;
BA_ "FlexKomSID" SG_ 804 LgtSensInt_Flt 968;
BA_ "FlexKomSigStartPos" SG_ 804 LgtSensInt_Flt 12;
BA_ "FlexKomSigLaenge" SG_ 804 LgtSensInt_Flt 1;
BA_ "FlexKomSigName" SG_ 804 LgtSensInt_Flt "LgtSensInt_Flt";
BA_ "FlexKomComment" SG_ 804 LgtSensInt_Flt "Light sensor internal fault";
BA_ "FlexKomIsMotorola" SG_ 804 LgtSensInt_Flt 1;
BA_ "GenSigSNA" SG_ 804 LgtSensInt_Flt "0h";
BA_ "GenSigSendType" SG_ 804 TurnLmp_FL_Flt 5;
BA_ "GenSigCycleTime" SG_ 804 TurnLmp_FL_Flt 1000;
BA_ "FlexKomSigStartValue" SG_ 804 TurnLmp_FL_Flt "00h";
BA_ "GenSigTimeout_IC" SG_ 804 TurnLmp_FL_Flt 10500;
BA_ "FlexKomSID" SG_ 804 TurnLmp_FL_Flt 973;
BA_ "FlexKomSigStartPos" SG_ 804 TurnLmp_FL_Flt 14;
BA_ "FlexKomSigLaenge" SG_ 804 TurnLmp_FL_Flt 2;
BA_ "FlexKomSigName" SG_ 804 TurnLmp_FL_Flt "TurnLmp_F_Flt";
BA_ "FlexKomComment" SG_ 804 TurnLmp_FL_Flt "Turn indication lamp front fault";
BA_ "FlexKomIsMotorola" SG_ 804 TurnLmp_FL_Flt 1;
BA_ "GenSigSNA" SG_ 804 TurnLmp_FL_Flt "0h";
BA_ "GenSigSendType" SG_ 804 TurnLmp_FR_Flt 5;
BA_ "GenSigCycleTime" SG_ 804 TurnLmp_FR_Flt 1000;
BA_ "FlexKomSigStartValue" SG_ 804 TurnLmp_FR_Flt "00h";
BA_ "GenSigTimeout_IC" SG_ 804 TurnLmp_FR_Flt 10500;
BA_ "FlexKomSID" SG_ 804 TurnLmp_FR_Flt 973;
BA_ "FlexKomSigStartPos" SG_ 804 TurnLmp_FR_Flt 14;
BA_ "FlexKomSigLaenge" SG_ 804 TurnLmp_FR_Flt 2;
BA_ "FlexKomSigName" SG_ 804 TurnLmp_FR_Flt "TurnLmp_F_Flt";
BA_ "FlexKomComment" SG_ 804 TurnLmp_FR_Flt "Turn indication lamp front fault";
BA_ "FlexKomIsMotorola" SG_ 804 TurnLmp_FR_Flt 1;
BA_ "GenSigSNA" SG_ 804 TurnLmp_FR_Flt "0h";
BA_ "GenSigSendType" SG_ 804 BrkPadWearStat 5;
BA_ "GenSigCycleTime" SG_ 804 BrkPadWearStat 1000;
BA_ "FlexKomSigStartValue" SG_ 804 BrkPadWearStat "00h";
BA_ "FlexKomSID" SG_ 804 BrkPadWearStat 1730;
BA_ "FlexKomSigStartPos" SG_ 804 BrkPadWearStat 15;
BA_ "FlexKomSigLaenge" SG_ 804 BrkPadWearStat 1;
BA_ "FlexKomSigName" SG_ 804 BrkPadWearStat "BrkPadWearStat";
BA_ "FlexKomComment" SG_ 804 BrkPadWearStat "Disable fuel shutoff";
BA_ "FlexKomIsMotorola" SG_ 804 BrkPadWearStat 1;
BA_ "GenSigSNA" SG_ 804 BrkPadWearStat "0h";
BA_ "GenSigSendType" SG_ 804 AirSusp_UpSw 5;
BA_ "GenSigCycleTime" SG_ 804 AirSusp_UpSw 1000;
BA_ "FlexKomSigStartValue" SG_ 804 AirSusp_UpSw "00h";
BA_ "FlexKomSID" SG_ 804 AirSusp_UpSw 1464;
BA_ "FlexKomSigStartPos" SG_ 804 AirSusp_UpSw 17;
BA_ "FlexKomSigLaenge" SG_ 804 AirSusp_UpSw 2;
BA_ "FlexKomSigName" SG_ 804 AirSusp_UpSw "AirSusp_UpSw";
BA_ "FlexKomComment" SG_ 804 AirSusp_UpSw "Air suspension up switch status";
BA_ "FlexKomIsMotorola" SG_ 804 AirSusp_UpSw 1;
BA_ "GenSigSNA" SG_ 804 AirSusp_UpSw "3h";
BA_ "GenSigSendType" SG_ 804 AirSusp_DnSw 5;
BA_ "GenSigCycleTime" SG_ 804 AirSusp_DnSw 1000;
BA_ "FlexKomSigStartValue" SG_ 804 AirSusp_DnSw "00h";
BA_ "FlexKomSID" SG_ 804 AirSusp_DnSw 1463;
BA_ "FlexKomSigStartPos" SG_ 804 AirSusp_DnSw 19;
BA_ "FlexKomSigLaenge" SG_ 804 AirSusp_DnSw 2;
BA_ "FlexKomSigName" SG_ 804 AirSusp_DnSw "AirSusp_DnSw";
BA_ "FlexKomComment" SG_ 804 AirSusp_DnSw "Air suspension down switch status";
BA_ "FlexKomIsMotorola" SG_ 804 AirSusp_DnSw 1;
BA_ "GenSigSNA" SG_ 804 AirSusp_DnSw "3h";
BA_ "GenSigSendType" SG_ 804 DAY_LGT_Act 5;
BA_ "GenSigCycleTime" SG_ 804 DAY_LGT_Act 1000;
BA_ "FlexKomSigStartValue" SG_ 804 DAY_LGT_Act "00h";
BA_ "GenSigTimeout_AFLS" SG_ 804 DAY_LGT_Act 10500;
BA_ "FlexKomSID" SG_ 804 DAY_LGT_Act 1801;
BA_ "FlexKomSigStartPos" SG_ 804 DAY_LGT_Act 20;
BA_ "FlexKomSigLaenge" SG_ 804 DAY_LGT_Act 1;
BA_ "FlexKomSigName" SG_ 804 DAY_LGT_Act "DAY_LGT_Act";
BA_ "FlexKomComment" SG_ 804 DAY_LGT_Act "Day light actual (based on light sensor input)";
BA_ "FlexKomIsMotorola" SG_ 804 DAY_LGT_Act 1;
BA_ "GenSigSNA" SG_ 804 DAY_LGT_Act "0h";
BA_ "GenSigSendType" SG_ 804 ExteriorRearReleaseSwitchSts 5;
BA_ "GenSigCycleTime" SG_ 804 ExteriorRearReleaseSwitchSts 1000;
BA_ "FlexKomSigStartValue" SG_ 804 ExteriorRearReleaseSwitchSts "00h";
BA_ "GenSigTimeout_RF_HUB" SG_ 804 ExteriorRearReleaseSwitchSts 10500;
BA_ "FlexKomSID" SG_ 804 ExteriorRearReleaseSwitchSts 1846;
BA_ "FlexKomSigStartPos" SG_ 804 ExteriorRearReleaseSwitchSts 21;
BA_ "FlexKomSigLaenge" SG_ 804 ExteriorRearReleaseSwitchSts 1;
BA_ "FlexKomSigName" SG_ 804 ExteriorRearReleaseSwitchSts "ExteriorRearReleaseSwitchSts";
BA_ "FlexKomComment" SG_ 804 ExteriorRearReleaseSwitchSts "Exterior rear release switch status";
BA_ "FlexKomIsMotorola" SG_ 804 ExteriorRearReleaseSwitchSts 1;
BA_ "GenSigSNA" SG_ 804 ExteriorRearReleaseSwitchSts "0h";
BA_ "GenSigSendType" SG_ 804 SpStSwPsd 5;
BA_ "GenSigCycleTime" SG_ 804 SpStSwPsd 1000;
BA_ "FlexKomSigStartValue" SG_ 804 SpStSwPsd "00h";
BA_ "FlexKomSID" SG_ 804 SpStSwPsd 1584;
BA_ "FlexKomSigStartPos" SG_ 804 SpStSwPsd 23;
BA_ "FlexKomSigLaenge" SG_ 804 SpStSwPsd 2;
BA_ "FlexKomSigName" SG_ 804 SpStSwPsd "SpStSwPsd";
BA_ "FlexKomComment" SG_ 804 SpStSwPsd "Stop start switch pressed";
BA_ "FlexKomIsMotorola" SG_ 804 SpStSwPsd 1;
BA_ "GenSigSNA" SG_ 804 SpStSwPsd "3h";
BA_ "GenSigSendType" SG_ 804 TurnLmp_RL_Flt 5;
BA_ "GenSigCycleTime" SG_ 804 TurnLmp_RL_Flt 1000;
BA_ "FlexKomSigStartValue" SG_ 804 TurnLmp_RL_Flt "00h";
BA_ "GenSigTimeout_IC" SG_ 804 TurnLmp_RL_Flt 10500;
BA_ "FlexKomSID" SG_ 804 TurnLmp_RL_Flt 1033;
BA_ "FlexKomSigStartPos" SG_ 804 TurnLmp_RL_Flt 25;
BA_ "FlexKomSigLaenge" SG_ 804 TurnLmp_RL_Flt 2;
BA_ "FlexKomSigName" SG_ 804 TurnLmp_RL_Flt "TurnLmp_R_Flt";
BA_ "FlexKomComment" SG_ 804 TurnLmp_RL_Flt "Turn indication lamp rear fault";
BA_ "FlexKomIsMotorola" SG_ 804 TurnLmp_RL_Flt 1;
BA_ "GenSigSNA" SG_ 804 TurnLmp_RL_Flt "0h";
BA_ "GenSigSendType" SG_ 804 TurnLmp_RR_Flt 5;
BA_ "GenSigCycleTime" SG_ 804 TurnLmp_RR_Flt 1000;
BA_ "FlexKomSigStartValue" SG_ 804 TurnLmp_RR_Flt "00h";
BA_ "GenSigTimeout_IC" SG_ 804 TurnLmp_RR_Flt 10500;
BA_ "FlexKomSID" SG_ 804 TurnLmp_RR_Flt 1033;
BA_ "FlexKomSigStartPos" SG_ 804 TurnLmp_RR_Flt 25;
BA_ "FlexKomSigLaenge" SG_ 804 TurnLmp_RR_Flt 2;
BA_ "FlexKomSigName" SG_ 804 TurnLmp_RR_Flt "TurnLmp_R_Flt";
BA_ "FlexKomComment" SG_ 804 TurnLmp_RR_Flt "Turn indication lamp rear fault";
BA_ "FlexKomIsMotorola" SG_ 804 TurnLmp_RR_Flt 1;
BA_ "GenSigSNA" SG_ 804 TurnLmp_RR_Flt "0h";
BA_ "GenSigSendType" SG_ 804 ACC_DLY_ACT 5;
BA_ "GenSigCycleTime" SG_ 804 ACC_DLY_ACT 1000;
BA_ "FlexKomSigStartValue" SG_ 804 ACC_DLY_ACT "00h";
BA_ "GenSigTimeout_IC" SG_ 804 ACC_DLY_ACT 10500;
BA_ "GenSigTimeout_SCCM" SG_ 804 ACC_DLY_ACT 10500;
BA_ "FlexKomSID" SG_ 804 ACC_DLY_ACT 841;
BA_ "FlexKomSigStartPos" SG_ 804 ACC_DLY_ACT 26;
BA_ "FlexKomSigLaenge" SG_ 804 ACC_DLY_ACT 1;
BA_ "FlexKomSigName" SG_ 804 ACC_DLY_ACT "ACC_DLY_ACT";
BA_ "FlexKomComment" SG_ 804 ACC_DLY_ACT "Accessory Delay Active";
BA_ "FlexKomIsMotorola" SG_ 804 ACC_DLY_ACT 1;
BA_ "GenSigSNA" SG_ 804 ACC_DLY_ACT "0h";
BA_ "GenSigSendType" SG_ 804 CargoLampOn 5;
BA_ "GenSigCycleTime" SG_ 804 CargoLampOn 1000;
BA_ "FlexKomSigStartValue" SG_ 804 CargoLampOn "00h";
BA_ "GenSigTimeout_IC" SG_ 804 CargoLampOn 10500;
BA_ "FlexKomSID" SG_ 804 CargoLampOn 1898;
BA_ "FlexKomSigStartPos" SG_ 804 CargoLampOn 27;
BA_ "FlexKomSigLaenge" SG_ 804 CargoLampOn 1;
BA_ "FlexKomSigName" SG_ 804 CargoLampOn "CargoLampOn";
BA_ "FlexKomComment" SG_ 804 CargoLampOn "Cargo lamp is on";
BA_ "FlexKomIsMotorola" SG_ 804 CargoLampOn 1;
BA_ "GenSigSNA" SG_ 804 CargoLampOn "0h";
BA_ "GenSigSendType" SG_ 804 HL_SW_Position 5;
BA_ "GenSigCycleTime" SG_ 804 HL_SW_Position 1000;
BA_ "FlexKomSigStartValue" SG_ 804 HL_SW_Position "00h";
BA_ "FlexKomSID" SG_ 804 HL_SW_Position 1897;
BA_ "FlexKomSigStartPos" SG_ 804 HL_SW_Position 29;
BA_ "FlexKomSigLaenge" SG_ 804 HL_SW_Position 2;
BA_ "FlexKomSigName" SG_ 804 HL_SW_Position "HL_SW_Position";
BA_ "FlexKomComment" SG_ 804 HL_SW_Position "Actual headlamp switch position";
BA_ "FlexKomIsMotorola" SG_ 804 HL_SW_Position 1;
BA_ "GenSigSNA" SG_ 804 HL_SW_Position "0h";
BA_ "GenSigSendType" SG_ 804 ML_HDLP_LVL 5;
BA_ "GenSigCycleTime" SG_ 804 ML_HDLP_LVL 1000;
BA_ "FlexKomSigStartValue" SG_ 804 ML_HDLP_LVL "00h";
BA_ "FlexKomSID" SG_ 804 ML_HDLP_LVL 1873;
BA_ "FlexKomSigStartPos" SG_ 804 ML_HDLP_LVL 31;
BA_ "FlexKomSigLaenge" SG_ 804 ML_HDLP_LVL 2;
BA_ "FlexKomSigName" SG_ 804 ML_HDLP_LVL "ML_HDLP_LVL";
BA_ "FlexKomComment" SG_ 804 ML_HDLP_LVL "Manual headlamp leveling";
BA_ "FlexKomIsMotorola" SG_ 804 ML_HDLP_LVL 1;
BA_ "GenSigSNA" SG_ 804 ML_HDLP_LVL "0h";
BA_ "GenSigSendType" SG_ 804 RemSt_Inhibit 5;
BA_ "GenSigCycleTime" SG_ 804 RemSt_Inhibit 1000;
BA_ "FlexKomSigStartValue" SG_ 804 RemSt_Inhibit "00h";
BA_ "GenSigTimeout_IC" SG_ 804 RemSt_Inhibit 10500;
BA_ "GenSigTimeout_ETM" SG_ 804 RemSt_Inhibit 10500;
BA_ "FlexKomSID" SG_ 804 RemSt_Inhibit 1047;
BA_ "FlexKomSigStartPos" SG_ 804 RemSt_Inhibit 39;
BA_ "FlexKomSigLaenge" SG_ 804 RemSt_Inhibit 8;
BA_ "FlexKomSigName" SG_ 804 RemSt_Inhibit "RemSt_Inhibit";
BA_ "FlexKomComment" SG_ 804 RemSt_Inhibit "Remote start inhibit";
BA_ "FlexKomIsMotorola" SG_ 804 RemSt_Inhibit 1;
BA_ "GenSigSNA" SG_ 804 RemSt_Inhibit "FFh";
BA_ "GenSigCycleTime" SG_ 804 WPR_SYS_OFF 1000;
BA_ "FlexKomSigStartValue" SG_ 804 WPR_SYS_OFF "01h";
BA_ "GenSigStartValue" SG_ 804 WPR_SYS_OFF 1;
BA_ "FlexKomSID" SG_ 804 WPR_SYS_OFF 1048;
BA_ "FlexKomSigStartPos" SG_ 804 WPR_SYS_OFF 47;
BA_ "FlexKomSigLaenge" SG_ 804 WPR_SYS_OFF 8;
BA_ "FlexKomSigName" SG_ 804 WPR_SYS_OFF "WPR_SYS_STAT";
BA_ "FlexKomComment" SG_ 804 WPR_SYS_OFF "Wiper System Status";
BA_ "FlexKomIsMotorola" SG_ 804 WPR_SYS_OFF 1;
BA_ "GenSigSNA" SG_ 804 WPR_SYS_OFF "1h";
BA_ "GenSigCycleTime" SG_ 804 WPR_SYS_LOW 1000;
BA_ "FlexKomSigStartValue" SG_ 804 WPR_SYS_LOW "01h";
BA_ "FlexKomSID" SG_ 804 WPR_SYS_LOW 1048;
BA_ "FlexKomSigStartPos" SG_ 804 WPR_SYS_LOW 47;
BA_ "FlexKomSigLaenge" SG_ 804 WPR_SYS_LOW 8;
BA_ "FlexKomSigName" SG_ 804 WPR_SYS_LOW "WPR_SYS_STAT";
BA_ "FlexKomComment" SG_ 804 WPR_SYS_LOW "Wiper System Status";
BA_ "FlexKomIsMotorola" SG_ 804 WPR_SYS_LOW 1;
BA_ "GenSigSNA" SG_ 804 WPR_SYS_LOW "0h";
BA_ "GenSigCycleTime" SG_ 804 WPR_SYS_HIGH 1000;
BA_ "FlexKomSigStartValue" SG_ 804 WPR_SYS_HIGH "01h";
BA_ "FlexKomSID" SG_ 804 WPR_SYS_HIGH 1048;
BA_ "FlexKomSigStartPos" SG_ 804 WPR_SYS_HIGH 47;
BA_ "FlexKomSigLaenge" SG_ 804 WPR_SYS_HIGH 8;
BA_ "FlexKomSigName" SG_ 804 WPR_SYS_HIGH "WPR_SYS_STAT";
BA_ "FlexKomComment" SG_ 804 WPR_SYS_HIGH "Wiper System Status";
BA_ "FlexKomIsMotorola" SG_ 804 WPR_SYS_HIGH 1;
BA_ "GenSigSNA" SG_ 804 WPR_SYS_HIGH "0h";
BA_ "GenSigCycleTime" SG_ 804 WPR_SYS_INT 1000;
BA_ "FlexKomSigStartValue" SG_ 804 WPR_SYS_INT "01h";
BA_ "FlexKomSID" SG_ 804 WPR_SYS_INT 1048;
BA_ "FlexKomSigStartPos" SG_ 804 WPR_SYS_INT 47;
BA_ "FlexKomSigLaenge" SG_ 804 WPR_SYS_INT 8;
BA_ "FlexKomSigName" SG_ 804 WPR_SYS_INT "WPR_SYS_STAT";
BA_ "FlexKomComment" SG_ 804 WPR_SYS_INT "Wiper System Status";
BA_ "FlexKomIsMotorola" SG_ 804 WPR_SYS_INT 1;
BA_ "GenSigSNA" SG_ 804 WPR_SYS_INT "0h";
BA_ "GenSigCycleTime" SG_ 804 WPR_SYS_AUTO 1000;
BA_ "FlexKomSigStartValue" SG_ 804 WPR_SYS_AUTO "01h";
BA_ "FlexKomSID" SG_ 804 WPR_SYS_AUTO 1048;
BA_ "FlexKomSigStartPos" SG_ 804 WPR_SYS_AUTO 47;
BA_ "FlexKomSigLaenge" SG_ 804 WPR_SYS_AUTO 8;
BA_ "FlexKomSigName" SG_ 804 WPR_SYS_AUTO "WPR_SYS_STAT";
BA_ "FlexKomComment" SG_ 804 WPR_SYS_AUTO "Wiper System Status";
BA_ "FlexKomIsMotorola" SG_ 804 WPR_SYS_AUTO 1;
BA_ "GenSigSNA" SG_ 804 WPR_SYS_AUTO "0h";
BA_ "GenSigCycleTime" SG_ 804 WPR_SYS_MIST 1000;
BA_ "FlexKomSigStartValue" SG_ 804 WPR_SYS_MIST "01h";
BA_ "FlexKomSID" SG_ 804 WPR_SYS_MIST 1048;
BA_ "FlexKomSigStartPos" SG_ 804 WPR_SYS_MIST 47;
BA_ "FlexKomSigLaenge" SG_ 804 WPR_SYS_MIST 8;
BA_ "FlexKomSigName" SG_ 804 WPR_SYS_MIST "WPR_SYS_STAT";
BA_ "FlexKomComment" SG_ 804 WPR_SYS_MIST "Wiper System Status";
BA_ "FlexKomIsMotorola" SG_ 804 WPR_SYS_MIST 1;
BA_ "GenSigSNA" SG_ 804 WPR_SYS_MIST "0h";
BA_ "GenSigCycleTime" SG_ 804 WPR_SYS_WASH 1000;
BA_ "FlexKomSigStartValue" SG_ 804 WPR_SYS_WASH "01h";
BA_ "FlexKomSID" SG_ 804 WPR_SYS_WASH 1048;
BA_ "FlexKomSigStartPos" SG_ 804 WPR_SYS_WASH 47;
BA_ "FlexKomSigLaenge" SG_ 804 WPR_SYS_WASH 8;
BA_ "FlexKomSigName" SG_ 804 WPR_SYS_WASH "WPR_SYS_STAT";
BA_ "FlexKomComment" SG_ 804 WPR_SYS_WASH "Wiper System Status";
BA_ "FlexKomIsMotorola" SG_ 804 WPR_SYS_WASH 1;
BA_ "GenSigSNA" SG_ 804 WPR_SYS_WASH "0h";
BA_ "GenSigCycleTime" SG_ 804 WPR_SYS_FLT 1000;
BA_ "FlexKomSigStartValue" SG_ 804 WPR_SYS_FLT "01h";
BA_ "FlexKomSID" SG_ 804 WPR_SYS_FLT 1048;
BA_ "FlexKomSigStartPos" SG_ 804 WPR_SYS_FLT 47;
BA_ "FlexKomSigLaenge" SG_ 804 WPR_SYS_FLT 8;
BA_ "FlexKomSigName" SG_ 804 WPR_SYS_FLT "WPR_SYS_STAT";
BA_ "FlexKomComment" SG_ 804 WPR_SYS_FLT "Wiper System Status";
BA_ "FlexKomIsMotorola" SG_ 804 WPR_SYS_FLT 1;
BA_ "GenSigSNA" SG_ 804 WPR_SYS_FLT "0h";
BA_ "GenSigSendType" SG_ 804 Court_Lmp 5;
BA_ "GenSigCycleTime" SG_ 804 Court_Lmp 1000;
BA_ "FlexKomSigStartValue" SG_ 804 Court_Lmp "00h";
BA_ "GenSigTimeout_RF_HUB" SG_ 804 Court_Lmp 10500;
BA_ "FlexKomSID" SG_ 804 Court_Lmp 1367;
BA_ "FlexKomSigStartPos" SG_ 804 Court_Lmp 55;
BA_ "FlexKomSigLaenge" SG_ 804 Court_Lmp 8;
BA_ "FlexKomSigName" SG_ 804 Court_Lmp "Court_Lmp";
BA_ "FlexKomComment" SG_ 804 Court_Lmp "Courtesy lamp percentage";
BA_ "FlexKomIsMotorola" SG_ 804 Court_Lmp 1;
BA_ "GenSigSNA" SG_ 804 Court_Lmp "FFh";
BA_ "GenSigSendType" SG_ 804 DriveStyleSts 5;
BA_ "GenSigCycleTime" SG_ 804 DriveStyleSts 1000;
BA_ "FlexKomSigStartValue" SG_ 804 DriveStyleSts "00h";
BA_ "GenSigTimeout_IC" SG_ 804 DriveStyleSts 10500;
BA_ "FlexKomSID" SG_ 804 DriveStyleSts 1516;
BA_ "FlexKomSigStartPos" SG_ 804 DriveStyleSts 58;
BA_ "FlexKomSigLaenge" SG_ 804 DriveStyleSts 3;
BA_ "FlexKomSigName" SG_ 804 DriveStyleSts "DriveStyleSts";
BA_ "FlexKomComment" SG_ 804 DriveStyleSts "Drive style status";
BA_ "FlexKomIsMotorola" SG_ 804 DriveStyleSts 1;
BA_ "GenSigSNA" SG_ 804 DriveStyleSts "7h";
BA_ "GenSigSendType" SG_ 804 DrvMdRq 5;
BA_ "GenSigCycleTime" SG_ 804 DrvMdRq 1000;
BA_ "FlexKomSigStartValue" SG_ 804 DrvMdRq "00h";
BA_ "GenSigTimeout_ADCM" SG_ 804 DrvMdRq 25500;
BA_ "GenSigTimeout_ORC" SG_ 804 DrvMdRq 3500;
BA_ "FlexKomSID" SG_ 804 DrvMdRq 1515;
BA_ "FlexKomSigStartPos" SG_ 804 DrvMdRq 61;
BA_ "FlexKomSigLaenge" SG_ 804 DrvMdRq 3;
BA_ "FlexKomSigName" SG_ 804 DrvMdRq "DrvMdRq";
BA_ "FlexKomComment" SG_ 804 DrvMdRq "Drive mode request";
BA_ "FlexKomIsMotorola" SG_ 804 DrvMdRq 1;
BA_ "GenSigSNA" SG_ 804 DrvMdRq "7h";
BA_ "GenSigSendType" SG_ 804 ManMdRq 5;
BA_ "GenSigCycleTime" SG_ 804 ManMdRq 1000;
BA_ "FlexKomSigStartValue" SG_ 804 ManMdRq "00h";
BA_ "FlexKomSID" SG_ 804 ManMdRq 1771;
BA_ "FlexKomSigStartPos" SG_ 804 ManMdRq 63;
BA_ "FlexKomSigLaenge" SG_ 804 ManMdRq 2;
BA_ "FlexKomSigName" SG_ 804 ManMdRq "ManMdRq";
BA_ "FlexKomComment" SG_ 804 ManMdRq "Manual shift mode request switch status";
BA_ "FlexKomIsMotorola" SG_ 804 ManMdRq 1;
BA_ "GenSigSNA" SG_ 804 ManMdRq "3h";
BA_ "GenSigSendType" SG_ 806 AFLS_ENBL 5;
BA_ "GenSigCycleTime" SG_ 806 AFLS_ENBL 1000;
BA_ "FlexKomSigStartValue" SG_ 806 AFLS_ENBL "00h";
BA_ "GenSigTimeout_IC" SG_ 806 AFLS_ENBL 10500;
BA_ "FlexKomSID" SG_ 806 AFLS_ENBL 1032;
BA_ "FlexKomSigLaenge" SG_ 806 AFLS_ENBL 1;
BA_ "FlexKomSigName" SG_ 806 AFLS_ENBL "AFLS_ENBL";
BA_ "FlexKomComment" SG_ 806 AFLS_ENBL "Advanced lighting enabled; [0] = no, [1] = yes";
BA_ "FlexKomIsMotorola" SG_ 806 AFLS_ENBL 1;
BA_ "GenSigSNA" SG_ 806 AFLS_ENBL "0h";
BA_ "GenSigSendType" SG_ 806 AFLS_Stat 5;
BA_ "GenSigCycleTime" SG_ 806 AFLS_Stat 1000;
BA_ "FlexKomSigStartValue" SG_ 806 AFLS_Stat "00h";
BA_ "GenSigTimeout_IC" SG_ 806 AFLS_Stat 10500;
BA_ "FlexKomSID" SG_ 806 AFLS_Stat 1318;
BA_ "FlexKomSigStartPos" SG_ 806 AFLS_Stat 2;
BA_ "FlexKomSigLaenge" SG_ 806 AFLS_Stat 2;
BA_ "FlexKomSigName" SG_ 806 AFLS_Stat "AFLS_Stat";
BA_ "FlexKomComment" SG_ 806 AFLS_Stat "AFLS fault status";
BA_ "FlexKomIsMotorola" SG_ 806 AFLS_Stat 1;
BA_ "GenSigSNA" SG_ 806 AFLS_Stat "0h";
BA_ "GenSigSendType" SG_ 806 HLDrpStat 5;
BA_ "GenSigCycleTime" SG_ 806 HLDrpStat 1000;
BA_ "FlexKomSigStartValue" SG_ 806 HLDrpStat "00h";
BA_ "GenSigTimeout_CBC" SG_ 806 HLDrpStat 10500;
BA_ "GenSigTimeout_IC" SG_ 806 HLDrpStat 10500;
BA_ "FlexKomSID" SG_ 806 HLDrpStat 1400;
BA_ "FlexKomSigStartPos" SG_ 806 HLDrpStat 4;
BA_ "FlexKomSigLaenge" SG_ 806 HLDrpStat 2;
BA_ "FlexKomSigName" SG_ 806 HLDrpStat "HLDrpStat";
BA_ "FlexKomComment" SG_ 806 HLDrpStat "Headlamp drop status";
BA_ "FlexKomIsMotorola" SG_ 806 HLDrpStat 1;
BA_ "GenSigSNA" SG_ 806 HLDrpStat "3h";
BA_ "GenSigSendType" SG_ 806 ExtdLgtStat 5;
BA_ "GenSigCycleTime" SG_ 806 ExtdLgtStat 1000;
BA_ "FlexKomSigStartValue" SG_ 806 ExtdLgtStat "00h";
BA_ "FlexKomSID" SG_ 806 ExtdLgtStat 1564;
BA_ "FlexKomSigStartPos" SG_ 806 ExtdLgtStat 6;
BA_ "FlexKomSigLaenge" SG_ 806 ExtdLgtStat 2;
BA_ "FlexKomSigName" SG_ 806 ExtdLgtStat "ExtdLgtStat";
BA_ "FlexKomComment" SG_ 806 ExtdLgtStat "Extended lighting status";
BA_ "FlexKomIsMotorola" SG_ 806 ExtdLgtStat 1;
BA_ "GenSigSNA" SG_ 806 ExtdLgtStat "3h";
BA_ "GenSigSendType" SG_ 806 HighBeamFault_AFLS 5;
BA_ "GenSigCycleTime" SG_ 806 HighBeamFault_AFLS 1000;
BA_ "FlexKomSigStartValue" SG_ 806 HighBeamFault_AFLS "00h";
BA_ "FlexKomSID" SG_ 806 HighBeamFault_AFLS 1940;
BA_ "FlexKomSigStartPos" SG_ 806 HighBeamFault_AFLS 7;
BA_ "FlexKomSigLaenge" SG_ 806 HighBeamFault_AFLS 1;
BA_ "FlexKomSigName" SG_ 806 HighBeamFault_AFLS "HighBeamFault_AFLS";
BA_ "FlexKomComment" SG_ 806 HighBeamFault_AFLS "High Beam or Shutter Fault; 1 = High beam fault pr";
BA_ "FlexKomIsMotorola" SG_ 806 HighBeamFault_AFLS 1;
BA_ "GenSigSNA" SG_ 806 HighBeamFault_AFLS "0h";
BA_ "GenSigSendType" SG_ 808 TGW_GrpNum_IC 5;
BA_ "GenSigCycleTime" SG_ 808 TGW_GrpNum_IC 1000;
BA_ "FlexKomSigStartValue" SG_ 808 TGW_GrpNum_IC "0000000000000000h";
BA_ "FlexKomSID" SG_ 808 TGW_GrpNum_IC 985;
BA_ "FlexKomSigStartPos" SG_ 808 TGW_GrpNum_IC 7;
BA_ "FlexKomSigLaenge" SG_ 808 TGW_GrpNum_IC 64;
BA_ "FlexKomSigName" SG_ 808 TGW_GrpNum_IC "TGW_DATA_IC";
BA_ "FlexKomComment" SG_ 808 TGW_GrpNum_IC "TGW text data transfer to IC";
BA_ "FlexKomIsMotorola" SG_ 808 TGW_GrpNum_IC 1;
BA_ "GenSigSNA" SG_ 808 TGW_GrpNum_IC "0h";
BA_ "GenSigSendType" SG_ 808 TGW_GrpTyp_IC 5;
BA_ "GenSigCycleTime" SG_ 808 TGW_GrpTyp_IC 1000;
BA_ "FlexKomSigStartValue" SG_ 808 TGW_GrpTyp_IC "0000000000000000h";
BA_ "FlexKomSID" SG_ 808 TGW_GrpTyp_IC 985;
BA_ "FlexKomSigStartPos" SG_ 808 TGW_GrpTyp_IC 7;
BA_ "FlexKomSigLaenge" SG_ 808 TGW_GrpTyp_IC 64;
BA_ "FlexKomSigName" SG_ 808 TGW_GrpTyp_IC "TGW_DATA_IC";
BA_ "FlexKomComment" SG_ 808 TGW_GrpTyp_IC "TGW text data transfer to IC";
BA_ "FlexKomIsMotorola" SG_ 808 TGW_GrpTyp_IC 1;
BA_ "GenSigSNA" SG_ 808 TGW_GrpTyp_IC "3Fh";
BA_ "GenSigSendType" SG_ 808 TGW_HiGrpMark_IC 5;
BA_ "GenSigCycleTime" SG_ 808 TGW_HiGrpMark_IC 1000;
BA_ "FlexKomSigStartValue" SG_ 808 TGW_HiGrpMark_IC "0000000000000000h";
BA_ "FlexKomSID" SG_ 808 TGW_HiGrpMark_IC 985;
BA_ "FlexKomSigStartPos" SG_ 808 TGW_HiGrpMark_IC 7;
BA_ "FlexKomSigLaenge" SG_ 808 TGW_HiGrpMark_IC 64;
BA_ "FlexKomSigName" SG_ 808 TGW_HiGrpMark_IC "TGW_DATA_IC";
BA_ "FlexKomComment" SG_ 808 TGW_HiGrpMark_IC "TGW text data transfer to IC";
BA_ "FlexKomIsMotorola" SG_ 808 TGW_HiGrpMark_IC 1;
BA_ "GenSigSNA" SG_ 808 TGW_HiGrpMark_IC "0h";
BA_ "GenSigSendType" SG_ 808 TGW_TEXT_IC 5;
BA_ "GenSigCycleTime" SG_ 808 TGW_TEXT_IC 1000;
BA_ "FlexKomSigStartValue" SG_ 808 TGW_TEXT_IC "0000000000000000h";
BA_ "FlexKomSID" SG_ 808 TGW_TEXT_IC 985;
BA_ "FlexKomSigStartPos" SG_ 808 TGW_TEXT_IC 7;
BA_ "FlexKomSigLaenge" SG_ 808 TGW_TEXT_IC 64;
BA_ "FlexKomSigName" SG_ 808 TGW_TEXT_IC "TGW_DATA_IC";
BA_ "FlexKomComment" SG_ 808 TGW_TEXT_IC "TGW text data transfer to IC";
BA_ "FlexKomIsMotorola" SG_ 808 TGW_TEXT_IC 1;
BA_ "GenSigSNA" SG_ 808 TGW_TEXT_IC "0h";
BA_ "GenSigCycleTime" SG_ 810 PTO_Md 100;
BA_ "FlexKomSigStartValue" SG_ 810 PTO_Md "00000000000000h";
BA_ "GenSigTimeout_CBC" SG_ 810 PTO_Md 1050;
BA_ "GenSigTimeout_IC" SG_ 810 PTO_Md 1050;
BA_ "FlexKomSID" SG_ 810 PTO_Md 1761;
BA_ "FlexKomSigStartPos" SG_ 810 PTO_Md 7;
BA_ "FlexKomSigLaenge" SG_ 810 PTO_Md 56;
BA_ "FlexKomSigName" SG_ 810 PTO_Md "PTO_PKT";
BA_ "FlexKomComment" SG_ 810 PTO_Md "Power takeoff status packet";
BA_ "FlexKomIsMotorola" SG_ 810 PTO_Md 1;
BA_ "GenSigSNA" SG_ 810 PTO_Md "7h";
BA_ "GenSigCycleTime" SG_ 810 PTO_MaxVehSpd 100;
BA_ "FlexKomSigStartValue" SG_ 810 PTO_MaxVehSpd "00000000000000h";
BA_ "GenSigTimeout_CBC" SG_ 810 PTO_MaxVehSpd 1050;
BA_ "GenSigTimeout_IC" SG_ 810 PTO_MaxVehSpd 1050;
BA_ "FlexKomSID" SG_ 810 PTO_MaxVehSpd 1761;
BA_ "FlexKomSigStartPos" SG_ 810 PTO_MaxVehSpd 7;
BA_ "FlexKomSigLaenge" SG_ 810 PTO_MaxVehSpd 56;
BA_ "FlexKomSigName" SG_ 810 PTO_MaxVehSpd "PTO_PKT";
BA_ "FlexKomComment" SG_ 810 PTO_MaxVehSpd "Power takeoff status packet";
BA_ "FlexKomIsMotorola" SG_ 810 PTO_MaxVehSpd 1;
BA_ "GenSigSNA" SG_ 810 PTO_MaxVehSpd "1Fh";
BA_ "GenSigCycleTime" SG_ 810 PTO_AutoRsm 100;
BA_ "FlexKomSigStartValue" SG_ 810 PTO_AutoRsm "00000000000000h";
BA_ "GenSigTimeout_CBC" SG_ 810 PTO_AutoRsm 1050;
BA_ "GenSigTimeout_IC" SG_ 810 PTO_AutoRsm 1050;
BA_ "FlexKomSID" SG_ 810 PTO_AutoRsm 1761;
BA_ "FlexKomSigStartPos" SG_ 810 PTO_AutoRsm 7;
BA_ "FlexKomSigLaenge" SG_ 810 PTO_AutoRsm 56;
BA_ "FlexKomSigName" SG_ 810 PTO_AutoRsm "PTO_PKT";
BA_ "FlexKomComment" SG_ 810 PTO_AutoRsm "Power takeoff status packet";
BA_ "FlexKomIsMotorola" SG_ 810 PTO_AutoRsm 1;
BA_ "GenSigSNA" SG_ 810 PTO_AutoRsm "0h";
BA_ "GenSigCycleTime" SG_ 810 PTO_TYPES 100;
BA_ "FlexKomSigStartValue" SG_ 810 PTO_TYPES "00000000000000h";
BA_ "GenSigTimeout_CBC" SG_ 810 PTO_TYPES 1050;
BA_ "GenSigTimeout_IC" SG_ 810 PTO_TYPES 1050;
BA_ "FlexKomSID" SG_ 810 PTO_TYPES 1761;
BA_ "FlexKomSigStartPos" SG_ 810 PTO_TYPES 7;
BA_ "FlexKomSigLaenge" SG_ 810 PTO_TYPES 56;
BA_ "FlexKomSigName" SG_ 810 PTO_TYPES "PTO_PKT";
BA_ "FlexKomComment" SG_ 810 PTO_TYPES "Power takeoff status packet";
BA_ "FlexKomIsMotorola" SG_ 810 PTO_TYPES 1;
BA_ "GenSigSNA" SG_ 810 PTO_TYPES "3h";
BA_ "GenSigCycleTime" SG_ 810 PTO_ENGD_RQ 100;
BA_ "FlexKomSigStartValue" SG_ 810 PTO_ENGD_RQ "00000000000000h";
BA_ "GenSigTimeout_IC" SG_ 810 PTO_ENGD_RQ 1050;
BA_ "FlexKomSID" SG_ 810 PTO_ENGD_RQ 1761;
BA_ "FlexKomSigStartPos" SG_ 810 PTO_ENGD_RQ 7;
BA_ "FlexKomSigLaenge" SG_ 810 PTO_ENGD_RQ 56;
BA_ "FlexKomSigName" SG_ 810 PTO_ENGD_RQ "PTO_PKT";
BA_ "FlexKomComment" SG_ 810 PTO_ENGD_RQ "Power takeoff status packet";
BA_ "FlexKomIsMotorola" SG_ 810 PTO_ENGD_RQ 1;
BA_ "GenSigSNA" SG_ 810 PTO_ENGD_RQ "0h";
BA_ "GenSigCycleTime" SG_ 810 PTO_Incab 100;
BA_ "FlexKomSigStartValue" SG_ 810 PTO_Incab "00000000000000h";
BA_ "GenSigTimeout_IC" SG_ 810 PTO_Incab 1050;
BA_ "FlexKomSID" SG_ 810 PTO_Incab 1761;
BA_ "FlexKomSigStartPos" SG_ 810 PTO_Incab 7;
BA_ "FlexKomSigLaenge" SG_ 810 PTO_Incab 56;
BA_ "FlexKomSigName" SG_ 810 PTO_Incab "PTO_PKT";
BA_ "FlexKomComment" SG_ 810 PTO_Incab "Power takeoff status packet";
BA_ "FlexKomIsMotorola" SG_ 810 PTO_Incab 1;
BA_ "GenSigSNA" SG_ 810 PTO_Incab "0h";
BA_ "GenSigCycleTime" SG_ 810 PTO_HornRq 100;
BA_ "FlexKomSigStartValue" SG_ 810 PTO_HornRq "00000000000000h";
BA_ "FlexKomSID" SG_ 810 PTO_HornRq 1761;
BA_ "FlexKomSigStartPos" SG_ 810 PTO_HornRq 7;
BA_ "FlexKomSigLaenge" SG_ 810 PTO_HornRq 56;
BA_ "FlexKomSigName" SG_ 810 PTO_HornRq "PTO_PKT";
BA_ "FlexKomComment" SG_ 810 PTO_HornRq "Power takeoff status packet";
BA_ "FlexKomIsMotorola" SG_ 810 PTO_HornRq 1;
BA_ "GenSigSNA" SG_ 810 PTO_HornRq "0h";
BA_ "GenSigCycleTime" SG_ 810 PTO_RmtThrottleSts 100;
BA_ "FlexKomSigStartValue" SG_ 810 PTO_RmtThrottleSts "00000000000000h";
BA_ "GenSigTimeout_IC" SG_ 810 PTO_RmtThrottleSts 1050;
BA_ "FlexKomSID" SG_ 810 PTO_RmtThrottleSts 1761;
BA_ "FlexKomSigStartPos" SG_ 810 PTO_RmtThrottleSts 7;
BA_ "FlexKomSigLaenge" SG_ 810 PTO_RmtThrottleSts 56;
BA_ "FlexKomSigName" SG_ 810 PTO_RmtThrottleSts "PTO_PKT";
BA_ "FlexKomComment" SG_ 810 PTO_RmtThrottleSts "Power takeoff status packet";
BA_ "FlexKomIsMotorola" SG_ 810 PTO_RmtThrottleSts 1;
BA_ "GenSigSNA" SG_ 810 PTO_RmtThrottleSts "0h";
BA_ "GenSigCycleTime" SG_ 810 PTO_SingleRPM 100;
BA_ "FlexKomSigStartValue" SG_ 810 PTO_SingleRPM "00000000000000h";
BA_ "GenSigTimeout_CBC" SG_ 810 PTO_SingleRPM 1050;
BA_ "GenSigTimeout_IC" SG_ 810 PTO_SingleRPM 1050;
BA_ "FlexKomSID" SG_ 810 PTO_SingleRPM 1761;
BA_ "FlexKomSigStartPos" SG_ 810 PTO_SingleRPM 7;
BA_ "FlexKomSigLaenge" SG_ 810 PTO_SingleRPM 56;
BA_ "FlexKomSigName" SG_ 810 PTO_SingleRPM "PTO_PKT";
BA_ "FlexKomComment" SG_ 810 PTO_SingleRPM "Power takeoff status packet";
BA_ "FlexKomIsMotorola" SG_ 810 PTO_SingleRPM 1;
BA_ "GenSigSNA" SG_ 810 PTO_SingleRPM "FFh";
BA_ "GenSigCycleTime" SG_ 810 PTO_RPM1 100;
BA_ "FlexKomSigStartValue" SG_ 810 PTO_RPM1 "00000000000000h";
BA_ "GenSigTimeout_CBC" SG_ 810 PTO_RPM1 1050;
BA_ "GenSigTimeout_IC" SG_ 810 PTO_RPM1 1050;
BA_ "FlexKomSID" SG_ 810 PTO_RPM1 1761;
BA_ "FlexKomSigStartPos" SG_ 810 PTO_RPM1 7;
BA_ "FlexKomSigLaenge" SG_ 810 PTO_RPM1 56;
BA_ "FlexKomSigName" SG_ 810 PTO_RPM1 "PTO_PKT";
BA_ "FlexKomComment" SG_ 810 PTO_RPM1 "Power takeoff status packet";
BA_ "FlexKomIsMotorola" SG_ 810 PTO_RPM1 1;
BA_ "GenSigSNA" SG_ 810 PTO_RPM1 "FFh";
BA_ "GenSigCycleTime" SG_ 810 PTO_RPM2 100;
BA_ "FlexKomSigStartValue" SG_ 810 PTO_RPM2 "00000000000000h";
BA_ "GenSigTimeout_CBC" SG_ 810 PTO_RPM2 1050;
BA_ "GenSigTimeout_IC" SG_ 810 PTO_RPM2 1050;
BA_ "FlexKomSID" SG_ 810 PTO_RPM2 1761;
BA_ "FlexKomSigStartPos" SG_ 810 PTO_RPM2 7;
BA_ "FlexKomSigLaenge" SG_ 810 PTO_RPM2 56;
BA_ "FlexKomSigName" SG_ 810 PTO_RPM2 "PTO_PKT";
BA_ "FlexKomComment" SG_ 810 PTO_RPM2 "Power takeoff status packet";
BA_ "FlexKomIsMotorola" SG_ 810 PTO_RPM2 1;
BA_ "GenSigSNA" SG_ 810 PTO_RPM2 "FFh";
BA_ "GenSigCycleTime" SG_ 810 PTO_RPM3 100;
BA_ "FlexKomSigStartValue" SG_ 810 PTO_RPM3 "00000000000000h";
BA_ "GenSigTimeout_CBC" SG_ 810 PTO_RPM3 1050;
BA_ "GenSigTimeout_IC" SG_ 810 PTO_RPM3 1050;
BA_ "FlexKomSID" SG_ 810 PTO_RPM3 1761;
BA_ "FlexKomSigStartPos" SG_ 810 PTO_RPM3 7;
BA_ "FlexKomSigLaenge" SG_ 810 PTO_RPM3 56;
BA_ "FlexKomSigName" SG_ 810 PTO_RPM3 "PTO_PKT";
BA_ "FlexKomComment" SG_ 810 PTO_RPM3 "Power takeoff status packet";
BA_ "FlexKomIsMotorola" SG_ 810 PTO_RPM3 1;
BA_ "GenSigSNA" SG_ 810 PTO_RPM3 "FFh";
BA_ "GenSigCycleTime" SG_ 810 PTO_Sts 100;
BA_ "FlexKomSigStartValue" SG_ 810 PTO_Sts "00000000000000h";
BA_ "GenSigTimeout_CBC" SG_ 810 PTO_Sts 1050;
BA_ "GenSigTimeout_IC" SG_ 810 PTO_Sts 1050;
BA_ "FlexKomSID" SG_ 810 PTO_Sts 1761;
BA_ "FlexKomSigStartPos" SG_ 810 PTO_Sts 7;
BA_ "FlexKomSigLaenge" SG_ 810 PTO_Sts 56;
BA_ "FlexKomSigName" SG_ 810 PTO_Sts "PTO_PKT";
BA_ "FlexKomComment" SG_ 810 PTO_Sts "Power takeoff status packet";
BA_ "FlexKomIsMotorola" SG_ 810 PTO_Sts 1;
BA_ "GenSigSNA" SG_ 810 PTO_Sts "1Fh";
BA_ "GenSigCycleTime" SG_ 810 HP_MODE_STS 100;
BA_ "FlexKomSigStartValue" SG_ 810 HP_MODE_STS "00h";
BA_ "GenSigTimeout_CBC" SG_ 810 HP_MODE_STS 1050;
BA_ "FlexKomSID" SG_ 810 HP_MODE_STS 2045;
BA_ "FlexKomSigStartPos" SG_ 810 HP_MODE_STS 60;
BA_ "FlexKomSigLaenge" SG_ 810 HP_MODE_STS 3;
BA_ "FlexKomSigName" SG_ 810 HP_MODE_STS "HP_MODE_STS";
BA_ "FlexKomComment" SG_ 810 HP_MODE_STS "Engine power mode personalization status";
BA_ "FlexKomIsMotorola" SG_ 810 HP_MODE_STS 1;
BA_ "GenSigSNA" SG_ 810 HP_MODE_STS "7h";
BA_ "GenSigCycleTime" SG_ 810 FuelTransSts 100;
BA_ "FlexKomSigStartValue" SG_ 810 FuelTransSts "00h";
BA_ "GenSigTimeout_IC" SG_ 810 FuelTransSts 1050;
BA_ "FlexKomSID" SG_ 810 FuelTransSts 1946;
BA_ "FlexKomSigStartPos" SG_ 810 FuelTransSts 63;
BA_ "FlexKomSigLaenge" SG_ 810 FuelTransSts 3;
BA_ "FlexKomSigName" SG_ 810 FuelTransSts "FuelTransSts";
BA_ "FlexKomComment" SG_ 810 FuelTransSts "Fuel transfer status";
BA_ "FlexKomIsMotorola" SG_ 810 FuelTransSts 1;
BA_ "GenSigSNA" SG_ 810 FuelTransSts "0h";
BA_ "GenSigCycleTime" SG_ 811 TcaseSrvRq 500;
BA_ "FlexKomSigStartValue" SG_ 811 TcaseSrvRq "00h";
BA_ "GenSigTimeout_IC" SG_ 811 TcaseSrvRq 5250;
BA_ "FlexKomSID" SG_ 811 TcaseSrvRq 1604;
BA_ "FlexKomSigLaenge" SG_ 811 TcaseSrvRq 1;
BA_ "FlexKomSigName" SG_ 811 TcaseSrvRq "TcaseSrvRq";
BA_ "FlexKomComment" SG_ 811 TcaseSrvRq "Final drive service request";
BA_ "FlexKomIsMotorola" SG_ 811 TcaseSrvRq 1;
BA_ "GenSigSNA" SG_ 811 TcaseSrvRq "0h";
BA_ "GenSigCycleTime" SG_ 811 AxlLckrSts 500;
BA_ "FlexKomSigStartValue" SG_ 811 AxlLckrSts "00h";
BA_ "GenSigTimeout_IC" SG_ 811 AxlLckrSts 5250;
BA_ "FlexKomSID" SG_ 811 AxlLckrSts 2031;
BA_ "FlexKomSigStartPos" SG_ 811 AxlLckrSts 5;
BA_ "FlexKomSigLaenge" SG_ 811 AxlLckrSts 2;
BA_ "FlexKomSigName" SG_ 811 AxlLckrSts "AxlLckrSts";
BA_ "FlexKomComment" SG_ 811 AxlLckrSts "Axle locker status";
BA_ "FlexKomIsMotorola" SG_ 811 AxlLckrSts 1;
BA_ "GenSigSNA" SG_ 811 AxlLckrSts "3h";
BA_ "GenSigCycleTime" SG_ 811 SwayBarSts 500;
BA_ "FlexKomSigStartValue" SG_ 811 SwayBarSts "00h";
BA_ "GenSigTimeout_IC" SG_ 811 SwayBarSts 5250;
BA_ "FlexKomSID" SG_ 811 SwayBarSts 2030;
BA_ "FlexKomSigStartPos" SG_ 811 SwayBarSts 7;
BA_ "FlexKomSigLaenge" SG_ 811 SwayBarSts 2;
BA_ "FlexKomSigName" SG_ 811 SwayBarSts "SwayBarSts";
BA_ "FlexKomComment" SG_ 811 SwayBarSts "Swaybar status";
BA_ "FlexKomIsMotorola" SG_ 811 SwayBarSts 1;
BA_ "GenSigSNA" SG_ 811 SwayBarSts "3h";
BA_ "GenSigCycleTime" SG_ 811 AxleLockerEVICDisplay 500;
BA_ "FlexKomSigStartValue" SG_ 811 AxleLockerEVICDisplay "00h";
BA_ "GenSigTimeout_IC" SG_ 811 AxleLockerEVICDisplay 5250;
BA_ "FlexKomSID" SG_ 811 AxleLockerEVICDisplay 2029;
BA_ "FlexKomSigStartPos" SG_ 811 AxleLockerEVICDisplay 11;
BA_ "FlexKomSigLaenge" SG_ 811 AxleLockerEVICDisplay 4;
BA_ "FlexKomSigName" SG_ 811 AxleLockerEVICDisplay "AxleLockerEVICDisplay";
BA_ "FlexKomComment" SG_ 811 AxleLockerEVICDisplay "Axle locker HMI display request";
BA_ "FlexKomIsMotorola" SG_ 811 AxleLockerEVICDisplay 1;
BA_ "GenSigSNA" SG_ 811 AxleLockerEVICDisplay "Fh";
BA_ "GenSigCycleTime" SG_ 811 Swaybar_EVICDisplay 500;
BA_ "FlexKomSigStartValue" SG_ 811 Swaybar_EVICDisplay "00h";
BA_ "GenSigTimeout_IC" SG_ 811 Swaybar_EVICDisplay 5250;
BA_ "FlexKomSID" SG_ 811 Swaybar_EVICDisplay 2028;
BA_ "FlexKomSigStartPos" SG_ 811 Swaybar_EVICDisplay 15;
BA_ "FlexKomSigLaenge" SG_ 811 Swaybar_EVICDisplay 4;
BA_ "FlexKomSigName" SG_ 811 Swaybar_EVICDisplay "Swaybar_EVICDisplay";
BA_ "FlexKomComment" SG_ 811 Swaybar_EVICDisplay "Swaybar HMI display request";
BA_ "FlexKomIsMotorola" SG_ 811 Swaybar_EVICDisplay 1;
BA_ "GenSigSNA" SG_ 811 Swaybar_EVICDisplay "Fh";
BA_ "GenSigSendType" SG_ 816 PLG_Stat 5;
BA_ "GenSigCycleTime" SG_ 816 PLG_Stat 1000;
BA_ "FlexKomSigStartValue" SG_ 816 PLG_Stat "00h";
BA_ "GenSigTimeout_IC" SG_ 816 PLG_Stat 10500;
BA_ "FlexKomSID" SG_ 816 PLG_Stat 16;
BA_ "FlexKomSigStartPos" SG_ 816 PLG_Stat 3;
BA_ "FlexKomSigLaenge" SG_ 816 PLG_Stat 4;
BA_ "FlexKomSigName" SG_ 816 PLG_Stat "PLG_Stat";
BA_ "FlexKomComment" SG_ 816 PLG_Stat "Power liftgate status";
BA_ "FlexKomIsMotorola" SG_ 816 PLG_Stat 1;
BA_ "GenSigSNA" SG_ 816 PLG_Stat "Fh";
BA_ "GenSigSendType" SG_ 816 DL_Lim_Stat 5;
BA_ "GenSigCycleTime" SG_ 816 DL_Lim_Stat 1000;
BA_ "FlexKomSigStartValue" SG_ 816 DL_Lim_Stat "03h";
BA_ "GenSigStartValue" SG_ 816 DL_Lim_Stat 3;
BA_ "GenSigTimeout_IC" SG_ 816 DL_Lim_Stat 10500;
BA_ "FlexKomSID" SG_ 816 DL_Lim_Stat 19;
BA_ "FlexKomSigStartPos" SG_ 816 DL_Lim_Stat 5;
BA_ "FlexKomSigLaenge" SG_ 816 DL_Lim_Stat 2;
BA_ "FlexKomSigName" SG_ 816 DL_Lim_Stat "DL_Lim_Stat";
BA_ "FlexKomComment" SG_ 816 DL_Lim_Stat "Deck lid limit state";
BA_ "FlexKomIsMotorola" SG_ 816 DL_Lim_Stat 1;
BA_ "GenSigSNA" SG_ 816 DL_Lim_Stat "3h";
BA_ "GenSigSendType" SG_ 816 TILT_IN_REV_D 5;
BA_ "GenSigCycleTime" SG_ 816 TILT_IN_REV_D 1000;
BA_ "FlexKomSigStartValue" SG_ 816 TILT_IN_REV_D "00h";
BA_ "GenSigTimeout_IC" SG_ 816 TILT_IN_REV_D 10500;
BA_ "FlexKomSID" SG_ 816 TILT_IN_REV_D 695;
BA_ "FlexKomSigStartPos" SG_ 816 TILT_IN_REV_D 6;
BA_ "FlexKomSigLaenge" SG_ 816 TILT_IN_REV_D 1;
BA_ "FlexKomSigName" SG_ 816 TILT_IN_REV_D "TILT_IN_REV_D";
BA_ "FlexKomComment" SG_ 816 TILT_IN_REV_D "Tilt in reverese feature enabled; [0] = no, [1] = ";
BA_ "FlexKomIsMotorola" SG_ 816 TILT_IN_REV_D 1;
BA_ "GenSigSNA" SG_ 816 TILT_IN_REV_D "0h";
BA_ "GenSigSendType" SG_ 816 TILT_IN_REV_P 5;
BA_ "GenSigCycleTime" SG_ 816 TILT_IN_REV_P 1000;
BA_ "FlexKomSigStartValue" SG_ 816 TILT_IN_REV_P "00h";
BA_ "GenSigTimeout_IC" SG_ 816 TILT_IN_REV_P 10500;
BA_ "FlexKomSID" SG_ 816 TILT_IN_REV_P 696;
BA_ "FlexKomSigStartPos" SG_ 816 TILT_IN_REV_P 7;
BA_ "FlexKomSigLaenge" SG_ 816 TILT_IN_REV_P 1;
BA_ "FlexKomSigName" SG_ 816 TILT_IN_REV_P "TILT_IN_REV_P";
BA_ "FlexKomComment" SG_ 816 TILT_IN_REV_P "Tilt in reverese feature enabled; [0] = no, [1] = ";
BA_ "FlexKomIsMotorola" SG_ 816 TILT_IN_REV_P 1;
BA_ "GenSigSNA" SG_ 816 TILT_IN_REV_P "0h";
BA_ "GenSigSendType" SG_ 816 EModeSwPsd 5;
BA_ "GenSigCycleTime" SG_ 816 EModeSwPsd 1000;
BA_ "FlexKomSigStartValue" SG_ 816 EModeSwPsd "00h";
BA_ "FlexKomSID" SG_ 816 EModeSwPsd 1360;
BA_ "FlexKomSigStartPos" SG_ 816 EModeSwPsd 9;
BA_ "FlexKomSigLaenge" SG_ 816 EModeSwPsd 2;
BA_ "FlexKomSigName" SG_ 816 EModeSwPsd "EModeSwPsd";
BA_ "FlexKomComment" SG_ 816 EModeSwPsd "E-Mode switch pressed";
BA_ "FlexKomIsMotorola" SG_ 816 EModeSwPsd 1;
BA_ "GenSigSNA" SG_ 816 EModeSwPsd "3h";
BA_ "GenSigSendType" SG_ 816 EB_SW_PSD 5;
BA_ "GenSigCycleTime" SG_ 816 EB_SW_PSD 1000;
BA_ "FlexKomSigStartValue" SG_ 816 EB_SW_PSD "00h";
BA_ "FlexKomSID" SG_ 816 EB_SW_PSD 1433;
BA_ "FlexKomSigStartPos" SG_ 816 EB_SW_PSD 10;
BA_ "FlexKomSigLaenge" SG_ 816 EB_SW_PSD 1;
BA_ "FlexKomSigName" SG_ 816 EB_SW_PSD "EB_SW_PSD";
BA_ "FlexKomComment" SG_ 816 EB_SW_PSD "Exhaust brake switch pressed (1=pressed)";
BA_ "FlexKomIsMotorola" SG_ 816 EB_SW_PSD 1;
BA_ "GenSigSNA" SG_ 816 EB_SW_PSD "0h";
BA_ "GenSigSendType" SG_ 816 CHIME_STS_RF 5;
BA_ "GenSigCycleTime" SG_ 816 CHIME_STS_RF 1000;
BA_ "FlexKomSigStartValue" SG_ 816 CHIME_STS_RF "00h";
BA_ "FlexKomSID" SG_ 816 CHIME_STS_RF 1774;
BA_ "FlexKomSigStartPos" SG_ 816 CHIME_STS_RF 14;
BA_ "FlexKomSigLaenge" SG_ 816 CHIME_STS_RF 4;
BA_ "FlexKomSigName" SG_ 816 CHIME_STS_RF "ChimeStatPkt";
BA_ "FlexKomComment" SG_ 816 CHIME_STS_RF "Chime status packet";
BA_ "FlexKomIsMotorola" SG_ 816 CHIME_STS_RF 1;
BA_ "GenSigSNA" SG_ 816 CHIME_STS_RF "0h";
BA_ "GenSigSendType" SG_ 816 CHIME_STS_LF 5;
BA_ "GenSigCycleTime" SG_ 816 CHIME_STS_LF 1000;
BA_ "FlexKomSigStartValue" SG_ 816 CHIME_STS_LF "00h";
BA_ "FlexKomSID" SG_ 816 CHIME_STS_LF 1774;
BA_ "FlexKomSigStartPos" SG_ 816 CHIME_STS_LF 14;
BA_ "FlexKomSigLaenge" SG_ 816 CHIME_STS_LF 4;
BA_ "FlexKomSigName" SG_ 816 CHIME_STS_LF "ChimeStatPkt";
BA_ "FlexKomComment" SG_ 816 CHIME_STS_LF "Chime status packet";
BA_ "FlexKomIsMotorola" SG_ 816 CHIME_STS_LF 1;
BA_ "GenSigSNA" SG_ 816 CHIME_STS_LF "0h";
BA_ "GenSigSendType" SG_ 816 CHIME_STS_RR 5;
BA_ "GenSigCycleTime" SG_ 816 CHIME_STS_RR 1000;
BA_ "FlexKomSigStartValue" SG_ 816 CHIME_STS_RR "00h";
BA_ "FlexKomSID" SG_ 816 CHIME_STS_RR 1774;
BA_ "FlexKomSigStartPos" SG_ 816 CHIME_STS_RR 14;
BA_ "FlexKomSigLaenge" SG_ 816 CHIME_STS_RR 4;
BA_ "FlexKomSigName" SG_ 816 CHIME_STS_RR "ChimeStatPkt";
BA_ "FlexKomComment" SG_ 816 CHIME_STS_RR "Chime status packet";
BA_ "FlexKomIsMotorola" SG_ 816 CHIME_STS_RR 1;
BA_ "GenSigSNA" SG_ 816 CHIME_STS_RR "0h";
BA_ "GenSigSendType" SG_ 816 CHIME_STS_LR 5;
BA_ "GenSigCycleTime" SG_ 816 CHIME_STS_LR 1000;
BA_ "FlexKomSigStartValue" SG_ 816 CHIME_STS_LR "00h";
BA_ "FlexKomSID" SG_ 816 CHIME_STS_LR 1774;
BA_ "FlexKomSigStartPos" SG_ 816 CHIME_STS_LR 14;
BA_ "FlexKomSigLaenge" SG_ 816 CHIME_STS_LR 4;
BA_ "FlexKomSigName" SG_ 816 CHIME_STS_LR "ChimeStatPkt";
BA_ "FlexKomComment" SG_ 816 CHIME_STS_LR "Chime status packet";
BA_ "FlexKomIsMotorola" SG_ 816 CHIME_STS_LR 1;
BA_ "GenSigSNA" SG_ 816 CHIME_STS_LR "0h";
BA_ "GenSigSendType" SG_ 816 ADCM_Sw_Psd 5;
BA_ "GenSigCycleTime" SG_ 816 ADCM_Sw_Psd 1000;
BA_ "FlexKomSigStartValue" SG_ 816 ADCM_Sw_Psd "00h";
BA_ "FlexKomSID" SG_ 816 ADCM_Sw_Psd 1150;
BA_ "FlexKomSigStartPos" SG_ 816 ADCM_Sw_Psd 15;
BA_ "FlexKomSigLaenge" SG_ 816 ADCM_Sw_Psd 1;
BA_ "FlexKomSigName" SG_ 816 ADCM_Sw_Psd "ADCM_Sw_Psd";
BA_ "FlexKomComment" SG_ 816 ADCM_Sw_Psd "Active damping control module switch pressed";
BA_ "FlexKomIsMotorola" SG_ 816 ADCM_Sw_Psd 1;
BA_ "GenSigSNA" SG_ 816 ADCM_Sw_Psd "0h";
BA_ "GenSigSendType" SG_ 816 TCASE_SFT_RQ 5;
BA_ "GenSigCycleTime" SG_ 816 TCASE_SFT_RQ 1000;
BA_ "FlexKomSigStartValue" SG_ 816 TCASE_SFT_RQ "07h";
BA_ "GenSigStartValue" SG_ 816 TCASE_SFT_RQ 7;
BA_ "FlexKomSID" SG_ 816 TCASE_SFT_RQ 1402;
BA_ "FlexKomSigStartPos" SG_ 816 TCASE_SFT_RQ 18;
BA_ "FlexKomSigLaenge" SG_ 816 TCASE_SFT_RQ 3;
BA_ "FlexKomSigName" SG_ 816 TCASE_SFT_RQ "TCASE_SFT_RQ";
BA_ "FlexKomComment" SG_ 816 TCASE_SFT_RQ "Transfer case shift request";
BA_ "FlexKomIsMotorola" SG_ 816 TCASE_SFT_RQ 1;
BA_ "GenSigSNA" SG_ 816 TCASE_SFT_RQ "7h";
BA_ "GenSigSendType" SG_ 816 TRAC_PSD 5;
BA_ "GenSigCycleTime" SG_ 816 TRAC_PSD 1000;
BA_ "FlexKomSigStartValue" SG_ 816 TRAC_PSD "00h";
BA_ "FlexKomSID" SG_ 816 TRAC_PSD 424;
BA_ "FlexKomSigStartPos" SG_ 816 TRAC_PSD 19;
BA_ "FlexKomSigLaenge" SG_ 816 TRAC_PSD 1;
BA_ "FlexKomSigName" SG_ 816 TRAC_PSD "TRAC_PSD";
BA_ "FlexKomComment" SG_ 816 TRAC_PSD "Traction on/off button pressed; [0] = Not Pressed,";
BA_ "FlexKomIsMotorola" SG_ 816 TRAC_PSD 1;
BA_ "GenSigSNA" SG_ 816 TRAC_PSD "0h";
BA_ "GenSigSendType" SG_ 816 HILL_DES_RQ 5;
BA_ "GenSigCycleTime" SG_ 816 HILL_DES_RQ 1000;
BA_ "FlexKomSigStartValue" SG_ 816 HILL_DES_RQ "00h";
BA_ "FlexKomSID" SG_ 816 HILL_DES_RQ 423;
BA_ "FlexKomSigStartPos" SG_ 816 HILL_DES_RQ 21;
BA_ "FlexKomSigLaenge" SG_ 816 HILL_DES_RQ 2;
BA_ "FlexKomSigName" SG_ 816 HILL_DES_RQ "HILL_DES_RQ";
BA_ "FlexKomComment" SG_ 816 HILL_DES_RQ "Hill Descent Request";
BA_ "FlexKomIsMotorola" SG_ 816 HILL_DES_RQ 1;
BA_ "GenSigSNA" SG_ 816 HILL_DES_RQ "3h";
BA_ "GenSigSendType" SG_ 816 AddTurnLmp_Flt_D 5;
BA_ "GenSigCycleTime" SG_ 816 AddTurnLmp_Flt_D 1000;
BA_ "FlexKomSigStartValue" SG_ 816 AddTurnLmp_Flt_D "00h";
BA_ "GenSigTimeout_IC" SG_ 816 AddTurnLmp_Flt_D 10500;
BA_ "FlexKomSID" SG_ 816 AddTurnLmp_Flt_D 689;
BA_ "FlexKomSigStartPos" SG_ 816 AddTurnLmp_Flt_D 22;
BA_ "FlexKomSigLaenge" SG_ 816 AddTurnLmp_Flt_D 1;
BA_ "FlexKomSigName" SG_ 816 AddTurnLmp_Flt_D "AddTurnLmp_Flt_D";
BA_ "FlexKomComment" SG_ 816 AddTurnLmp_Flt_D "Additional turn indication lamp fault - driver sid";
BA_ "FlexKomIsMotorola" SG_ 816 AddTurnLmp_Flt_D 1;
BA_ "GenSigSNA" SG_ 816 AddTurnLmp_Flt_D "0h";
BA_ "GenSigSendType" SG_ 816 AddTurnLmp_Flt_P 5;
BA_ "GenSigCycleTime" SG_ 816 AddTurnLmp_Flt_P 1000;
BA_ "FlexKomSigStartValue" SG_ 816 AddTurnLmp_Flt_P "00h";
BA_ "GenSigTimeout_IC" SG_ 816 AddTurnLmp_Flt_P 10500;
BA_ "FlexKomSID" SG_ 816 AddTurnLmp_Flt_P 690;
BA_ "FlexKomSigStartPos" SG_ 816 AddTurnLmp_Flt_P 23;
BA_ "FlexKomSigLaenge" SG_ 816 AddTurnLmp_Flt_P 1;
BA_ "FlexKomSigName" SG_ 816 AddTurnLmp_Flt_P "AddTurnLmp_Flt_P";
BA_ "FlexKomComment" SG_ 816 AddTurnLmp_Flt_P "Additional turn indication lamp fault - passenger ";
BA_ "FlexKomIsMotorola" SG_ 816 AddTurnLmp_Flt_P 1;
BA_ "GenSigSNA" SG_ 816 AddTurnLmp_Flt_P "0h";
BA_ "GenSigSendType" SG_ 816 US_METRIC 5;
BA_ "GenSigCycleTime" SG_ 816 US_METRIC 1000;
BA_ "FlexKomSigStartValue" SG_ 816 US_METRIC "1Eh";
BA_ "GenSigTimeout_IC" SG_ 816 US_METRIC 10500;
BA_ "FlexKomSID" SG_ 816 US_METRIC 454;
BA_ "FlexKomSigStartPos" SG_ 816 US_METRIC 28;
BA_ "FlexKomSigLaenge" SG_ 816 US_METRIC 5;
BA_ "FlexKomSigName" SG_ 816 US_METRIC "CFG_STAT";
BA_ "FlexKomComment" SG_ 816 US_METRIC "Configuration status";
BA_ "FlexKomIsMotorola" SG_ 816 US_METRIC 1;
BA_ "GenSigSNA" SG_ 816 US_METRIC "0h";
BA_ "GenSigSendType" SG_ 816 LANG 5;
BA_ "GenSigCycleTime" SG_ 816 LANG 1000;
BA_ "FlexKomSigStartValue" SG_ 816 LANG "1Eh";
BA_ "GenSigStartValue" SG_ 816 LANG 15;
BA_ "GenSigTimeout_IC" SG_ 816 LANG 10500;
BA_ "FlexKomSID" SG_ 816 LANG 454;
BA_ "FlexKomSigStartPos" SG_ 816 LANG 28;
BA_ "FlexKomSigLaenge" SG_ 816 LANG 5;
BA_ "FlexKomSigName" SG_ 816 LANG "CFG_STAT";
BA_ "FlexKomComment" SG_ 816 LANG "Configuration status";
BA_ "FlexKomIsMotorola" SG_ 816 LANG 1;
BA_ "GenSigSNA" SG_ 816 LANG "Fh";
BA_ "GenSigSendType" SG_ 816 PLG_Req_PE 5;
BA_ "GenSigCycleTime" SG_ 816 PLG_Req_PE 1000;
BA_ "FlexKomSigStartValue" SG_ 816 PLG_Req_PE "00h";
BA_ "GenSigTimeout_RF_HUB" SG_ 816 PLG_Req_PE 10500;
BA_ "FlexKomSID" SG_ 816 PLG_Req_PE 17;
BA_ "FlexKomSigStartPos" SG_ 816 PLG_Req_PE 31;
BA_ "FlexKomSigLaenge" SG_ 816 PLG_Req_PE 1;
BA_ "FlexKomSigName" SG_ 816 PLG_Req_PE "PLG_Req_PE";
BA_ "FlexKomComment" SG_ 816 PLG_Req_PE "Power Liftgate Requesting PE unlatch";
BA_ "FlexKomIsMotorola" SG_ 816 PLG_Req_PE 1;
BA_ "GenSigSNA" SG_ 816 PLG_Req_PE "0h";
BA_ "GenSigSendType" SG_ 816 TGW_DISP_STAT 5;
BA_ "GenSigCycleTime" SG_ 816 TGW_DISP_STAT 1000;
BA_ "FlexKomSigStartValue" SG_ 816 TGW_DISP_STAT "00h";
BA_ "GenSigTimeout_IC" SG_ 816 TGW_DISP_STAT 10500;
BA_ "FlexKomSID" SG_ 816 TGW_DISP_STAT 652;
BA_ "FlexKomSigStartPos" SG_ 816 TGW_DISP_STAT 35;
BA_ "FlexKomSigLaenge" SG_ 816 TGW_DISP_STAT 4;
BA_ "FlexKomSigName" SG_ 816 TGW_DISP_STAT "TGW_DISP_STAT";
BA_ "FlexKomComment" SG_ 816 TGW_DISP_STAT "TGW Display status";
BA_ "FlexKomIsMotorola" SG_ 816 TGW_DISP_STAT 1;
BA_ "GenSigSNA" SG_ 816 TGW_DISP_STAT "Fh";
BA_ "GenSigSendType" SG_ 816 AHB_ENBL 5;
BA_ "GenSigCycleTime" SG_ 816 AHB_ENBL 1000;
BA_ "FlexKomSigStartValue" SG_ 816 AHB_ENBL "00h";
BA_ "GenSigTimeout_IC" SG_ 816 AHB_ENBL 10500;
BA_ "FlexKomSID" SG_ 816 AHB_ENBL 733;
BA_ "FlexKomSigStartPos" SG_ 816 AHB_ENBL 36;
BA_ "FlexKomSigLaenge" SG_ 816 AHB_ENBL 1;
BA_ "FlexKomSigName" SG_ 816 AHB_ENBL "AHB_ENBL";
BA_ "FlexKomComment" SG_ 816 AHB_ENBL "Auto highbeam enable";
BA_ "FlexKomIsMotorola" SG_ 816 AHB_ENBL 1;
BA_ "GenSigSNA" SG_ 816 AHB_ENBL "0h";
BA_ "GenSigSendType" SG_ 816 PassWinLO_Enbl 5;
BA_ "GenSigCycleTime" SG_ 816 PassWinLO_Enbl 1000;
BA_ "FlexKomSigStartValue" SG_ 816 PassWinLO_Enbl "00h";
BA_ "GenSigTimeout_IC" SG_ 816 PassWinLO_Enbl 10500;
BA_ "FlexKomSID" SG_ 816 PassWinLO_Enbl 1429;
BA_ "FlexKomSigStartPos" SG_ 816 PassWinLO_Enbl 37;
BA_ "FlexKomSigLaenge" SG_ 816 PassWinLO_Enbl 1;
BA_ "FlexKomSigName" SG_ 816 PassWinLO_Enbl "PassWinLO_Enbl";
BA_ "FlexKomComment" SG_ 816 PassWinLO_Enbl "Passenger window locked out enabled";
BA_ "FlexKomIsMotorola" SG_ 816 PassWinLO_Enbl 1;
BA_ "GenSigSNA" SG_ 816 PassWinLO_Enbl "0h";
BA_ "GenSigSendType" SG_ 816 RemStEnbl_DCS 5;
BA_ "GenSigCycleTime" SG_ 816 RemStEnbl_DCS 1000;
BA_ "FlexKomSigStartValue" SG_ 816 RemStEnbl_DCS "01h";
BA_ "GenSigStartValue" SG_ 816 RemStEnbl_DCS 1;
BA_ "GenSigTimeout_IC" SG_ 816 RemStEnbl_DCS 10500;
BA_ "FlexKomSID" SG_ 816 RemStEnbl_DCS 2043;
BA_ "FlexKomSigStartPos" SG_ 816 RemStEnbl_DCS 38;
BA_ "FlexKomSigLaenge" SG_ 816 RemStEnbl_DCS 1;
BA_ "FlexKomSigName" SG_ 816 RemStEnbl_DCS "RemStEnbl_DCS";
BA_ "FlexKomComment" SG_ 816 RemStEnbl_DCS "Driver comfort system remote start status; [0] = O";
BA_ "FlexKomIsMotorola" SG_ 816 RemStEnbl_DCS 1;
BA_ "GenSigSNA" SG_ 816 RemStEnbl_DCS "1h";
BA_ "GenSigSendType" SG_ 816 RemStNrmlStEnbl_DCS 5;
BA_ "GenSigCycleTime" SG_ 816 RemStNrmlStEnbl_DCS 1000;
BA_ "FlexKomSigStartValue" SG_ 816 RemStNrmlStEnbl_DCS "01h";
BA_ "GenSigStartValue" SG_ 816 RemStNrmlStEnbl_DCS 1;
BA_ "GenSigTimeout_IC" SG_ 816 RemStNrmlStEnbl_DCS 10500;
BA_ "FlexKomSID" SG_ 816 RemStNrmlStEnbl_DCS 2044;
BA_ "FlexKomSigStartPos" SG_ 816 RemStNrmlStEnbl_DCS 39;
BA_ "FlexKomSigLaenge" SG_ 816 RemStNrmlStEnbl_DCS 1;
BA_ "FlexKomSigName" SG_ 816 RemStNrmlStEnbl_DCS "RemStNrmlStEnbl_DCS";
BA_ "FlexKomComment" SG_ 816 RemStNrmlStEnbl_DCS "Driver comfort system remote & normal start status";
BA_ "FlexKomIsMotorola" SG_ 816 RemStNrmlStEnbl_DCS 1;
BA_ "GenSigSNA" SG_ 816 RemStNrmlStEnbl_DCS "1h";
BA_ "GenSigSendType" SG_ 816 HVAC_CLNT_FLW_MIN 5;
BA_ "GenSigCycleTime" SG_ 816 HVAC_CLNT_FLW_MIN 1000;
BA_ "FlexKomSigStartValue" SG_ 816 HVAC_CLNT_FLW_MIN "FFh";
BA_ "GenSigStartValue" SG_ 816 HVAC_CLNT_FLW_MIN 255;
BA_ "FlexKomSID" SG_ 816 HVAC_CLNT_FLW_MIN 1527;
BA_ "FlexKomSigStartPos" SG_ 816 HVAC_CLNT_FLW_MIN 47;
BA_ "FlexKomSigLaenge" SG_ 816 HVAC_CLNT_FLW_MIN 8;
BA_ "FlexKomSigName" SG_ 816 HVAC_CLNT_FLW_MIN "HVAC_CLNT_FLW_MIN";
BA_ "FlexKomComment" SG_ 816 HVAC_CLNT_FLW_MIN "HVAC coolant flow minimum request";
BA_ "FlexKomIsMotorola" SG_ 816 HVAC_CLNT_FLW_MIN 1;
BA_ "GenSigSNA" SG_ 816 HVAC_CLNT_FLW_MIN "FFh";
BA_ "GenSigSendType" SG_ 816 ICS_btn41 5;
BA_ "GenSigCycleTime" SG_ 816 ICS_btn41 1000;
BA_ "FlexKomSigStartValue" SG_ 816 ICS_btn41 "00h";
BA_ "FlexKomSID" SG_ 816 ICS_btn41 1800;
BA_ "FlexKomSigStartPos" SG_ 816 ICS_btn41 49;
BA_ "FlexKomSigLaenge" SG_ 816 ICS_btn41 2;
BA_ "FlexKomSigName" SG_ 816 ICS_btn41 "ICS_btn41";
BA_ "FlexKomComment" SG_ 816 ICS_btn41 "Emode button status";
BA_ "FlexKomIsMotorola" SG_ 816 ICS_btn41 1;
BA_ "GenSigSNA" SG_ 816 ICS_btn41 "3h";
BA_ "GenSigSendType" SG_ 816 ICS_btn_34 5;
BA_ "GenSigCycleTime" SG_ 816 ICS_btn_34 1000;
BA_ "FlexKomSigStartValue" SG_ 816 ICS_btn_34 "00h";
BA_ "FlexKomSID" SG_ 816 ICS_btn_34 1838;
BA_ "FlexKomSigStartPos" SG_ 816 ICS_btn_34 50;
BA_ "FlexKomSigLaenge" SG_ 816 ICS_btn_34 1;
BA_ "FlexKomSigName" SG_ 816 ICS_btn_34 "ICS_btn_34";
BA_ "FlexKomComment" SG_ 816 ICS_btn_34 "Stop/Start pressed";
BA_ "FlexKomIsMotorola" SG_ 816 ICS_btn_34 1;
BA_ "GenSigSNA" SG_ 816 ICS_btn_34 "0h";
BA_ "GenSigSendType" SG_ 816 ICS_btn_16 5;
BA_ "GenSigCycleTime" SG_ 816 ICS_btn_16 1000;
BA_ "FlexKomSigStartValue" SG_ 816 ICS_btn_16 "00h";
BA_ "FlexKomSID" SG_ 816 ICS_btn_16 1839;
BA_ "FlexKomSigStartPos" SG_ 816 ICS_btn_16 51;
BA_ "FlexKomSigLaenge" SG_ 816 ICS_btn_16 1;
BA_ "FlexKomSigName" SG_ 816 ICS_btn_16 "ICS_btn_16";
BA_ "FlexKomComment" SG_ 816 ICS_btn_16 "PPA pressed";
BA_ "FlexKomIsMotorola" SG_ 816 ICS_btn_16 1;
BA_ "GenSigSNA" SG_ 816 ICS_btn_16 "0h";
BA_ "GenSigSendType" SG_ 816 ICS_btn_17 5;
BA_ "GenSigCycleTime" SG_ 816 ICS_btn_17 1000;
BA_ "FlexKomSigStartValue" SG_ 816 ICS_btn_17 "00h";
BA_ "FlexKomSID" SG_ 816 ICS_btn_17 1840;
BA_ "FlexKomSigStartPos" SG_ 816 ICS_btn_17 52;
BA_ "FlexKomSigLaenge" SG_ 816 ICS_btn_17 1;
BA_ "FlexKomSigName" SG_ 816 ICS_btn_17 "ICS_btn_17";
BA_ "FlexKomComment" SG_ 816 ICS_btn_17 "PTS Off pressed";
BA_ "FlexKomIsMotorola" SG_ 816 ICS_btn_17 1;
BA_ "GenSigSNA" SG_ 816 ICS_btn_17 "0h";
BA_ "GenSigSendType" SG_ 816 ICS_btn_18 5;
BA_ "GenSigCycleTime" SG_ 816 ICS_btn_18 1000;
BA_ "FlexKomSigStartValue" SG_ 816 ICS_btn_18 "00h";
BA_ "FlexKomSID" SG_ 816 ICS_btn_18 1841;
BA_ "FlexKomSigStartPos" SG_ 816 ICS_btn_18 53;
BA_ "FlexKomSigLaenge" SG_ 816 ICS_btn_18 1;
BA_ "FlexKomSigName" SG_ 816 ICS_btn_18 "ICS_btn_18";
BA_ "FlexKomComment" SG_ 816 ICS_btn_18 "LDW Off pressed";
BA_ "FlexKomIsMotorola" SG_ 816 ICS_btn_18 1;
BA_ "GenSigSNA" SG_ 816 ICS_btn_18 "0h";
BA_ "GenSigSendType" SG_ 816 ICS_btn_19 5;
BA_ "GenSigCycleTime" SG_ 816 ICS_btn_19 1000;
BA_ "FlexKomSigStartValue" SG_ 816 ICS_btn_19 "00h";
BA_ "FlexKomSID" SG_ 816 ICS_btn_19 1842;
BA_ "FlexKomSigStartPos" SG_ 816 ICS_btn_19 54;
BA_ "FlexKomSigLaenge" SG_ 816 ICS_btn_19 1;
BA_ "FlexKomSigName" SG_ 816 ICS_btn_19 "ICS_btn_19";
BA_ "FlexKomComment" SG_ 816 ICS_btn_19 "FCW Off pressed; True = [1]";
BA_ "FlexKomIsMotorola" SG_ 816 ICS_btn_19 1;
BA_ "GenSigSNA" SG_ 816 ICS_btn_19 "0h";
BA_ "GenSigSendType" SG_ 816 DriveModeReq_Cluster 5;
BA_ "GenSigCycleTime" SG_ 816 DriveModeReq_Cluster 1000;
BA_ "FlexKomSigStartValue" SG_ 816 DriveModeReq_Cluster "00h";
BA_ "GenSigTimeout_IC" SG_ 816 DriveModeReq_Cluster 10500;
BA_ "FlexKomSID" SG_ 816 DriveModeReq_Cluster 2100;
BA_ "FlexKomSigStartPos" SG_ 816 DriveModeReq_Cluster 59;
BA_ "FlexKomSigLaenge" SG_ 816 DriveModeReq_Cluster 4;
BA_ "FlexKomSigName" SG_ 816 DriveModeReq_Cluster "DriveModeReq_Cluster";
BA_ "FlexKomComment" SG_ 816 DriveModeReq_Cluster "Drive mode request to cluster";
BA_ "FlexKomIsMotorola" SG_ 816 DriveModeReq_Cluster 1;
BA_ "GenSigSNA" SG_ 816 DriveModeReq_Cluster "Fh";
BA_ "GenSigSendType" SG_ 817 PSI_Gr1_RPM_SET 5;
BA_ "GenSigCycleTime" SG_ 817 PSI_Gr1_RPM_SET 1000;
BA_ "FlexKomSigStartValue" SG_ 817 PSI_Gr1_RPM_SET "00h";
BA_ "FlexKomSID" SG_ 817 PSI_Gr1_RPM_SET 2052;
BA_ "FlexKomSigStartPos" SG_ 817 PSI_Gr1_RPM_SET 4;
BA_ "FlexKomSigLaenge" SG_ 817 PSI_Gr1_RPM_SET 5;
BA_ "FlexKomSigName" SG_ 817 PSI_Gr1_RPM_SET "PSI_Gr1_RPM_SET";
BA_ "FlexKomComment" SG_ 817 PSI_Gr1_RPM_SET "Requested rpm set point for Performance Shift Indi";
BA_ "FlexKomIsMotorola" SG_ 817 PSI_Gr1_RPM_SET 1;
BA_ "GenSigSNA" SG_ 817 PSI_Gr1_RPM_SET "1Fh";
BA_ "GenSigSendType" SG_ 817 ICS_launch_hardbtn_status 5;
BA_ "GenSigCycleTime" SG_ 817 ICS_launch_hardbtn_status 1000;
BA_ "FlexKomSigStartValue" SG_ 817 ICS_launch_hardbtn_status "00h";
BA_ "FlexKomSID" SG_ 817 ICS_launch_hardbtn_status 2064;
BA_ "FlexKomSigStartPos" SG_ 817 ICS_launch_hardbtn_status 6;
BA_ "FlexKomSigLaenge" SG_ 817 ICS_launch_hardbtn_status 2;
BA_ "FlexKomSigName" SG_ 817 ICS_launch_hardbtn_status "ICS_launch_hardbtn_status";
BA_ "FlexKomComment" SG_ 817 ICS_launch_hardbtn_status "Launch hard button status";
BA_ "FlexKomIsMotorola" SG_ 817 ICS_launch_hardbtn_status 1;
BA_ "GenSigSNA" SG_ 817 ICS_launch_hardbtn_status "3h";
BA_ "GenSigSendType" SG_ 817 Launch_Sft_Btn_status 5;
BA_ "GenSigCycleTime" SG_ 817 Launch_Sft_Btn_status 1000;
BA_ "FlexKomSigStartValue" SG_ 817 Launch_Sft_Btn_status "00h";
BA_ "FlexKomSID" SG_ 817 Launch_Sft_Btn_status 2070;
BA_ "FlexKomSigStartPos" SG_ 817 Launch_Sft_Btn_status 7;
BA_ "FlexKomSigLaenge" SG_ 817 Launch_Sft_Btn_status 1;
BA_ "FlexKomSigName" SG_ 817 Launch_Sft_Btn_status "Launch_Sft_Btn_status";
BA_ "FlexKomComment" SG_ 817 Launch_Sft_Btn_status "Launch - soft button status; Launch on = [1]";
BA_ "FlexKomIsMotorola" SG_ 817 Launch_Sft_Btn_status 1;
BA_ "GenSigSNA" SG_ 817 Launch_Sft_Btn_status "0h";
BA_ "GenSigSendType" SG_ 817 PSI_Gr2_RPM_SET 5;
BA_ "GenSigCycleTime" SG_ 817 PSI_Gr2_RPM_SET 1000;
BA_ "FlexKomSigStartValue" SG_ 817 PSI_Gr2_RPM_SET "00h";
BA_ "FlexKomSID" SG_ 817 PSI_Gr2_RPM_SET 2053;
BA_ "FlexKomSigStartPos" SG_ 817 PSI_Gr2_RPM_SET 12;
BA_ "FlexKomSigLaenge" SG_ 817 PSI_Gr2_RPM_SET 5;
BA_ "FlexKomSigName" SG_ 817 PSI_Gr2_RPM_SET "PSI_Gr2_RPM_SET";
BA_ "FlexKomComment" SG_ 817 PSI_Gr2_RPM_SET "Requested rpm set point for Performance Shift Indi";
BA_ "FlexKomIsMotorola" SG_ 817 PSI_Gr2_RPM_SET 1;
BA_ "GenSigSNA" SG_ 817 PSI_Gr2_RPM_SET "1Fh";
BA_ "GenSigSendType" SG_ 817 HP_MODE_SEL 5;
BA_ "GenSigCycleTime" SG_ 817 HP_MODE_SEL 1000;
BA_ "FlexKomSigStartValue" SG_ 817 HP_MODE_SEL "00h";
BA_ "GenSigTimeout_IC" SG_ 817 HP_MODE_SEL 10500;
BA_ "FlexKomSID" SG_ 817 HP_MODE_SEL 2014;
BA_ "FlexKomSigStartPos" SG_ 817 HP_MODE_SEL 15;
BA_ "FlexKomSigLaenge" SG_ 817 HP_MODE_SEL 3;
BA_ "FlexKomSigName" SG_ 817 HP_MODE_SEL "HP_MODE_SEL";
BA_ "FlexKomComment" SG_ 817 HP_MODE_SEL "Engine power mode personalization request";
BA_ "FlexKomIsMotorola" SG_ 817 HP_MODE_SEL 1;
BA_ "GenSigSNA" SG_ 817 HP_MODE_SEL "7h";
BA_ "GenSigSendType" SG_ 817 PSI_Gr3_RPM_SET 5;
BA_ "GenSigCycleTime" SG_ 817 PSI_Gr3_RPM_SET 1000;
BA_ "FlexKomSigStartValue" SG_ 817 PSI_Gr3_RPM_SET "00h";
BA_ "FlexKomSID" SG_ 817 PSI_Gr3_RPM_SET 2054;
BA_ "FlexKomSigStartPos" SG_ 817 PSI_Gr3_RPM_SET 20;
BA_ "FlexKomSigLaenge" SG_ 817 PSI_Gr3_RPM_SET 5;
BA_ "FlexKomSigName" SG_ 817 PSI_Gr3_RPM_SET "PSI_Gr3_RPM_SET";
BA_ "FlexKomComment" SG_ 817 PSI_Gr3_RPM_SET "Requested rpm set point for Performance Shift Indi";
BA_ "FlexKomIsMotorola" SG_ 817 PSI_Gr3_RPM_SET 1;
BA_ "GenSigSNA" SG_ 817 PSI_Gr3_RPM_SET "1Fh";
BA_ "GenSigSendType" SG_ 817 Eng_DrvMdRq 5;
BA_ "GenSigCycleTime" SG_ 817 Eng_DrvMdRq 1000;
BA_ "FlexKomSigStartValue" SG_ 817 Eng_DrvMdRq "00h";
BA_ "FlexKomSID" SG_ 817 Eng_DrvMdRq 2116;
BA_ "FlexKomSigStartPos" SG_ 817 Eng_DrvMdRq 23;
BA_ "FlexKomSigLaenge" SG_ 817 Eng_DrvMdRq 3;
BA_ "FlexKomSigName" SG_ 817 Eng_DrvMdRq "Eng_DrvMdRq";
BA_ "FlexKomComment" SG_ 817 Eng_DrvMdRq "Engine drive mode personalization request";
BA_ "FlexKomIsMotorola" SG_ 817 Eng_DrvMdRq 1;
BA_ "GenSigSNA" SG_ 817 Eng_DrvMdRq "7h";
BA_ "GenSigSendType" SG_ 817 PSI_Gr4_RPM_SET 5;
BA_ "GenSigCycleTime" SG_ 817 PSI_Gr4_RPM_SET 1000;
BA_ "FlexKomSigStartValue" SG_ 817 PSI_Gr4_RPM_SET "00h";
BA_ "FlexKomSID" SG_ 817 PSI_Gr4_RPM_SET 2055;
BA_ "FlexKomSigStartPos" SG_ 817 PSI_Gr4_RPM_SET 28;
BA_ "FlexKomSigLaenge" SG_ 817 PSI_Gr4_RPM_SET 5;
BA_ "FlexKomSigName" SG_ 817 PSI_Gr4_RPM_SET "PSI_Gr4_RPM_SET";
BA_ "FlexKomComment" SG_ 817 PSI_Gr4_RPM_SET "Requested rpm set point for Performance Shift Indi";
BA_ "FlexKomIsMotorola" SG_ 817 PSI_Gr4_RPM_SET 1;
BA_ "GenSigSNA" SG_ 817 PSI_Gr4_RPM_SET "1Fh";
BA_ "GenSigSendType" SG_ 817 PSI_Gr5_RPM_SET 5;
BA_ "GenSigCycleTime" SG_ 817 PSI_Gr5_RPM_SET 1000;
BA_ "FlexKomSigStartValue" SG_ 817 PSI_Gr5_RPM_SET "00h";
BA_ "FlexKomSID" SG_ 817 PSI_Gr5_RPM_SET 2056;
BA_ "FlexKomSigStartPos" SG_ 817 PSI_Gr5_RPM_SET 36;
BA_ "FlexKomSigLaenge" SG_ 817 PSI_Gr5_RPM_SET 5;
BA_ "FlexKomSigName" SG_ 817 PSI_Gr5_RPM_SET "PSI_Gr5_RPM_SET";
BA_ "FlexKomComment" SG_ 817 PSI_Gr5_RPM_SET "Requested rpm set point for Performance Shift Indi";
BA_ "FlexKomIsMotorola" SG_ 817 PSI_Gr5_RPM_SET 1;
BA_ "GenSigSNA" SG_ 817 PSI_Gr5_RPM_SET "1Fh";
BA_ "GenSigSendType" SG_ 817 PSI_Rq 5;
BA_ "GenSigCycleTime" SG_ 817 PSI_Rq 1000;
BA_ "FlexKomSigStartValue" SG_ 817 PSI_Rq "00h";
BA_ "FlexKomSID" SG_ 817 PSI_Rq 2115;
BA_ "FlexKomSigStartPos" SG_ 817 PSI_Rq 38;
BA_ "FlexKomSigLaenge" SG_ 817 PSI_Rq 2;
BA_ "FlexKomSigName" SG_ 817 PSI_Rq "PSI_Rq";
BA_ "FlexKomComment" SG_ 817 PSI_Rq "Performance shift indication request";
BA_ "FlexKomIsMotorola" SG_ 817 PSI_Rq 1;
BA_ "GenSigSNA" SG_ 817 PSI_Rq "3h";
BA_ "GenSigSendType" SG_ 817 PSI_RPM_Reset 5;
BA_ "GenSigCycleTime" SG_ 817 PSI_RPM_Reset 1000;
BA_ "FlexKomSigStartValue" SG_ 817 PSI_RPM_Reset "00h";
BA_ "FlexKomSID" SG_ 817 PSI_RPM_Reset 2114;
BA_ "FlexKomSigStartPos" SG_ 817 PSI_RPM_Reset 39;
BA_ "FlexKomSigLaenge" SG_ 817 PSI_RPM_Reset 1;
BA_ "FlexKomSigName" SG_ 817 PSI_RPM_Reset "PSI_RPM_Reset";
BA_ "FlexKomComment" SG_ 817 PSI_RPM_Reset "Reset performance shift indication RPM set points ";
BA_ "FlexKomIsMotorola" SG_ 817 PSI_RPM_Reset 1;
BA_ "GenSigSNA" SG_ 817 PSI_RPM_Reset "0h";
BA_ "GenSigSendType" SG_ 817 Launch_RPM_Selected_Setting 5;
BA_ "GenSigCycleTime" SG_ 817 Launch_RPM_Selected_Setting 1000;
BA_ "FlexKomSigStartValue" SG_ 817 Launch_RPM_Selected_Setting "1Eh";
BA_ "GenSigStartValue" SG_ 817 Launch_RPM_Selected_Setting 30;
BA_ "FlexKomSID" SG_ 817 Launch_RPM_Selected_Setting 2065;
BA_ "FlexKomSigStartPos" SG_ 817 Launch_RPM_Selected_Setting 44;
BA_ "FlexKomSigLaenge" SG_ 817 Launch_RPM_Selected_Setting 5;
BA_ "FlexKomSigName" SG_ 817 Launch_RPM_Selected_Setting "Launch_RPM_Selected_Setting";
BA_ "FlexKomComment" SG_ 817 Launch_RPM_Selected_Setting "Soft button driver selected RPM setting";
BA_ "FlexKomIsMotorola" SG_ 817 Launch_RPM_Selected_Setting 1;
BA_ "GenSigSNA" SG_ 817 Launch_RPM_Selected_Setting "1Fh";
VAL_ 773 TPM_IndLmpOnRq 3 "SNA" 2 "IND_LMP_FLASH" 1 "IND_LMP_ON" 0 "IND_LMP_OFF" ;
VAL_ 773 TPM_SwchIndRq 3 "SNA" 2 "SW_IND_LMP_FLASH" 1 "SW_IND_LMP_ON" 0 "SW_IND_LMP_OFF" ;
VAL_ 773 TPM_SysStat 7 "SNA" 3 "TPM_NA" 2 "LOCALIZATION_CMPLT" 1 "PERF_LOCALIZATION" 0 "NON_LOCALIZED" ;
VAL_ 773 Tire_FL 3 "SNA" 2 "HIGH" 1 "LOW" 0 "NORMAL" ;
VAL_ 773 Tire_FR 3 "SNA" 2 "HIGH" 1 "LOW" 0 "NORMAL" ;
VAL_ 773 Tire_RR 3 "SNA" 2 "HIGH" 1 "LOW" 0 "NORMAL" ;
VAL_ 773 Tire_RL 3 "SNA" 2 "HIGH" 1 "LOW" 0 "NORMAL" ;
VAL_ 773 Tire_Spr 3 "SNA" 2 "HIGH" 1 "LOW" 0 "NORMAL" ;
VAL_ 773 TirePrssFL 255 "SNA" ;
VAL_ 773 TirePrssFR 255 "SNA" ;
VAL_ 773 TirePrssRL 255 "SNA" ;
VAL_ 773 TirePrssRR 255 "SNA" ;
VAL_ 773 TirePrssSpr 255 "SNA" ;
VAL_ 774 Tire_RR2 3 "SNA" 2 "HIGH" 1 "LOW" 0 "NORMAL" ;
VAL_ 774 Tire_RL2 3 "SNA" 2 "HIGH" 1 "LOW" 0 "NORMAL" ;
VAL_ 774 TirePrssRL2 255 "SNA" ;
VAL_ 774 TirePrssRR2 255 "SNA" ;
VAL_ 776 TCASE_SRV_RQ 3 "SNA" 2 "BLINK" 1 "ON" 0 "OFF" ;
VAL_ 776 Tcase4Lock 3 "SNA" 2 "BLINK" 1 "ON" 0 "OFF" ;
VAL_ 776 Tcase4Low 3 "SNA" 2 "BLINK" 1 "ON" 0 "OFF" ;
VAL_ 776 TcaseNtrlStat 3 "SNA" 2 "BLINK" 1 "ON" 0 "OFF" ;
VAL_ 776 TcaseAWD 3 "SNA" 2 "BLINK" 1 "ON" 0 "OFF" ;
VAL_ 776 CNT_DIFF_MOD 3 "SNA" 2 "ESP" 1 "LM" 0 "FREE" ;
VAL_ 776 Tcase2WD_Stat 3 "SNA" 2 "BLINK" 1 "ON" 0 "OFF" ;
VAL_ 776 TerSt_LED3 3 "SNA" 2 "BLINK" 1 "CONT" 0 "OFF" ;
VAL_ 776 TerSt_LED1 3 "SNA" 2 "BLINK" 1 "CONT" 0 "OFF" ;
VAL_ 776 TerSt_LED2 3 "SNA" 2 "BLINK" 1 "CONT" 0 "OFF" ;
VAL_ 776 TerSt_LED5 3 "SNA" 2 "BLINK" 1 "CONT" 0 "OFF" ;
VAL_ 776 TerSt_LED4 3 "SNA" 2 "BLINK" 1 "CONT" 0 "OFF" ;
VAL_ 776 TerMdStat 15 "SNA" 11 "MUD" 10 "SAND" 9 "MUD_SAND" 8 "SPORT" 7 "ALL_ROAD" 6 "I_C_E" 5 "NORMAL" 4 "SNOW" 3 "TOW" 2 "ROCK" 1 "TRACK" 0 "AUTO" ;
VAL_ 776 DTCM_HMI_Rq 31 "SNA" 14 "SCREEN_14" 13 "SCREEN_13" 12 "SCREEN_12" 11 "SCREEN_11" 10 "SCREEN_10" 9 "SCREEN_9" 8 "SCREEN_8" 7 "SCREEN_7" 6 "SCREEN_6" 5 "SCREEN_5" 4 "SCREEN_4" 3 "SCREEN_3" 2 "SCREEN_2" 1 "SCREEN_1" 0 "NONE" ;
VAL_ 778 WTS_CntDnTmr 255 "SNA" ;
VAL_ 778 EB_Stat3 7 "SNA" 5 "EB_SMART" 4 "EB_HVY" 3 "EB_MED" 2 "EB_LT" 1 "EB_ON" 0 "EB_OFF" ;
VAL_ 778 DrtdTrqMd 3 "MESS3" 2 "MESS2" 1 "MESS1" 0 "NM" ;
VAL_ 778 EngBrkStat 3 "SNA" 2 "EB_RQ" 1 "EB_ENBL" 0 "EB_OFF" ;
VAL_ 778 TrboBstPress 255 "SNA" ;
VAL_ 778 EB_Pwr 255 "SNA" ;
VAL_ 779 DisOilLifeRst 65535 "SNA" ;
VAL_ 779 OilLifeLeft 255 "SNA" ;
VAL_ 779 HoursOilLifeRst 4095 "SNA" ;
VAL_ 779 MntncSts 3 "SNA" 2 "NOW" 1 "SOON" 0 "NONE" ;
VAL_ 783 VehPerfAccelPeak_X_Pos 511 "SNA" ;
VAL_ 783 VehPerfAccelPeak_X_Neg 511 "SNA" ;
VAL_ 783 VehPerfAccelPeak_Y_Pos 511 "SNA" ;
VAL_ 783 VehPerfAccelPeak_Y_Neg 511 "SNA" ;
VAL_ 784 AvgFuelLvl 511 "SNA" ;
VAL_ 784 PCODE_CTRL 3 "SNA" 2 "DISP_CODE" 1 "SEND_CODE" 0 "NO_CODE" ;
VAL_ 784 SRS_LMP_STAT 3 "SNA" 2 "SRS_LMP_ON_IC" 1 "SRS_LMP_ON" 0 "SRS_LMP_OFF" ;
VAL_ 784 DPF_DEF_WrnStat 15 "SNA" 4 "DEF_WARN" 3 "DPF_WARN" 2 "INT_WARN" 1 "NON_WARN" 0 "NO_WARN" ;
VAL_ 784 ODO 16777215 "SNA" ;
VAL_ 784 PowerMode_RQ 7 "SNA" 3 "ABBR" 2 "SHIP" 1 "STORAGE" 0 "CUSTOMER" ;
VAL_ 784 PTS_MODE_SELECTION 7 "SNA" 4 "OVER" 3 "PULL_OUT" 2 "PERP" 1 "PARA" 0 "None" ;
VAL_ 788 CFG_FEATURE 105 "CFG_CHMSL_LINES" 104 "CFG_EPS" 103 "CFG_TorqueUnit" 102 "CFG_PowerUnit" 101 "CFG_TemperatureUnit" 100 "CFG_CapacityUnit" 99 "CFG_ConsumptionUnit" 98 "CFG_DistanceUnit" 97 "CFG_SpeedUnit" 96 "CFG_PressureUnit" 95 "CFG_UNIT_DEFAULT" 94 "CFG_PTO_REM_Throttle" 93 "CFG_LDWTRQ" 91 "CFG_AUX5" 90 "CFG_AUX4" 89 "CFG_AUX3" 88 "CFG_AUX2" 87 "CFG_AUX1" 86 "CFG_PLG" 84 "CFG_PTS_RR_VOL" 83 "CFG_PTS_FT_VOL" 82 "CFG_PTS_RR" 81 "CFG_PTS_FT" 77 "CFG_TRLR_NAME" 76 "CFG_TRLR_TYP" 73 "RLE_HORN" 72 "RLE_LIGHT" 71 "DIMMER" 70 "RVC_GRID" 69 "CFG_MAX_PTO_VEH_SPEED" 68 "CFG_PTO_Auto_Resume" 67 "CFG_PTO_Type" 66 "CFG_PTO_RPM3" 65 "CFG_PTO_RPM2" 64 "CFG_PTO_RPM1" 63 "CFG_PTO_SINGLE_RPM" 62 "CFG_PTO_MODE" 61 "CFG_TRANSPORT" 59 "CFG_NORMAL_DCS" 58 "OIL" 57 "CFG_LDW" 55 "CFG_ASCM_WMO" 54 "CFG_ALIGNMENT" 53 "CFG_TRLR" 52 "JACK" 51 "AERO" 50 "PASS_WIN_LKOUT" 49 "CFG_ECMM" 48 "CFG_HDLP_DROP" 47 "CFG_FCW_SENS" 46 "CFG_FUEL_SAV" 45 "CFG_BELT_SLAK" 44 "CFG_PRE_SAFE" 43 "CFG_FCW" 42 "CFG_CMS" 41 "CFG_AUTO_RELK" 40 "CFG_DCS" 39 "CFG_SOUND_RS" 38 "CFG_DSS" 37 "CFG_WAL" 36 "CFG_PE" 35 "CFG_BSD" 34 "CFG_AFS" 33 "CFG_HILL_ST" 32 "CFG_NAV_TBYT" 31 "CFG_VOICE_COMF" 30 "CFG_CMP_VAR" 29 "CFG_CMP_CAL" 28 "REST_FACT_DEF" 27 "CFG_AHB" 26 "CFG_DRL_ON" 25 "CFG_GLBL_DN_WIN" 24 "CFG_GLBL_UP_WIN" 23 "CFG_ILL_ENTRY" 22 "CFG_ILL_APRCH" 21 "CFG_TILT_IN_REV" 20 "CFG_LO_VEH" 19 "CFG_EASY_EXIT" 18 "CFG_REM_MEM" 16 "CFG_ACC_DLY" 15 "CFG_HL_WPR" 14 "CFG_HL_DLY" 13 "CFG_AUTO_WPR" 12 "CFG_SRV_INTV" 11 "CFG_US_METRIC" 10 "CFG_LANG" 9 "CFG_PARK_ASSIST" 8 "CFG_DrAlrPrsnt" 7 "CFG_FLASH_LK" 6 "CFG_HORN_DUR" 5 "CFG_SOUND_LK" 4 "CFG_DRV_FST" 3 "CFG_DLY_LK" 2 "CFG_AUTO_UNLK" 1 "CFG_AUTO_LK" 0 "CFG_NONE" ;
VAL_ 788 CFG_STAT_RQ 3 "CFG_SPEC" 2 "CFG_ENBL" 1 "CFG_DSBL" 0 "CFG_DEF" ;
VAL_ 789 CfgFeature 6 "CFG_StopStart" 5 "WIPER_SP" 4 "PASS_AB_RQ_STAT" 3 "EPB_OFF" 2 "TPM_RESET" 1 "ABEV" 0 "CFG_NONE" ;
VAL_ 789 CfgStatRq 3 "CFG_SPEC" 2 "CFG_ENBL" 1 "CFG_DSBL" 0 "CFG_DEF" ;
VAL_ 790 CFG_FEATURE_C 105 "CFG_CHMSL_LINES" 104 "CFG_EPS" 103 "CFG_TorqueUnit" 102 "CFG_PowerUnit" 101 "CFG_TemperatureUnit" 100 "CFG_CapacityUnit" 99 "CFG_ConsumptionUnit" 98 "CFG_DistanceUnit" 97 "CFG_SpeedUnit" 96 "CFG_PressureUnit" 95 "CFG_UNIT_DEFAULT" 94 "CFG_PTO_REM_Throttle" 93 "CFG_LDWTRQ" 91 "CFG_AUX5" 90 "CFG_AUX4" 89 "CFG_AUX3" 88 "CFG_AUX2" 87 "CFG_AUX1" 86 "CFG_PLG" 84 "CFG_PTS_RR_VOL" 83 "CFG_PTS_FT_VOL" 82 "CFG_PTS_RR" 81 "CFG_PTS_FT" 77 "CFG_TRLR_NAME" 76 "CFG_TRLR_TYP" 73 "RLE_HORN" 72 "RLE_LIGHT" 71 "DIMMER" 70 "RVC_GRID" 69 "CFG_MAX_PTO_VEH_SPEED" 68 "CFG_PTO_Auto_Resume" 67 "CFG_PTO_Type" 66 "CFG_PTO_RPM3" 65 "CFG_PTO_RPM2" 64 "CFG_PTO_RPM1" 63 "CFG_PTO_SINGLE_RPM" 62 "CFG_PTO_MODE" 61 "CFG_TRANSPORT" 59 "CFG_NORMAL_DCS" 58 "OIL" 57 "CFG_LDW" 55 "CFG_ASCM_WMO" 54 "CFG_ALIGNMENT" 53 "CFG_TRLR" 52 "JACK" 51 "AERO" 50 "PASS_WIN_LKOUT" 49 "CFG_ECMM" 48 "CFG_HDLP_DROP" 47 "CFG_FCW_SENS" 46 "CFG_FUEL_SAV" 45 "CFG_BELT_SLAK" 44 "CFG_PRE_SAFE" 43 "CFG_FCW" 42 "CFG_CMS" 41 "CFG_AUTO_RELK" 40 "CFG_DCS" 39 "CFG_SOUND_RS" 38 "CFG_DSS" 37 "CFG_WAL" 36 "CFG_PE" 35 "CFG_BSD" 34 "CFG_AFS" 33 "CFG_HILL_ST" 32 "CFG_NAV_TBYT" 31 "CFG_VOICE_COMF" 30 "CFG_CMP_VAR" 29 "CFG_CMP_CAL" 28 "REST_FACT_DEF" 27 "CFG_AHB" 26 "CFG_DRL_ON" 25 "CFG_GLBL_DN_WIN" 24 "CFG_GLBL_UP_WIN" 23 "CFG_ILL_ENTRY" 22 "CFG_ILL_APRCH" 21 "CFG_TILT_IN_REV" 20 "CFG_LO_VEH" 19 "CFG_EASY_EXIT" 18 "CFG_REM_MEM" 16 "CFG_ACC_DLY" 15 "CFG_HL_WPR" 14 "CFG_HL_DLY" 13 "CFG_AUTO_WPR" 12 "CFG_SRV_INTV" 11 "CFG_US_METRIC" 10 "CFG_LANG" 9 "CFG_PARK_ASSIST" 8 "CFG_DrAlrPrsnt" 7 "CFG_FLASH_LK" 6 "CFG_HORN_DUR" 5 "CFG_SOUND_LK" 4 "CFG_DRV_FST" 3 "CFG_DLY_LK" 2 "CFG_AUTO_UNLK" 1 "CFG_AUTO_LK" 0 "CFG_NONE" ;
VAL_ 790 CFG_STAT_RQ_C 3 "CFG_SPEC" 2 "CFG_ENBL" 1 "CFG_DSBL" 0 "CFG_DEF" ;
VAL_ 792 TurnIndLvr_Stat 2 "RIGHT" 1 "LEFT" 0 "IDLE" ;
VAL_ 792 HiBmLvr_Stat 2 "HIBM_FLSH_ON_PSD" 1 "HIBM_ON_PSD" 0 "IDLE" ;
VAL_ 792 WprWashSw_Psd 2 "WASH" 1 "MIST" 0 "NPSD" ;
VAL_ 792 WprWash_R_Sw_Posn_V3 3 "CONSTANT" 2 "WASH" 1 "INTERMITTENT" 0 "OFF" ;
VAL_ 792 StW_Lvr_Stat 4 "STW_BACK" 3 "STW_FWD" 2 "STW_DOWN" 1 "STW_UP" 0 "NPSD" ;
VAL_ 792 WprSw6Posn 15 "SNA" 14 "WPR_HI" 13 "WPR_LOW" 6 "INTERVAL6" 5 "INTERVAL5" 4 "INTERVAL4" 3 "INTERVAL3" 2 "INTERVAL2" 1 "INTERVAL1" 0 "OFF" ;
VAL_ 796 DRV_RBT_Fault 1 "SNA" ;
VAL_ 796 DRV_RBT_ACT 3 "SNA" 2 "ACT_ESC" 1 "ACT_DASM" 0 "DEFAULT" ;
VAL_ 799 IBS_R_Batt 2047 "SNA" ;
VAL_ 799 IBS_R_Batt_25 2047 "SNA" ;
VAL_ 799 Trns_DrvMdReq 7 "SNA" 6 "ECO" 5 "TRACK" 4 "S_PLUS" 3 "SPORT" 2 "VALET" 1 "STREET" 0 "NP" ;
VAL_ 799 EPS_MODE_REQ 7 "SNA" 3 "LAST" 2 "MODE_3" 1 "MODE_2" 0 "MODE_1" ;
VAL_ 799 ADS_MODE_REQ 7 "SNA" 6 "MODE_3" 5 "MODE_2" 4 "MODE_1" 3 "DM3" 2 "DM2" 1 "DM1" 0 "DEFAULT" ;
VAL_ 799 PaddlesModeReq 3 "SNA" 2 "EN" 1 "DIS" 0 "NONE" ;
VAL_ 799 ESC_Sft_btn_status 7 "SNA" 4 "NOT_PRESSED" 3 "OFF" 2 "PARTIAL_2" 1 "PARTIAL_1" 0 "ON" ;
VAL_ 800 PSI_Max_RPM 31 "SNA" ;
VAL_ 804 MOOD_LGT_INTS 255 "SNA" ;
VAL_ 804 AirSusp_UpSw 3 "SNA" 1 "PSD" 0 "NOT_PSD" ;
VAL_ 804 AirSusp_DnSw 3 "SNA" 1 "PSD" 0 "NOT_PSD" ;
VAL_ 804 SpStSwPsd 3 "SNA" 1 "PSD" 0 "NOT_PSD" ;
VAL_ 804 HL_SW_Position 3 "HL_Auto" 2 "HL_On" 1 "HL_Park" 0 "HL_Off" ;
VAL_ 804 ML_HDLP_LVL 3 "LVL_3" 2 "LVL_2" 1 "LVL_1" 0 "LVL_0" ;
VAL_ 804 RemSt_Inhibit 255 "SNA" 39 "ETC_LAMP_ON" 38 "LOW_FUEL" 37 "GLOW_PLUG_TIMEOUT" 36 "IGN_NOT_LOCK" 35 "IGN_SNA" 34 "INVALID_SKIM_KEY" 33 "NOT_ENABLED" 32 "NO_AUTO_TRANS" 31 "NO_HOOD_SWITCH" 30 "NOT_CONFIGURED" 29 "RS_DISABLED_PREV" 28 "REMOTE_OFF_RQ" 27 "CRANK_NO_START" 26 "RPM_HIGH" 25 "COOLANT_TEMP_HIGH" 24 "OIL_PRESSURE_LOW" 23 "MIL_ON" 22 "POWER_LOSS" 21 "BATT_VOLT_LOW" 20 "BATT_VOLT_HIGH" 19 "PANIC_MODE" 18 "VTA_ALARM" 17 "TRUNK_LIFTGATE" 16 "HOOD_AJAR" 15 "VEH_SPEED_HIGH" 14 "NOT_IN_PARK" 13 "HAZARD_LAMP_ON" 12 "BRAKE_PRESSED" 11 "KEY_IN_IGN" 10 "LOW_RPM_SHUTDOWN" 9 "FAIL_COUNTER" 8 "START_COUNTER" 7 "RR_DOOR_AJAR" 6 "LR_DOOR_AJAR" 5 "PASS_DOOR_AJAR" 4 "DRV_DOOR_AJAR" 3 "KEY_IN_RUN" 2 "TIME_OUT_CUST_MODE" 1 "TIME_OUT_RUN" 0 "INHIBIT_DEFAUILT" ;
VAL_ 804 WPR_SYS_OFF 1 "SNA" ;
VAL_ 804 WPR_SYS_LOW 0 "SNA" ;
VAL_ 804 WPR_SYS_HIGH 0 "SNA" ;
VAL_ 804 WPR_SYS_INT 0 "SNA" ;
VAL_ 804 WPR_SYS_AUTO 0 "SNA" ;
VAL_ 804 WPR_SYS_MIST 0 "SNA" ;
VAL_ 804 WPR_SYS_WASH 0 "SNA" ;
VAL_ 804 WPR_SYS_FLT 0 "SNA" ;
VAL_ 804 Court_Lmp 255 "SNA" ;
VAL_ 804 DriveStyleSts 7 "SNA" 5 "TRACPLUS" 4 "SPORT_PLUS" 3 "WINTER" 2 "SPORT" 1 "CITY" 0 "NORMAL" ;
VAL_ 804 DrvMdRq 7 "SNA" 5 "TRACPLUS" 4 "SPORT_PLUS" 3 "WINTER" 2 "SPORT" 1 "CITY" 0 "NORMAL" ;
VAL_ 804 ManMdRq 3 "SNA" 1 "PSD" 0 "NOT_PSD" ;
VAL_ 806 AFLS_Stat 3 "F_HS" 2 "F_HL" 1 "ENABLED" 0 "DISABLED" ;
VAL_ 806 HLDrpStat 3 "SNA" 2 "NA" 1 "LOW" 0 "NORMAL" ;
VAL_ 806 ExtdLgtStat 3 "SNA" 1 "EXTD" 0 "NORMAL" ;
VAL_ 808 TGW_GrpTyp_IC 63 "SNA" 0 "NO_TEXT" ;
VAL_ 810 PTO_Md 7 "SNA" 3 "REMOTE" 2 "MOBILE" 0 "STANDARD" ;
VAL_ 810 PTO_MaxVehSpd 31 "SNA" 30 "NINTY" 29 "EIGHTY_FIVE" 28 "EIGHTY" 27 "SEVENTY_FIVE" 26 "SEVENTY" 25 "SIXTY_FIVE" 24 "SIXTY" 23 "FIFTY_FIVE" 22 "FIFTY" 21 "FOURTY_FIVE" 20 "FOURTY" 19 "THIRTY_FIVE" 18 "THIRTY" 17 "TWENTY_FIVE" 16 "TWENTY" 15 "NINETEEN" 14 "EIGHTEEN" 13 "SEVENTEEN" 12 "SIXTEEN" 11 "FIFTEEN" 10 "FOURTEEN" 9 "THIRTEEN" 8 "TWELVE" 7 "ELEVEN" 6 "TEN" 5 "NINE" 4 "EIGHT" 3 "SEVEN" 2 "SIX" 1 "FIVE" 0 "ZERO" ;
VAL_ 810 PTO_AutoRsm 1 "ENABLE" 0 "DISABLE" ;
VAL_ 810 PTO_TYPES 3 "SNA" 1 "SPLIT" 0 "AUX" ;
VAL_ 810 PTO_SingleRPM 255 "SNA" ;
VAL_ 810 PTO_RPM1 255 "SNA" ;
VAL_ 810 PTO_RPM2 255 "SNA" ;
VAL_ 810 PTO_RPM3 255 "SNA" ;
VAL_ 810 PTO_Sts 31 "SNA" 14 "COLD" 13 "RPM_A900" 12 "RPM_L1000" 11 "SPEED_LT2" 10 "DRIVE" 9 "TC_2WD" 8 "FB_SWITCH" 7 "NEUTRAL" 6 "PARK" 5 "REL_CLUTCH" 4 "REL_ACC" 3 "REL_BRAKE" 2 "SET_BRAKE" 1 "PTO_ON" 0 "PTO_OFF" ;
VAL_ 810 HP_MODE_STS 7 "SNA" 3 "RED" 2 "BLACK" 1 "VALET" 0 "NONE" ;
VAL_ 810 FuelTransSts 7 "M7" 6 "M6" 5 "M5" 4 "M4" 3 "M3" 2 "M2" 1 "M1" 0 "NONE" ;
VAL_ 811 AxlLckrSts 3 "SNA" 2 "FR_RR_LKD" 1 "RR_LKD" 0 "UNLOCKED" ;
VAL_ 811 SwayBarSts 3 "SNA" 2 "S_I_P" 1 "LOCKED" 0 "UNLOCKED" ;
VAL_ 811 AxleLockerEVICDisplay 15 "SNA" 9 "SCREEN_9" 8 "SCREEN_8" 7 "SCREEN_7" 6 "SCREEN_6" 5 "SCREEN_5" 4 "SCREEN_4" 3 "SCREEN_3" 2 "SCREEN_2" 1 "SCREEN_1" 0 "NONE" ;
VAL_ 811 Swaybar_EVICDisplay 15 "SNA" 7 "SCREEN_7" 6 "SCREEN_6" 5 "SCREEN_5" 4 "SCREEN_4" 3 "SCREEN_3" 2 "SCREEN_2" 1 "SCREEN_1" 0 "NONE" ;
VAL_ 816 PLG_Stat 15 "SNA" 8 "HOT" 7 "COLD" 6 "MAN_CLS" 5 "OBS_DET" 4 "CLS_FG" 3 "DSBL" 2 "PK" 1 "UNLK" 0 "OK" ;
VAL_ 816 DL_Lim_Stat 3 "SNA" 2 "NDEF2" 1 "ON" 0 "OFF" ;
VAL_ 816 EModeSwPsd 3 "SNA" 2 "SW_PSD" 1 "SW_NOT_PSD" 0 "DEFAULT" ;
VAL_ 816 ADCM_Sw_Psd 0 "SNA" ;
VAL_ 816 TCASE_SFT_RQ 7 "SNA" 6 "TC_NTRL" 5 "TC_AWD" 4 "TC_2WD" 3 "TC_FOUR_HI" 2 "TC_FOUR_LO" 1 "PSD" 0 "NOT_PSD" ;
VAL_ 816 HILL_DES_RQ 3 "SNA" 1 "PSD" 0 "NOT_PSD" ;
VAL_ 816 LANG 15 "LANG_NO_CHG" 14 "MANDARIN_T" 12 "ARABIC" 11 "KOREAN" 10 "RUSSIAN" 9 "MANDARIN_S" 8 "UK_ENGLISH" 7 "DUTCH" 6 "PORTUGESE" 5 "JAPANESE" 4 "SPANISH" 3 "ITALIAN" 2 "FRENCH" 1 "US_ENGLISH" 0 "GERMAN" ;
VAL_ 816 TGW_DISP_STAT 15 "SNA" 14 "ISP_DTV_CAMERA" 13 "ISP_DTV_Video" 12 "ISP_DTV_PRGM" 11 "DISP_VES_VIDEO" 10 "DISP_VES_HMI" 9 "DISP_SPLSH" 8 "ON_BLANK" 7 "DISP_REAR_CAMERA" 6 "DISP_MD_SEL" 5 "DISP_DVD_DISP" 4 "DISP_DVD_SETUP" 3 "DISP_DVD_MENU" 2 "DISP_NORMAL" 1 "DISP_CLS" 0 "DISP_OFF" ;
VAL_ 816 HVAC_CLNT_FLW_MIN 255 "SNA" ;
VAL_ 816 ICS_btn41 3 "SNA" 2 "STUCK" 1 "PRESSED" 0 "NOT_PRESSED" ;
VAL_ 816 DriveModeReq_Cluster 15 "SNA" 8 "CUST" 7 "ECO" 6 "TRACK" 5 "SPORT_ECO" 4 "SPORT" 3 "VALET" 2 "TRACK_ECO" 1 "Street" 0 "NP" ;
VAL_ 817 PSI_Gr1_RPM_SET 31 "SNA" ;
VAL_ 817 ICS_launch_hardbtn_status 3 "SNA" 2 "STUCK" 1 "PRESSED" 0 "NOT_PRESSED" ;
VAL_ 817 PSI_Gr2_RPM_SET 31 "SNA" ;
VAL_ 817 HP_MODE_SEL 7 "SNA" 3 "RED" 2 "BLACK" 1 "VALET" 0 "NONE" ;
VAL_ 817 PSI_Gr3_RPM_SET 31 "SNA" ;
VAL_ 817 Eng_DrvMdRq 7 "SNA" 4 "SPORT_PLUS" 3 "TRACK" 2 "SPORT" 1 "ECO" 0 "NORMAL" ;
VAL_ 817 PSI_Gr4_RPM_SET 31 "SNA" ;
VAL_ 817 PSI_Gr5_RPM_SET 31 "SNA" ;
VAL_ 817 PSI_Rq 3 "SNA" 2 "ENABLE" 1 "DISABLE" 0 "NONE" ;
VAL_ 817 Launch_RPM_Selected_Setting 31 "SNA" ;
